// *************************************************************************** *
// *                                                                           *
// *                      Mentor Graphics Corporation                          *
// *                          All rights reserved                              *
// *                                                                           *
// *************************************************************************** *
// *                                                                           *
// * Description:         CANDB File                                           *
// * Generated at:        2022-07-01 13:40                                     *
// * System:              ZSDB122200                                           *
// * Variant:             DC1E_EU                                              *
// * Network:             BodyExposedCAN                                       *
// *                                                                           *
// *************************************************************************** *
// *                                                                           *
// *             THIS CONFIGURATION MIGHT CONTAIN SOME ERRORS                  *
// *              IF THE INPUT MODEL WAS NOT PROPERLY FORMED!                  *
// *                    Do Not Use this File directly!                         *
// *                                                                           *
// *************************************************************************** *
VERSION "BodyExposedCAN"

NS_ :

BS_ :

BU_ :  CEM ETC HCML HCMR RCML RCMM RCMR

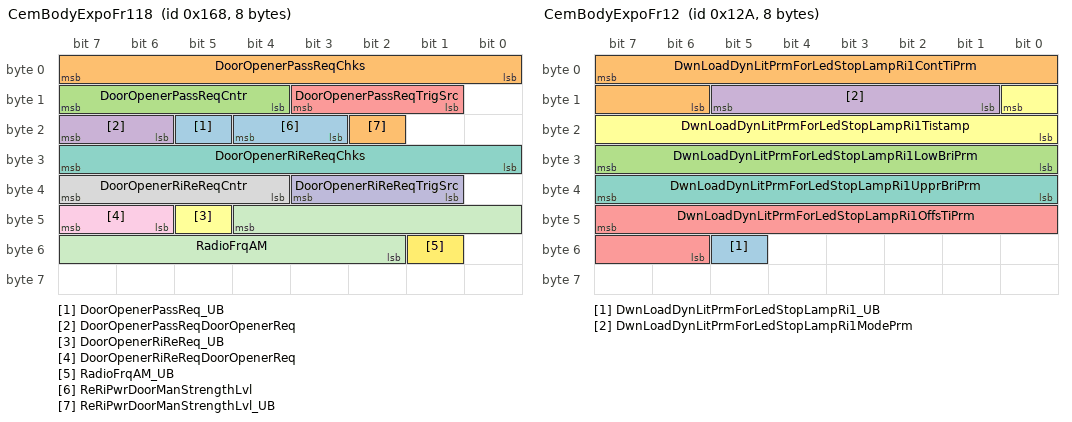
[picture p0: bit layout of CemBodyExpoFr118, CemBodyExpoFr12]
BO_ 360 CemBodyExpoFr118 : 8 CEM
 SG_ DoorOpenerPassReq_UB : 21|1@0+ (1,0) [0|1] "" Vector_XXX
 SG_ DoorOpenerPassReqChks : 7|8@0+ (1.0,0.0) [0.0|255.0] "Unitless" Vector_XXX
 SG_ DoorOpenerPassReqCntr : 15|4@0+ (1.0,0.0) [0.0|15.0] "Unitless" Vector_XXX
 SG_ DoorOpenerPassReqDoorOpenerReq : 23|2@0+ (1,0) [0|3] "" Vector_XXX
 SG_ DoorOpenerPassReqTrigSrc : 11|3@0+ (1,0) [0|7] "" Vector_XXX
 SG_ DoorOpenerRiReReq_UB : 45|1@0+ (1,0) [0|1] "" Vector_XXX
 SG_ DoorOpenerRiReReqChks : 31|8@0+ (1.0,0.0) [0.0|255.0] "Unitless" Vector_XXX
 SG_ DoorOpenerRiReReqCntr : 39|4@0+ (1.0,0.0) [0.0|15.0] "Unitless" Vector_XXX
 SG_ DoorOpenerRiReReqDoorOpenerReq : 47|2@0+ (1,0) [0|3] "" Vector_XXX
 SG_ DoorOpenerRiReReqTrigSrc : 35|3@0+ (1,0) [0|7] "" Vector_XXX
 SG_ RadioFrqAM : 44|11@0+ (1.0,522.0) [522.0|1710.0] "Unitless" Vector_XXX
 SG_ RadioFrqAM_UB : 49|1@0+ (1,0) [0|1] "" Vector_XXX
 SG_ ReRiPwrDoorManStrengthLvl : 20|2@0+ (1,0) [0|3] "" Vector_XXX
 SG_ ReRiPwrDoorManStrengthLvl_UB : 18|1@0+ (1,0) [0|1] "" Vector_XXX

BO_ 86 CemBodyExpoFr119 : 8 CEM
 SG_ DHUcontrolleftcorneringlamp : 7|2@0+ (1,0) [0|3] "" HCML
 SG_ DHUcontrolleftcorneringlamp_UB : 31|1@0+ (1,0) [0|1] "" HCML
 SG_ DHUcontrolleftdaytimerunninglamp : 5|2@0+ (1,0) [0|3] "" HCML
 SG_ DHUcontrolleftdaytimerunninglamp_UB : 30|1@0+ (1,0) [0|1] "" HCML
 SG_ DHUcontrolleftfroglight : 3|2@0+ (1,0) [0|3] "" HCML
 SG_ DHUcontrolleftfroglight_UB : 29|1@0+ (1,0) [0|1] "" HCML
 SG_ DHUcontrollefthighbeamlamp : 1|2@0+ (1,0) [0|3] "" HCML
 SG_ DHUcontrollefthighbeamlamp_UB : 28|1@0+ (1,0) [0|1] "" HCML
 SG_ DHUcontrolleftlowbeamlamp : 15|2@0+ (1,0) [0|3] "" HCML
 SG_ DHUcontrolleftlowbeamlamp_UB : 27|1@0+ (1,0) [0|1] "" HCML
 SG_ DHUcontrolleftpositionlamp : 13|2@0+ (1,0) [0|3] "" HCML
 SG_ DHUcontrolleftpositionlamp_UB : 26|1@0+ (1,0) [0|1] "" HCML
 SG_ DHUcontrolrightcorneringlamp : 11|2@0+ (1,0) [0|3] "" HCMR
 SG_ DHUcontrolrightcorneringlamp_UB : 25|1@0+ (1,0) [0|1] "" HCMR
 SG_ DHUcontrolrightdaytimerunninglamp : 9|2@0+ (1,0) [0|3] "" HCMR
 SG_ DHUcontrolrightdaytimerunninglamp_UB : 24|1@0+ (1,0) [0|1] "" HCMR
 SG_ DHUcontrolrightfroglight : 23|2@0+ (1,0) [0|3] "" HCMR
 SG_ DHUcontrolrightfroglight_UB : 39|1@0+ (1,0) [0|1] "" HCMR
 SG_ DHUcontrolrighthighbeamlamp : 21|2@0+ (1,0) [0|3] "" HCMR
 SG_ DHUcontrolrighthighbeamlamp_UB : 38|1@0+ (1,0) [0|1] "" HCMR
 SG_ DHUcontrolrightlowbeamlamp : 19|2@0+ (1,0) [0|3] "" HCMR
 SG_ DHUcontrolrightlowbeamlamp_UB : 37|1@0+ (1,0) [0|1] "" HCMR
 SG_ DHUcontrolrightpositionLamp : 17|2@0+ (1,0) [0|3] "" HCMR
 SG_ DHUcontrolrightpositionLamp_UB : 36|1@0+ (1,0) [0|1] "" HCMR

BO_ 298 CemBodyExpoFr12 : 8 CEM
 SG_ DwnLoadDynLitPrmForLedStopLampRi1_UB : 53|1@0+ (1,0) [0|1] "" RCMR
 SG_ DwnLoadDynLitPrmForLedStopLampRi1ContTiPrm : 7|10@0+ (1.0,0.0) [0.0|1000.0] "Milliseconds" RCMR
 SG_ DwnLoadDynLitPrmForLedStopLampRi1LowBriPrm : 31|8@0+ (1.0,0.0) [0.0|100.0] "%" RCMR
 SG_ DwnLoadDynLitPrmForLedStopLampRi1ModePrm : 13|5@0+ (1,0) [0|31] "" RCMR
 SG_ DwnLoadDynLitPrmForLedStopLampRi1OffsTiPrm : 47|10@0+ (1.0,0.0) [0.0|1000.0] "Milliseconds" RCMR
 SG_ DwnLoadDynLitPrmForLedStopLampRi1Tistamp : 8|9@0+ (1.0,0.0) [0.0|511.0] "Unitless" RCMR
 SG_ DwnLoadDynLitPrmForLedStopLampRi1UpprBriPrm : 39|8@0+ (1.0,0.0) [0.0|100.0] "%" RCMR

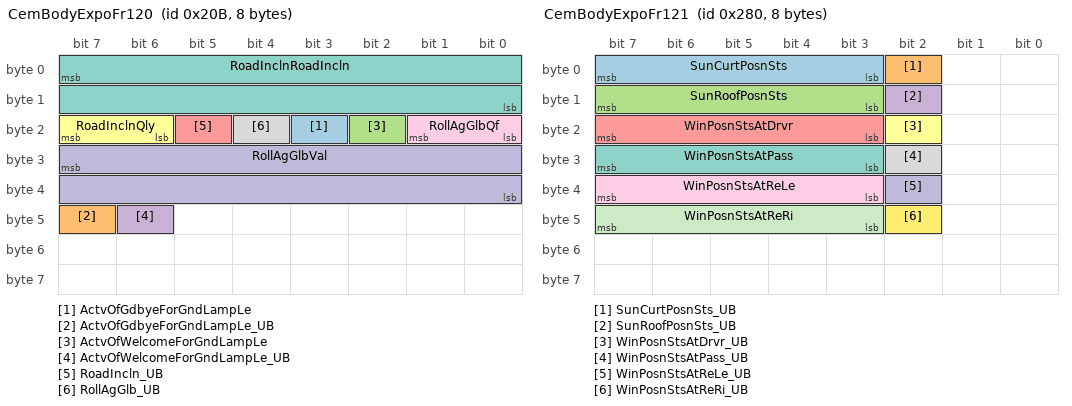
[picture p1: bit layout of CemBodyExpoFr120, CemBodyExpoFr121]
BO_ 523 CemBodyExpoFr120 : 8 CEM
 SG_ ActvOfGdbyeForGndLampLe : 19|1@0+ (1,0) [0|1] "" Vector_XXX
 SG_ ActvOfGdbyeForGndLampLe_UB : 47|1@0+ (1,0) [0|1] "" Vector_XXX
 SG_ ActvOfWelcomeForGndLampLe : 18|1@0+ (1,0) [0|1] "" Vector_XXX
 SG_ ActvOfWelcomeForGndLampLe_UB : 46|1@0+ (1,0) [0|1] "" Vector_XXX
 SG_ RoadIncln_UB : 21|1@0+ (1,0) [0|1] "" Vector_XXX
 SG_ RoadInclnQly : 23|2@0+ (1,0) [0|3] "" Vector_XXX
 SG_ RoadInclnRoadIncln : 7|16@0- (0.000030518,0.0) [-0.9999833060000001|0.9999833060000001] "rad" Vector_XXX
 SG_ RollAgGlb_UB : 20|1@0+ (1,0) [0|1] "" Vector_XXX
 SG_ RollAgGlbQf : 17|2@0+ (1,0) [0|3] "" Vector_XXX
 SG_ RollAgGlbVal : 31|16@0- (0.000030518,0.0) [-0.9999833060000001|0.9999833060000001] "rad" Vector_XXX

BO_ 640 CemBodyExpoFr121 : 8 CEM
 SG_ SunCurtPosnSts : 7|5@0+ (1,0) [0|31] "" Vector_XXX
 SG_ SunCurtPosnSts_UB : 2|1@0+ (1,0) [0|1] "" Vector_XXX
 SG_ SunRoofPosnSts : 15|5@0+ (1,0) [0|31] "" Vector_XXX
 SG_ SunRoofPosnSts_UB : 10|1@0+ (1,0) [0|1] "" Vector_XXX
 SG_ WinPosnStsAtDrvr : 23|5@0+ (1,0) [0|31] "" Vector_XXX
 SG_ WinPosnStsAtDrvr_UB : 18|1@0+ (1,0) [0|1] "" Vector_XXX
 SG_ WinPosnStsAtPass : 31|5@0+ (1,0) [0|31] "" Vector_XXX
 SG_ WinPosnStsAtPass_UB : 26|1@0+ (1,0) [0|1] "" Vector_XXX
 SG_ WinPosnStsAtReLe : 39|5@0+ (1,0) [0|31] "" Vector_XXX
 SG_ WinPosnStsAtReLe_UB : 34|1@0+ (1,0) [0|1] "" Vector_XXX
 SG_ WinPosnStsAtReRi : 47|5@0+ (1,0) [0|31] "" Vector_XXX
 SG_ WinPosnStsAtReRi_UB : 42|1@0+ (1,0) [0|1] "" Vector_XXX

BO_ 1110 CemBodyExpoFr122 : 8 CEM
 SG_ VFCInfoEna : 7|1@0+ (1,0) [0|1] "" Vector_XXX
 SG_ VFCInfoEna_UB : 6|1@0+ (1,0) [0|1] "" Vector_XXX

BO_ 359 CemBodyExpoFr123 : 8 CEM
 SG_ CarpetLiSet_UB : 19|1@0+ (1,0) [0|1] "" Vector_XXX
 SG_ CarpetLiSetCarpetLiSet : 15|2@0+ (1,0) [0|3] "" Vector_XXX
 SG_ CarpetLiSetPerc12 : 7|8@0+ (1.0,0.0) [0.0|255.0] "%" Vector_XXX
 SG_ CarpetLiTrialSet_UB : 18|1@0+ (1,0) [0|1] "" Vector_XXX
 SG_ CarpetLiTrialSetPerc12 : 13|8@0+ (1.0,0.0) [0.0|255.0] "%" Vector_XXX
 SG_ CarpetLiTrialSetTrialSet : 21|2@0+ (1,0) [0|3] "" Vector_XXX

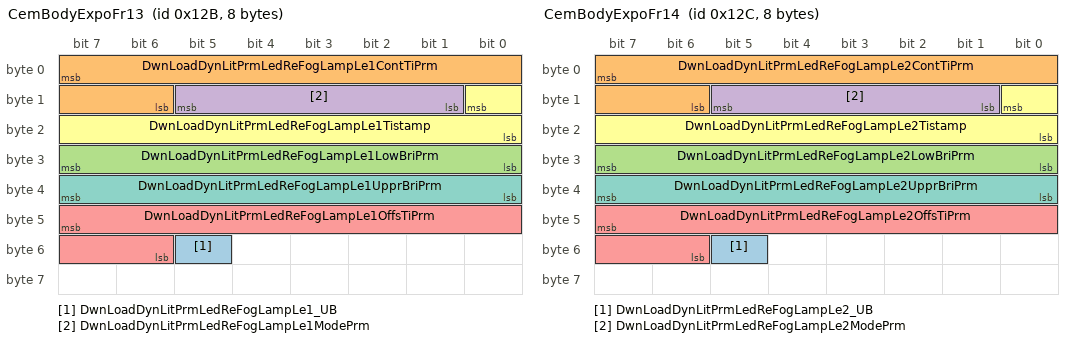
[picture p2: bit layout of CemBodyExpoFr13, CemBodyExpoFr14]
BO_ 299 CemBodyExpoFr13 : 8 CEM
 SG_ DwnLoadDynLitPrmLedReFogLampLe1_UB : 53|1@0+ (1,0) [0|1] "" RCML
 SG_ DwnLoadDynLitPrmLedReFogLampLe1ContTiPrm : 7|10@0+ (1.0,0.0) [0.0|1000.0] "Milliseconds" RCML
 SG_ DwnLoadDynLitPrmLedReFogLampLe1LowBriPrm : 31|8@0+ (1.0,0.0) [0.0|100.0] "%" RCML
 SG_ DwnLoadDynLitPrmLedReFogLampLe1ModePrm : 13|5@0+ (1,0) [0|31] "" RCML
 SG_ DwnLoadDynLitPrmLedReFogLampLe1OffsTiPrm : 47|10@0+ (1.0,0.0) [0.0|1000.0] "Milliseconds" RCML
 SG_ DwnLoadDynLitPrmLedReFogLampLe1Tistamp : 8|9@0+ (1.0,0.0) [0.0|511.0] "Unitless" RCML
 SG_ DwnLoadDynLitPrmLedReFogLampLe1UpprBriPrm : 39|8@0+ (1.0,0.0) [0.0|100.0] "%" RCML

BO_ 300 CemBodyExpoFr14 : 8 CEM
 SG_ DwnLoadDynLitPrmLedReFogLampLe2_UB : 53|1@0+ (1,0) [0|1] "" RCML,RCMM
 SG_ DwnLoadDynLitPrmLedReFogLampLe2ContTiPrm : 7|10@0+ (1.0,0.0) [0.0|1000.0] "Milliseconds" RCML,RCMM
 SG_ DwnLoadDynLitPrmLedReFogLampLe2LowBriPrm : 31|8@0+ (1.0,0.0) [0.0|100.0] "%" RCML,RCMM
 SG_ DwnLoadDynLitPrmLedReFogLampLe2ModePrm : 13|5@0+ (1,0) [0|31] "" RCML,RCMM
 SG_ DwnLoadDynLitPrmLedReFogLampLe2OffsTiPrm : 47|10@0+ (1.0,0.0) [0.0|1000.0] "Milliseconds" RCML,RCMM
 SG_ DwnLoadDynLitPrmLedReFogLampLe2Tistamp : 8|9@0+ (1.0,0.0) [0.0|511.0] "Unitless" RCML,RCMM
 SG_ DwnLoadDynLitPrmLedReFogLampLe2UpprBriPrm : 39|8@0+ (1.0,0.0) [0.0|100.0] "%" RCML,RCMM

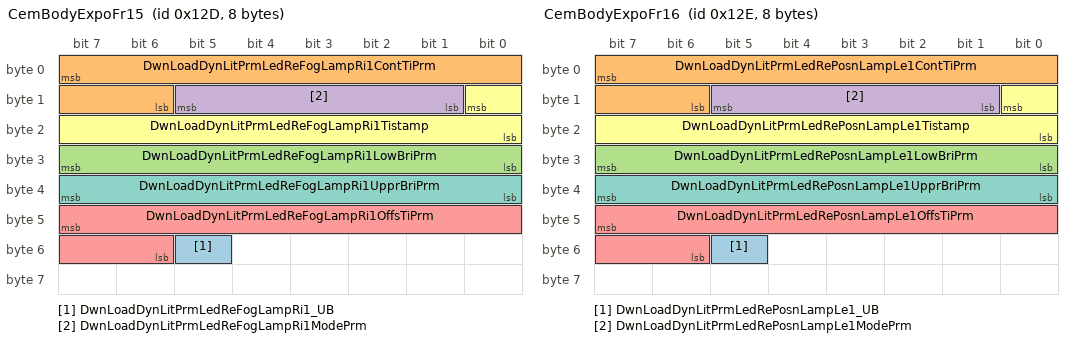
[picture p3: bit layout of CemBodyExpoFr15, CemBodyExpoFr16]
BO_ 301 CemBodyExpoFr15 : 8 CEM
 SG_ DwnLoadDynLitPrmLedReFogLampRi1_UB : 53|1@0+ (1,0) [0|1] "" RCMR
 SG_ DwnLoadDynLitPrmLedReFogLampRi1ContTiPrm : 7|10@0+ (1.0,0.0) [0.0|1000.0] "Milliseconds" RCMR
 SG_ DwnLoadDynLitPrmLedReFogLampRi1LowBriPrm : 31|8@0+ (1.0,0.0) [0.0|100.0] "%" RCMR
 SG_ DwnLoadDynLitPrmLedReFogLampRi1ModePrm : 13|5@0+ (1,0) [0|31] "" RCMR
 SG_ DwnLoadDynLitPrmLedReFogLampRi1OffsTiPrm : 47|10@0+ (1.0,0.0) [0.0|1000.0] "Milliseconds" RCMR
 SG_ DwnLoadDynLitPrmLedReFogLampRi1Tistamp : 8|9@0+ (1.0,0.0) [0.0|511.0] "Unitless" RCMR
 SG_ DwnLoadDynLitPrmLedReFogLampRi1UpprBriPrm : 39|8@0+ (1.0,0.0) [0.0|100.0] "%" RCMR

BO_ 302 CemBodyExpoFr16 : 8 CEM
 SG_ DwnLoadDynLitPrmLedRePosnLampLe1_UB : 53|1@0+ (1,0) [0|1] "" RCML
 SG_ DwnLoadDynLitPrmLedRePosnLampLe1ContTiPrm : 7|10@0+ (1.0,0.0) [0.0|1000.0] "Milliseconds" RCML
 SG_ DwnLoadDynLitPrmLedRePosnLampLe1LowBriPrm : 31|8@0+ (1.0,0.0) [0.0|100.0] "%" RCML
 SG_ DwnLoadDynLitPrmLedRePosnLampLe1ModePrm : 13|5@0+ (1,0) [0|31] "" RCML
 SG_ DwnLoadDynLitPrmLedRePosnLampLe1OffsTiPrm : 47|10@0+ (1.0,0.0) [0.0|1000.0] "Milliseconds" RCML
 SG_ DwnLoadDynLitPrmLedRePosnLampLe1Tistamp : 8|9@0+ (1.0,0.0) [0.0|511.0] "Unitless" RCML
 SG_ DwnLoadDynLitPrmLedRePosnLampLe1UpprBriPrm : 39|8@0+ (1.0,0.0) [0.0|100.0] "%" RCML

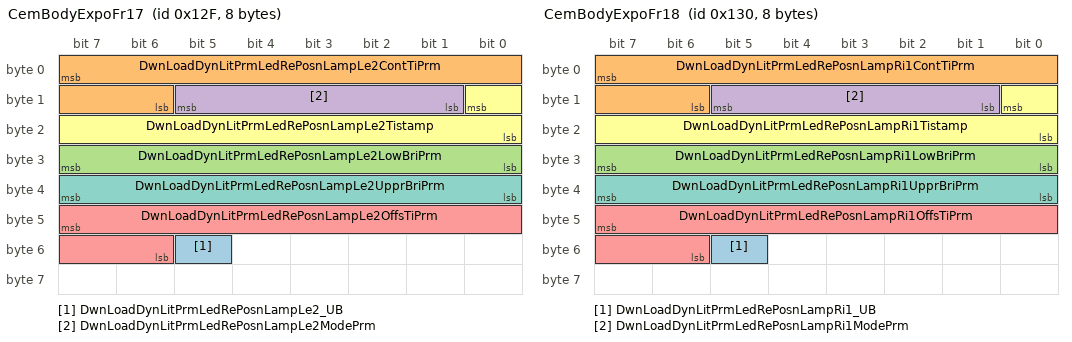
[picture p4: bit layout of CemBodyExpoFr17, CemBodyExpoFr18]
BO_ 303 CemBodyExpoFr17 : 8 CEM
 SG_ DwnLoadDynLitPrmLedRePosnLampLe2_UB : 53|1@0+ (1,0) [0|1] "" RCML,RCMM
 SG_ DwnLoadDynLitPrmLedRePosnLampLe2ContTiPrm : 7|10@0+ (1.0,0.0) [0.0|1000.0] "Milliseconds" RCML,RCMM
 SG_ DwnLoadDynLitPrmLedRePosnLampLe2LowBriPrm : 31|8@0+ (1.0,0.0) [0.0|100.0] "%" RCML,RCMM
 SG_ DwnLoadDynLitPrmLedRePosnLampLe2ModePrm : 13|5@0+ (1,0) [0|31] "" RCML,RCMM
 SG_ DwnLoadDynLitPrmLedRePosnLampLe2OffsTiPrm : 47|10@0+ (1.0,0.0) [0.0|1000.0] "Milliseconds" RCML,RCMM
 SG_ DwnLoadDynLitPrmLedRePosnLampLe2Tistamp : 8|9@0+ (1.0,0.0) [0.0|511.0] "Unitless" RCML,RCMM
 SG_ DwnLoadDynLitPrmLedRePosnLampLe2UpprBriPrm : 39|8@0+ (1.0,0.0) [0.0|100.0] "%" RCML,RCMM

BO_ 304 CemBodyExpoFr18 : 8 CEM
 SG_ DwnLoadDynLitPrmLedRePosnLampRi1_UB : 53|1@0+ (1,0) [0|1] "" RCMR
 SG_ DwnLoadDynLitPrmLedRePosnLampRi1ContTiPrm : 7|10@0+ (1.0,0.0) [0.0|1000.0] "Milliseconds" RCMR
 SG_ DwnLoadDynLitPrmLedRePosnLampRi1LowBriPrm : 31|8@0+ (1.0,0.0) [0.0|100.0] "%" RCMR
 SG_ DwnLoadDynLitPrmLedRePosnLampRi1ModePrm : 13|5@0+ (1,0) [0|31] "" RCMR
 SG_ DwnLoadDynLitPrmLedRePosnLampRi1OffsTiPrm : 47|10@0+ (1.0,0.0) [0.0|1000.0] "Milliseconds" RCMR
 SG_ DwnLoadDynLitPrmLedRePosnLampRi1Tistamp : 8|9@0+ (1.0,0.0) [0.0|511.0] "Unitless" RCMR
 SG_ DwnLoadDynLitPrmLedRePosnLampRi1UpprBriPrm : 39|8@0+ (1.0,0.0) [0.0|100.0] "%" RCMR

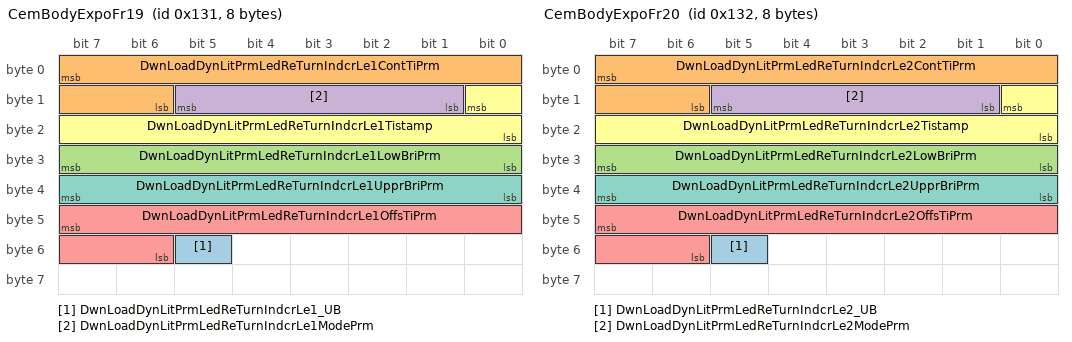
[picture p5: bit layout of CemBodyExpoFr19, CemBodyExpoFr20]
BO_ 305 CemBodyExpoFr19 : 8 CEM
 SG_ DwnLoadDynLitPrmLedReTurnIndcrLe1_UB : 53|1@0+ (1,0) [0|1] "" RCML
 SG_ DwnLoadDynLitPrmLedReTurnIndcrLe1ContTiPrm : 7|10@0+ (1.0,0.0) [0.0|1000.0] "Milliseconds" RCML
 SG_ DwnLoadDynLitPrmLedReTurnIndcrLe1LowBriPrm : 31|8@0+ (1.0,0.0) [0.0|100.0] "%" RCML
 SG_ DwnLoadDynLitPrmLedReTurnIndcrLe1ModePrm : 13|5@0+ (1,0) [0|31] "" RCML
 SG_ DwnLoadDynLitPrmLedReTurnIndcrLe1OffsTiPrm : 47|10@0+ (1.0,0.0) [0.0|1000.0] "Milliseconds" RCML
 SG_ DwnLoadDynLitPrmLedReTurnIndcrLe1Tistamp : 8|9@0+ (1.0,0.0) [0.0|511.0] "Unitless" RCML
 SG_ DwnLoadDynLitPrmLedReTurnIndcrLe1UpprBriPrm : 39|8@0+ (1.0,0.0) [0.0|100.0] "%" RCML

BO_ 306 CemBodyExpoFr20 : 8 CEM
 SG_ DwnLoadDynLitPrmLedReTurnIndcrLe2_UB : 53|1@0+ (1,0) [0|1] "" RCML,RCMM
 SG_ DwnLoadDynLitPrmLedReTurnIndcrLe2ContTiPrm : 7|10@0+ (1.0,0.0) [0.0|1000.0] "Milliseconds" RCML,RCMM
 SG_ DwnLoadDynLitPrmLedReTurnIndcrLe2LowBriPrm : 31|8@0+ (1.0,0.0) [0.0|100.0] "%" RCML,RCMM
 SG_ DwnLoadDynLitPrmLedReTurnIndcrLe2ModePrm : 13|5@0+ (1,0) [0|31] "" RCML,RCMM
 SG_ DwnLoadDynLitPrmLedReTurnIndcrLe2OffsTiPrm : 47|10@0+ (1.0,0.0) [0.0|1000.0] "Milliseconds" RCML,RCMM
 SG_ DwnLoadDynLitPrmLedReTurnIndcrLe2Tistamp : 8|9@0+ (1.0,0.0) [0.0|511.0] "Unitless" RCML,RCMM
 SG_ DwnLoadDynLitPrmLedReTurnIndcrLe2UpprBriPrm : 39|8@0+ (1.0,0.0) [0.0|100.0] "%" RCML,RCMM

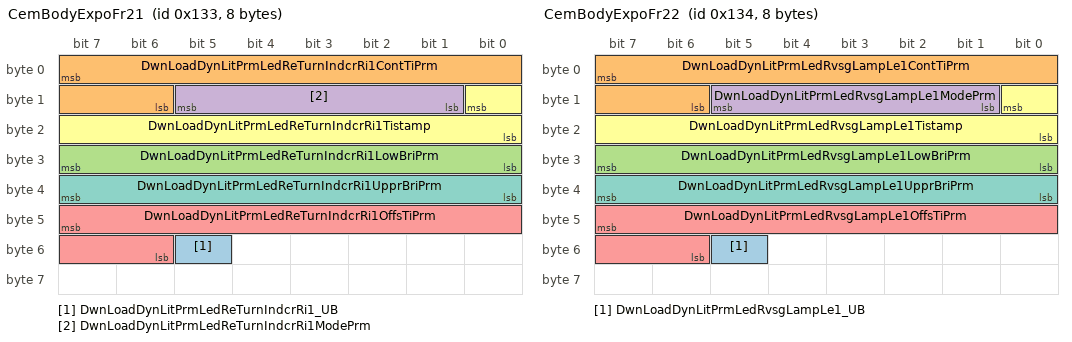
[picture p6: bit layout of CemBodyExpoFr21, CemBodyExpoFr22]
BO_ 307 CemBodyExpoFr21 : 8 CEM
 SG_ DwnLoadDynLitPrmLedReTurnIndcrRi1_UB : 53|1@0+ (1,0) [0|1] "" RCMR
 SG_ DwnLoadDynLitPrmLedReTurnIndcrRi1ContTiPrm : 7|10@0+ (1.0,0.0) [0.0|1000.0] "Milliseconds" RCMR
 SG_ DwnLoadDynLitPrmLedReTurnIndcrRi1LowBriPrm : 31|8@0+ (1.0,0.0) [0.0|100.0] "%" RCMR
 SG_ DwnLoadDynLitPrmLedReTurnIndcrRi1ModePrm : 13|5@0+ (1,0) [0|31] "" RCMR
 SG_ DwnLoadDynLitPrmLedReTurnIndcrRi1OffsTiPrm : 47|10@0+ (1.0,0.0) [0.0|1000.0] "Milliseconds" RCMR
 SG_ DwnLoadDynLitPrmLedReTurnIndcrRi1Tistamp : 8|9@0+ (1.0,0.0) [0.0|511.0] "Unitless" RCMR
 SG_ DwnLoadDynLitPrmLedReTurnIndcrRi1UpprBriPrm : 39|8@0+ (1.0,0.0) [0.0|100.0] "%" RCMR

BO_ 308 CemBodyExpoFr22 : 8 CEM
 SG_ DwnLoadDynLitPrmLedRvsgLampLe1_UB : 53|1@0+ (1,0) [0|1] "" RCML
 SG_ DwnLoadDynLitPrmLedRvsgLampLe1ContTiPrm : 7|10@0+ (1.0,0.0) [0.0|1000.0] "Milliseconds" RCML
 SG_ DwnLoadDynLitPrmLedRvsgLampLe1LowBriPrm : 31|8@0+ (1.0,0.0) [0.0|100.0] "%" RCML
 SG_ DwnLoadDynLitPrmLedRvsgLampLe1ModePrm : 13|5@0+ (1,0) [0|31] "" RCML
 SG_ DwnLoadDynLitPrmLedRvsgLampLe1OffsTiPrm : 47|10@0+ (1.0,0.0) [0.0|1000.0] "Milliseconds" RCML
 SG_ DwnLoadDynLitPrmLedRvsgLampLe1Tistamp : 8|9@0+ (1.0,0.0) [0.0|511.0] "Unitless" RCML
 SG_ DwnLoadDynLitPrmLedRvsgLampLe1UpprBriPrm : 39|8@0+ (1.0,0.0) [0.0|100.0] "%" RCML

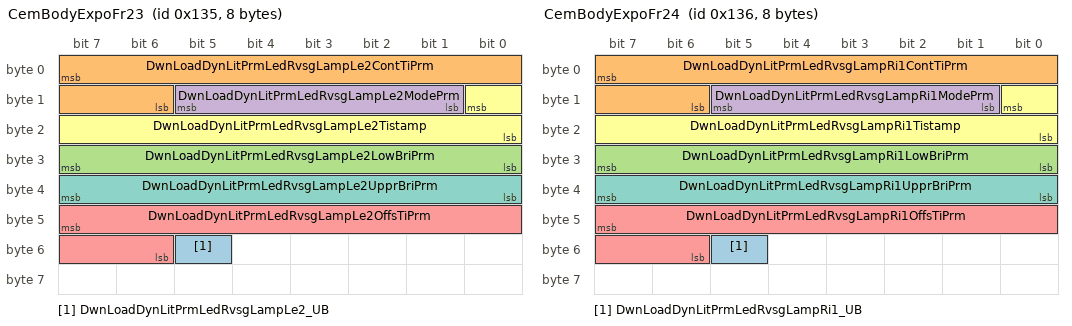
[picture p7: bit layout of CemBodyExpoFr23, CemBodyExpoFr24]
BO_ 309 CemBodyExpoFr23 : 8 CEM
 SG_ DwnLoadDynLitPrmLedRvsgLampLe2_UB : 53|1@0+ (1,0) [0|1] "" RCML,RCMM
 SG_ DwnLoadDynLitPrmLedRvsgLampLe2ContTiPrm : 7|10@0+ (1.0,0.0) [0.0|1000.0] "Milliseconds" RCML,RCMM
 SG_ DwnLoadDynLitPrmLedRvsgLampLe2LowBriPrm : 31|8@0+ (1.0,0.0) [0.0|100.0] "%" RCML,RCMM
 SG_ DwnLoadDynLitPrmLedRvsgLampLe2ModePrm : 13|5@0+ (1,0) [0|31] "" RCML,RCMM
 SG_ DwnLoadDynLitPrmLedRvsgLampLe2OffsTiPrm : 47|10@0+ (1.0,0.0) [0.0|1000.0] "Milliseconds" RCML,RCMM
 SG_ DwnLoadDynLitPrmLedRvsgLampLe2Tistamp : 8|9@0+ (1.0,0.0) [0.0|511.0] "Unitless" RCML,RCMM
 SG_ DwnLoadDynLitPrmLedRvsgLampLe2UpprBriPrm : 39|8@0+ (1.0,0.0) [0.0|100.0] "%" RCML,RCMM

BO_ 310 CemBodyExpoFr24 : 8 CEM
 SG_ DwnLoadDynLitPrmLedRvsgLampRi1_UB : 53|1@0+ (1,0) [0|1] "" RCMR
 SG_ DwnLoadDynLitPrmLedRvsgLampRi1ContTiPrm : 7|10@0+ (1.0,0.0) [0.0|1000.0] "Milliseconds" RCMR
 SG_ DwnLoadDynLitPrmLedRvsgLampRi1LowBriPrm : 31|8@0+ (1.0,0.0) [0.0|100.0] "%" RCMR
 SG_ DwnLoadDynLitPrmLedRvsgLampRi1ModePrm : 13|5@0+ (1,0) [0|31] "" RCMR
 SG_ DwnLoadDynLitPrmLedRvsgLampRi1OffsTiPrm : 47|10@0+ (1.0,0.0) [0.0|1000.0] "Milliseconds" RCMR
 SG_ DwnLoadDynLitPrmLedRvsgLampRi1Tistamp : 8|9@0+ (1.0,0.0) [0.0|511.0] "Unitless" RCMR
 SG_ DwnLoadDynLitPrmLedRvsgLampRi1UpprBriPrm : 39|8@0+ (1.0,0.0) [0.0|100.0] "%" RCMR

BO_ 120 CemBodyExpoFr25 : 8 CEM
 SG_ CarpetLiModReq : 6|4@0+ (1,0) [0|15] "" Vector_XXX
 SG_ CarpetLiModReq_UB : 2|1@0+ (1,0) [0|1] "" Vector_XXX
 SG_ CarpetLiSwtReq : 1|1@0+ (1,0) [0|1] "" Vector_XXX
 SG_ CarpetLiSwtReq_UB : 0|1@0+ (1,0) [0|1] "" Vector_XXX
 SG_ CarpetLiTiReq : 15|4@0+ (1,0) [0|15] "" Vector_XXX
 SG_ CarpetLiTiReq_UB : 11|1@0+ (1,0) [0|1] "" Vector_XXX
 SG_ DoorLeRePercSetFromHmi : 31|7@0+ (1.0,0.0) [0.0|101.0] "%" Vector_XXX
 SG_ DoorLeRePercSetFromHmi_UB : 24|1@0+ (1,0) [0|1] "" Vector_XXX
 SG_ DrvrPwrDoorManStrengthLvl : 10|2@0+ (1,0) [0|3] "" Vector_XXX
 SG_ DrvrPwrDoorManStrengthLvl_UB : 8|1@0+ (1,0) [0|1] "" Vector_XXX
 SG_ HvacRecircAct : 23|7@0+ (1.0,0.0) [0.0|100.0] "%" Vector_XXX
 SG_ HvacRecircAct_UB : 16|1@0+ (1,0) [0|1] "" Vector_XXX
 SG_ LvlgSwtSetReq_UB : 55|1@0+ (1,0) [0|1] "" HCML,HCMR
 SG_ LvlgSwtSetReqADModCtrlInhbn : 54|3@0+ (1,0) [0|7] "" HCML,HCMR
 SG_ LvlgSwtSetReqChks : 63|8@0+ (1.0,0.0) [0.0|255.0] "Unitless" HCML,HCMR
 SG_ LvlgSwtSetReqCntr : 51|4@0+ (1.0,0.0) [0.0|15.0] "Unitless" HCML,HCMR
 SG_ OutdBri_UB : 38|1@0+ (1,0) [0|1] "" HCML,HCMR
 SG_ OutdBriChks : 47|8@0+ (1.0,0.0) [0.0|255.0] "Unitless" HCML,HCMR
 SG_ OutdBriCntr : 35|4@0+ (1.0,0.0) [0.0|15.0] "Unitless" HCML,HCMR
 SG_ OutdBriSts : 37|2@0+ (1,0) [0|3] "" HCML,HCMR

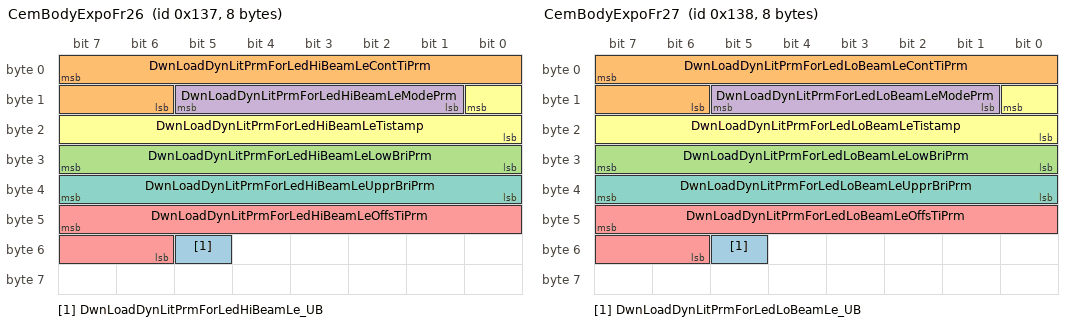
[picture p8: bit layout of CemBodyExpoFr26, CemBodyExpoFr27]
BO_ 311 CemBodyExpoFr26 : 8 CEM
 SG_ DwnLoadDynLitPrmForLedHiBeamLe_UB : 53|1@0+ (1,0) [0|1] "" HCML
 SG_ DwnLoadDynLitPrmForLedHiBeamLeContTiPrm : 7|10@0+ (1.0,0.0) [0.0|1000.0] "Milliseconds" HCML
 SG_ DwnLoadDynLitPrmForLedHiBeamLeLowBriPrm : 31|8@0+ (1.0,0.0) [0.0|100.0] "%" HCML
 SG_ DwnLoadDynLitPrmForLedHiBeamLeModePrm : 13|5@0+ (1,0) [0|31] "" HCML
 SG_ DwnLoadDynLitPrmForLedHiBeamLeOffsTiPrm : 47|10@0+ (1.0,0.0) [0.0|1000.0] "Milliseconds" HCML
 SG_ DwnLoadDynLitPrmForLedHiBeamLeTistamp : 8|9@0+ (1.0,0.0) [0.0|511.0] "Unitless" HCML
 SG_ DwnLoadDynLitPrmForLedHiBeamLeUpprBriPrm : 39|8@0+ (1.0,0.0) [0.0|100.0] "%" HCML

BO_ 312 CemBodyExpoFr27 : 8 CEM
 SG_ DwnLoadDynLitPrmForLedLoBeamLe_UB : 53|1@0+ (1,0) [0|1] "" HCML
 SG_ DwnLoadDynLitPrmForLedLoBeamLeContTiPrm : 7|10@0+ (1.0,0.0) [0.0|1000.0] "Milliseconds" HCML
 SG_ DwnLoadDynLitPrmForLedLoBeamLeLowBriPrm : 31|8@0+ (1.0,0.0) [0.0|100.0] "%" HCML
 SG_ DwnLoadDynLitPrmForLedLoBeamLeModePrm : 13|5@0+ (1,0) [0|31] "" HCML
 SG_ DwnLoadDynLitPrmForLedLoBeamLeOffsTiPrm : 47|10@0+ (1.0,0.0) [0.0|1000.0] "Milliseconds" HCML
 SG_ DwnLoadDynLitPrmForLedLoBeamLeTistamp : 8|9@0+ (1.0,0.0) [0.0|511.0] "Unitless" HCML
 SG_ DwnLoadDynLitPrmForLedLoBeamLeUpprBriPrm : 39|8@0+ (1.0,0.0) [0.0|100.0] "%" HCML

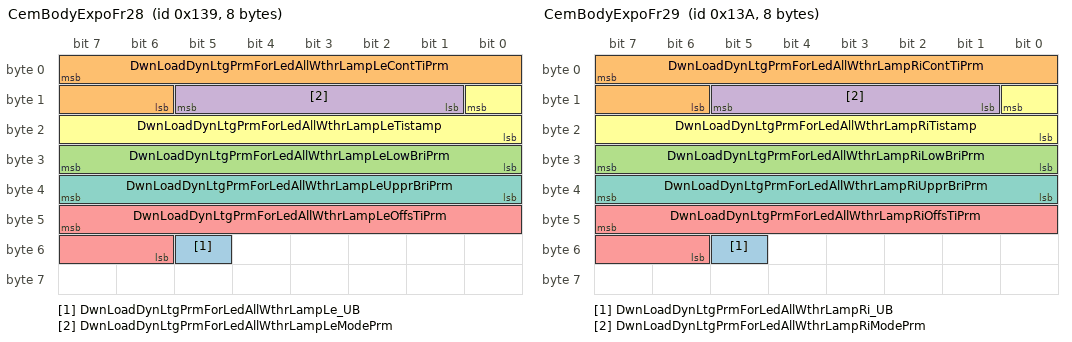
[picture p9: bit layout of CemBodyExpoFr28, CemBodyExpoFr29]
BO_ 313 CemBodyExpoFr28 : 8 CEM
 SG_ DwnLoadDynLtgPrmForLedAllWthrLampLe_UB : 53|1@0+ (1,0) [0|1] "" HCML
 SG_ DwnLoadDynLtgPrmForLedAllWthrLampLeContTiPrm : 7|10@0+ (1.0,0.0) [0.0|1000.0] "Milliseconds" HCML
 SG_ DwnLoadDynLtgPrmForLedAllWthrLampLeLowBriPrm : 31|8@0+ (1.0,0.0) [0.0|100.0] "%" HCML
 SG_ DwnLoadDynLtgPrmForLedAllWthrLampLeModePrm : 13|5@0+ (1,0) [0|31] "" HCML
 SG_ DwnLoadDynLtgPrmForLedAllWthrLampLeOffsTiPrm : 47|10@0+ (1.0,0.0) [0.0|1000.0] "Milliseconds" HCML
 SG_ DwnLoadDynLtgPrmForLedAllWthrLampLeTistamp : 8|9@0+ (1.0,0.0) [0.0|511.0] "Unitless" HCML
 SG_ DwnLoadDynLtgPrmForLedAllWthrLampLeUpprBriPrm : 39|8@0+ (1.0,0.0) [0.0|100.0] "%" HCML

BO_ 314 CemBodyExpoFr29 : 8 CEM
 SG_ DwnLoadDynLtgPrmForLedAllWthrLampRi_UB : 53|1@0+ (1,0) [0|1] "" HCMR
 SG_ DwnLoadDynLtgPrmForLedAllWthrLampRiContTiPrm : 7|10@0+ (1.0,0.0) [0.0|1000.0] "Milliseconds" HCMR
 SG_ DwnLoadDynLtgPrmForLedAllWthrLampRiLowBriPrm : 31|8@0+ (1.0,0.0) [0.0|100.0] "%" HCMR
 SG_ DwnLoadDynLtgPrmForLedAllWthrLampRiModePrm : 13|5@0+ (1,0) [0|31] "" HCMR
 SG_ DwnLoadDynLtgPrmForLedAllWthrLampRiOffsTiPrm : 47|10@0+ (1.0,0.0) [0.0|1000.0] "Milliseconds" HCMR
 SG_ DwnLoadDynLtgPrmForLedAllWthrLampRiTistamp : 8|9@0+ (1.0,0.0) [0.0|511.0] "Unitless" HCMR
 SG_ DwnLoadDynLtgPrmForLedAllWthrLampRiUpprBriPrm : 39|8@0+ (1.0,0.0) [0.0|100.0] "%" HCMR

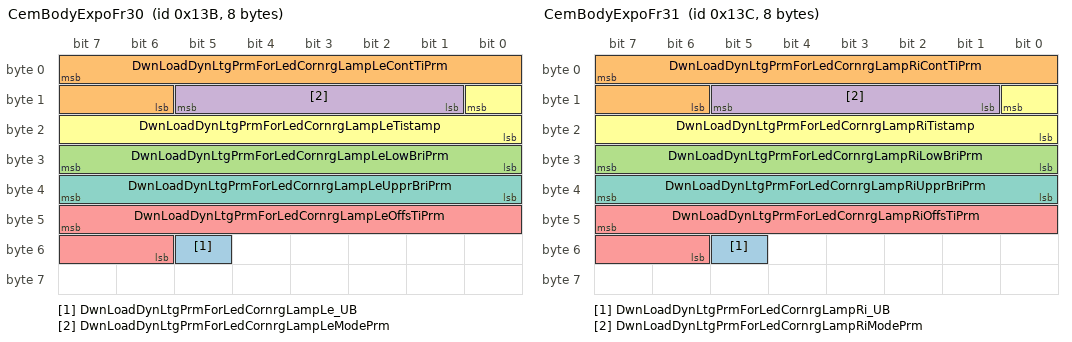
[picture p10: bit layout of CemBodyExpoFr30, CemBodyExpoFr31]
BO_ 315 CemBodyExpoFr30 : 8 CEM
 SG_ DwnLoadDynLtgPrmForLedCornrgLampLe_UB : 53|1@0+ (1,0) [0|1] "" HCML
 SG_ DwnLoadDynLtgPrmForLedCornrgLampLeContTiPrm : 7|10@0+ (1.0,0.0) [0.0|1000.0] "Milliseconds" HCML
 SG_ DwnLoadDynLtgPrmForLedCornrgLampLeLowBriPrm : 31|8@0+ (1.0,0.0) [0.0|100.0] "%" HCML
 SG_ DwnLoadDynLtgPrmForLedCornrgLampLeModePrm : 13|5@0+ (1,0) [0|31] "" HCML
 SG_ DwnLoadDynLtgPrmForLedCornrgLampLeOffsTiPrm : 47|10@0+ (1.0,0.0) [0.0|1000.0] "Milliseconds" HCML
 SG_ DwnLoadDynLtgPrmForLedCornrgLampLeTistamp : 8|9@0+ (1.0,0.0) [0.0|511.0] "Unitless" HCML
 SG_ DwnLoadDynLtgPrmForLedCornrgLampLeUpprBriPrm : 39|8@0+ (1.0,0.0) [0.0|100.0] "%" HCML

BO_ 316 CemBodyExpoFr31 : 8 CEM
 SG_ DwnLoadDynLtgPrmForLedCornrgLampRi_UB : 53|1@0+ (1,0) [0|1] "" HCMR
 SG_ DwnLoadDynLtgPrmForLedCornrgLampRiContTiPrm : 7|10@0+ (1.0,0.0) [0.0|1000.0] "Milliseconds" HCMR
 SG_ DwnLoadDynLtgPrmForLedCornrgLampRiLowBriPrm : 31|8@0+ (1.0,0.0) [0.0|100.0] "%" HCMR
 SG_ DwnLoadDynLtgPrmForLedCornrgLampRiModePrm : 13|5@0+ (1,0) [0|31] "" HCMR
 SG_ DwnLoadDynLtgPrmForLedCornrgLampRiOffsTiPrm : 47|10@0+ (1.0,0.0) [0.0|1000.0] "Milliseconds" HCMR
 SG_ DwnLoadDynLtgPrmForLedCornrgLampRiTistamp : 8|9@0+ (1.0,0.0) [0.0|511.0] "Unitless" HCMR
 SG_ DwnLoadDynLtgPrmForLedCornrgLampRiUpprBriPrm : 39|8@0+ (1.0,0.0) [0.0|100.0] "%" HCMR

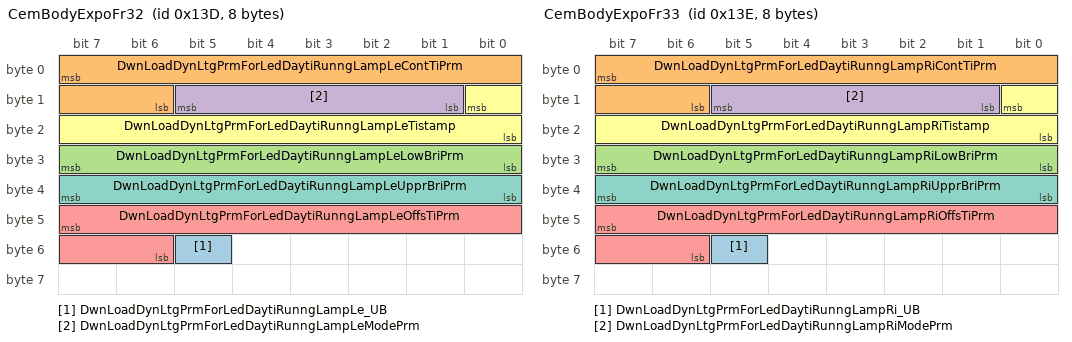
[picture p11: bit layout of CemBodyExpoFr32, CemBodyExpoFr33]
BO_ 317 CemBodyExpoFr32 : 8 CEM
 SG_ DwnLoadDynLtgPrmForLedDaytiRunngLampLe_UB : 53|1@0+ (1,0) [0|1] "" HCML
 SG_ DwnLoadDynLtgPrmForLedDaytiRunngLampLeContTiPrm : 7|10@0+ (1.0,0.0) [0.0|1000.0] "Milliseconds" HCML
 SG_ DwnLoadDynLtgPrmForLedDaytiRunngLampLeLowBriPrm : 31|8@0+ (1.0,0.0) [0.0|100.0] "%" HCML
 SG_ DwnLoadDynLtgPrmForLedDaytiRunngLampLeModePrm : 13|5@0+ (1,0) [0|31] "" HCML
 SG_ DwnLoadDynLtgPrmForLedDaytiRunngLampLeOffsTiPrm : 47|10@0+ (1.0,0.0) [0.0|1000.0] "Milliseconds" HCML
 SG_ DwnLoadDynLtgPrmForLedDaytiRunngLampLeTistamp : 8|9@0+ (1.0,0.0) [0.0|511.0] "Unitless" HCML
 SG_ DwnLoadDynLtgPrmForLedDaytiRunngLampLeUpprBriPrm : 39|8@0+ (1.0,0.0) [0.0|100.0] "%" HCML

BO_ 318 CemBodyExpoFr33 : 8 CEM
 SG_ DwnLoadDynLtgPrmForLedDaytiRunngLampRi_UB : 53|1@0+ (1,0) [0|1] "" HCMR
 SG_ DwnLoadDynLtgPrmForLedDaytiRunngLampRiContTiPrm : 7|10@0+ (1.0,0.0) [0.0|1000.0] "Milliseconds" HCMR
 SG_ DwnLoadDynLtgPrmForLedDaytiRunngLampRiLowBriPrm : 31|8@0+ (1.0,0.0) [0.0|100.0] "%" HCMR
 SG_ DwnLoadDynLtgPrmForLedDaytiRunngLampRiModePrm : 13|5@0+ (1,0) [0|31] "" HCMR
 SG_ DwnLoadDynLtgPrmForLedDaytiRunngLampRiOffsTiPrm : 47|10@0+ (1.0,0.0) [0.0|1000.0] "Milliseconds" HCMR
 SG_ DwnLoadDynLtgPrmForLedDaytiRunngLampRiTistamp : 8|9@0+ (1.0,0.0) [0.0|511.0] "Unitless" HCMR
 SG_ DwnLoadDynLtgPrmForLedDaytiRunngLampRiUpprBriPrm : 39|8@0+ (1.0,0.0) [0.0|100.0] "%" HCMR

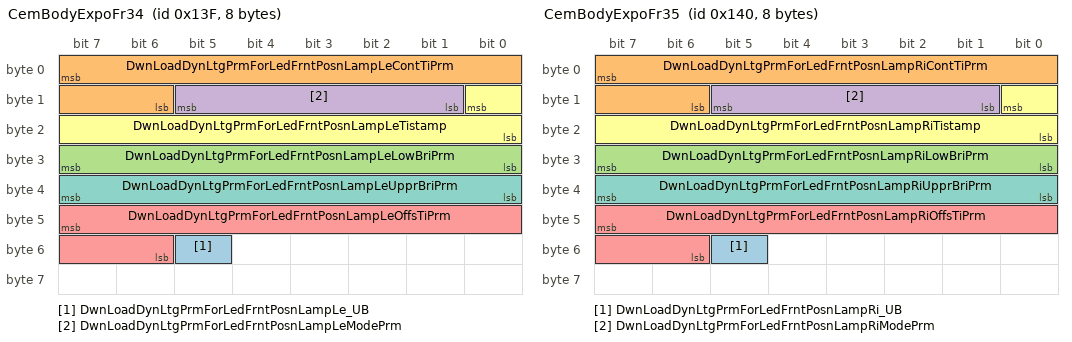
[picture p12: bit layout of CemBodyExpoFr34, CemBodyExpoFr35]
BO_ 319 CemBodyExpoFr34 : 8 CEM
 SG_ DwnLoadDynLtgPrmForLedFrntPosnLampLe_UB : 53|1@0+ (1,0) [0|1] "" HCML
 SG_ DwnLoadDynLtgPrmForLedFrntPosnLampLeContTiPrm : 7|10@0+ (1.0,0.0) [0.0|1000.0] "Milliseconds" HCML
 SG_ DwnLoadDynLtgPrmForLedFrntPosnLampLeLowBriPrm : 31|8@0+ (1.0,0.0) [0.0|100.0] "%" HCML
 SG_ DwnLoadDynLtgPrmForLedFrntPosnLampLeModePrm : 13|5@0+ (1,0) [0|31] "" HCML
 SG_ DwnLoadDynLtgPrmForLedFrntPosnLampLeOffsTiPrm : 47|10@0+ (1.0,0.0) [0.0|1000.0] "Milliseconds" HCML
 SG_ DwnLoadDynLtgPrmForLedFrntPosnLampLeTistamp : 8|9@0+ (1.0,0.0) [0.0|511.0] "Unitless" HCML
 SG_ DwnLoadDynLtgPrmForLedFrntPosnLampLeUpprBriPrm : 39|8@0+ (1.0,0.0) [0.0|100.0] "%" HCML

BO_ 320 CemBodyExpoFr35 : 8 CEM
 SG_ DwnLoadDynLtgPrmForLedFrntPosnLampRi_UB : 53|1@0+ (1,0) [0|1] "" HCMR
 SG_ DwnLoadDynLtgPrmForLedFrntPosnLampRiContTiPrm : 7|10@0+ (1.0,0.0) [0.0|1000.0] "Milliseconds" HCMR
 SG_ DwnLoadDynLtgPrmForLedFrntPosnLampRiLowBriPrm : 31|8@0+ (1.0,0.0) [0.0|100.0] "%" HCMR
 SG_ DwnLoadDynLtgPrmForLedFrntPosnLampRiModePrm : 13|5@0+ (1,0) [0|31] "" HCMR
 SG_ DwnLoadDynLtgPrmForLedFrntPosnLampRiOffsTiPrm : 47|10@0+ (1.0,0.0) [0.0|1000.0] "Milliseconds" HCMR
 SG_ DwnLoadDynLtgPrmForLedFrntPosnLampRiTistamp : 8|9@0+ (1.0,0.0) [0.0|511.0] "Unitless" HCMR
 SG_ DwnLoadDynLtgPrmForLedFrntPosnLampRiUpprBriPrm : 39|8@0+ (1.0,0.0) [0.0|100.0] "%" HCMR

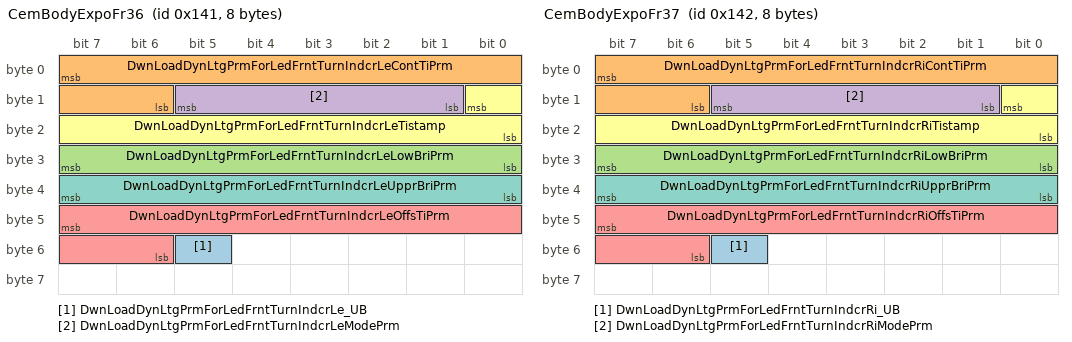
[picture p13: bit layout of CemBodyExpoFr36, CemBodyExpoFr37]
BO_ 321 CemBodyExpoFr36 : 8 CEM
 SG_ DwnLoadDynLtgPrmForLedFrntTurnIndcrLe_UB : 53|1@0+ (1,0) [0|1] "" HCML
 SG_ DwnLoadDynLtgPrmForLedFrntTurnIndcrLeContTiPrm : 7|10@0+ (1.0,0.0) [0.0|1000.0] "Milliseconds" HCML
 SG_ DwnLoadDynLtgPrmForLedFrntTurnIndcrLeLowBriPrm : 31|8@0+ (1.0,0.0) [0.0|100.0] "%" HCML
 SG_ DwnLoadDynLtgPrmForLedFrntTurnIndcrLeModePrm : 13|5@0+ (1,0) [0|31] "" HCML
 SG_ DwnLoadDynLtgPrmForLedFrntTurnIndcrLeOffsTiPrm : 47|10@0+ (1.0,0.0) [0.0|1000.0] "Milliseconds" HCML
 SG_ DwnLoadDynLtgPrmForLedFrntTurnIndcrLeTistamp : 8|9@0+ (1.0,0.0) [0.0|511.0] "Unitless" HCML
 SG_ DwnLoadDynLtgPrmForLedFrntTurnIndcrLeUpprBriPrm : 39|8@0+ (1.0,0.0) [0.0|100.0] "%" HCML

BO_ 322 CemBodyExpoFr37 : 8 CEM
 SG_ DwnLoadDynLtgPrmForLedFrntTurnIndcrRi_UB : 53|1@0+ (1,0) [0|1] "" HCMR
 SG_ DwnLoadDynLtgPrmForLedFrntTurnIndcrRiContTiPrm : 7|10@0+ (1.0,0.0) [0.0|1000.0] "Milliseconds" HCMR
 SG_ DwnLoadDynLtgPrmForLedFrntTurnIndcrRiLowBriPrm : 31|8@0+ (1.0,0.0) [0.0|100.0] "%" HCMR
 SG_ DwnLoadDynLtgPrmForLedFrntTurnIndcrRiModePrm : 13|5@0+ (1,0) [0|31] "" HCMR
 SG_ DwnLoadDynLtgPrmForLedFrntTurnIndcrRiOffsTiPrm : 47|10@0+ (1.0,0.0) [0.0|1000.0] "Milliseconds" HCMR
 SG_ DwnLoadDynLtgPrmForLedFrntTurnIndcrRiTistamp : 8|9@0+ (1.0,0.0) [0.0|511.0] "Unitless" HCMR
 SG_ DwnLoadDynLtgPrmForLedFrntTurnIndcrRiUpprBriPrm : 39|8@0+ (1.0,0.0) [0.0|100.0] "%" HCMR

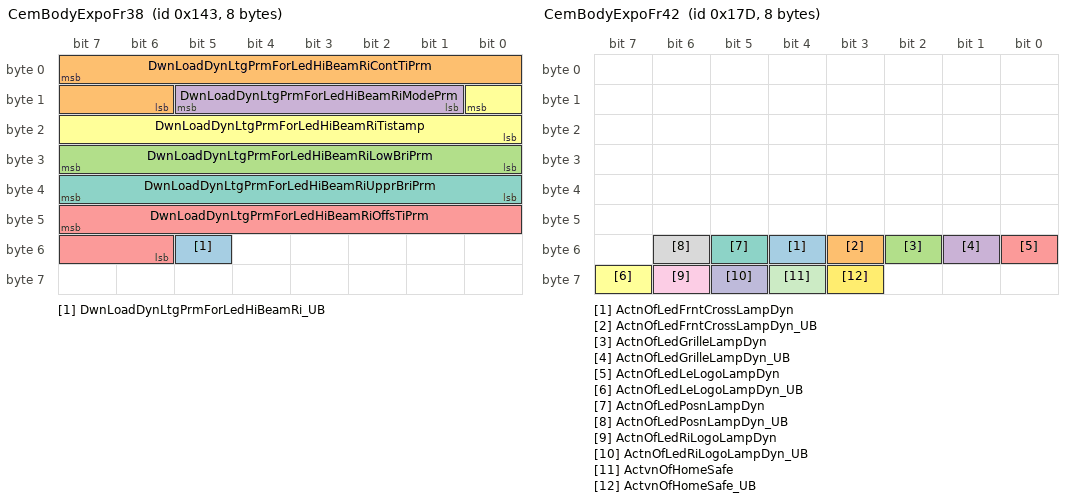
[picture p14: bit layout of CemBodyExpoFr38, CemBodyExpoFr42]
BO_ 323 CemBodyExpoFr38 : 8 CEM
 SG_ DwnLoadDynLtgPrmForLedHiBeamRi_UB : 53|1@0+ (1,0) [0|1] "" HCMR
 SG_ DwnLoadDynLtgPrmForLedHiBeamRiContTiPrm : 7|10@0+ (1.0,0.0) [0.0|1000.0] "Milliseconds" HCMR
 SG_ DwnLoadDynLtgPrmForLedHiBeamRiLowBriPrm : 31|8@0+ (1.0,0.0) [0.0|100.0] "%" HCMR
 SG_ DwnLoadDynLtgPrmForLedHiBeamRiModePrm : 13|5@0+ (1,0) [0|31] "" HCMR
 SG_ DwnLoadDynLtgPrmForLedHiBeamRiOffsTiPrm : 47|10@0+ (1.0,0.0) [0.0|1000.0] "Milliseconds" HCMR
 SG_ DwnLoadDynLtgPrmForLedHiBeamRiTistamp : 8|9@0+ (1.0,0.0) [0.0|511.0] "Unitless" HCMR
 SG_ DwnLoadDynLtgPrmForLedHiBeamRiUpprBriPrm : 39|8@0+ (1.0,0.0) [0.0|100.0] "%" HCMR

BO_ 381 CemBodyExpoFr42 : 8 CEM
 SG_ ActnOfLedFrntCrossLampDyn : 52|1@0+ (1,0) [0|1] "" HCML,HCMR
 SG_ ActnOfLedFrntCrossLampDyn_UB : 51|1@0+ (1,0) [0|1] "" HCML,HCMR
 SG_ ActnOfLedGrilleLampDyn : 50|1@0+ (1,0) [0|1] "" HCML,HCMR
 SG_ ActnOfLedGrilleLampDyn_UB : 49|1@0+ (1,0) [0|1] "" HCML,HCMR
 SG_ ActnOfLedLeLogoLampDyn : 48|1@0+ (1,0) [0|1] "" HCML
 SG_ ActnOfLedLeLogoLampDyn_UB : 63|1@0+ (1,0) [0|1] "" HCML
 SG_ ActnOfLedPosnLampDyn : 53|1@0+ (1,0) [0|1] "" HCML,HCMR,RCML,RCMM,RCMR
 SG_ ActnOfLedPosnLampDyn_UB : 54|1@0+ (1,0) [0|1] "" HCML,HCMR,RCML,RCMM,RCMR
 SG_ ActnOfLedRiLogoLampDyn : 62|1@0+ (1,0) [0|1] "" HCMR
 SG_ ActnOfLedRiLogoLampDyn_UB : 61|1@0+ (1,0) [0|1] "" HCMR
 SG_ ActvnOfHomeSafe : 60|1@0+ (1,0) [0|1] "" HCML,HCMR,RCML,RCMM,RCMR
 SG_ ActvnOfHomeSafe_UB : 59|1@0+ (1,0) [0|1] "" HCML,HCMR,RCML,RCMM,RCMR

BO_ 612 CemBodyExpoFr45 : 8 CEM
 SG_ ActvnOfApproach : 39|1@0+ (1,0) [0|1] "" HCML,HCMR,RCML,RCMM,RCMR
 SG_ ActvnOfApproach_UB : 35|1@0+ (1,0) [0|1] "" HCML,HCMR,RCML,RCMM,RCMR
 SG_ ActvnOfCarLoctr : 38|1@0+ (1,0) [0|1] "" HCML,HCMR
 SG_ ActvnOfCarLoctr_UB : 34|1@0+ (1,0) [0|1] "" HCML,HCMR
 SG_ ActvnOfReLogoLamp : 3|1@0+ (1,0) [0|1] "" RCMM
 SG_ ActvnOfReLogoLamp_UB : 2|1@0+ (1,0) [0|1] "" RCMM
 SG_ ActvnOfSayHi : 37|1@0+ (1,0) [0|1] "" Vector_XXX
 SG_ ActvnOfSayHi_UB : 33|1@0+ (1,0) [0|1] "" Vector_XXX
 SG_ ActvnOfWaitMode : 36|1@0+ (1,0) [0|1] "" HCML,HCMR,RCML,RCMM,RCMR
 SG_ ActvnOfWaitMode_UB : 32|1@0+ (1,0) [0|1] "" HCML,HCMR,RCML,RCMM,RCMR
 SG_ BrkPedlVal_UB : 42|1@0+ (1,0) [0|1] "" HCML,HCMR
 SG_ BrkPedlValBrkPedlVal : 54|15@0+ (0.00390625,0.0) [0.0|100.0] "%" HCML,HCMR
 SG_ BrkPedlValQf : 41|2@0+ (1,0) [0|3] "" HCML,HCMR
 SG_ CinhDrvrSts : 17|1@0+ (1,0) [0|1] "" Vector_XXX
 SG_ CinhDrvrSts_UB : 16|1@0+ (1,0) [0|1] "" Vector_XXX
 SG_ CinhDrvrSwt : 19|1@0+ (1,0) [0|1] "" Vector_XXX
 SG_ CinhDrvrSwt_UB : 18|1@0+ (1,0) [0|1] "" Vector_XXX
 SG_ CinhLeReSts : 21|1@0+ (1,0) [0|1] "" Vector_XXX
 SG_ CinhLeReSts_UB : 20|1@0+ (1,0) [0|1] "" Vector_XXX
 SG_ CinhLeReSwt : 23|1@0+ (1,0) [0|1] "" Vector_XXX
 SG_ CinhLeReSwt_UB : 22|1@0+ (1,0) [0|1] "" Vector_XXX
 SG_ CinhPassSts : 9|1@0+ (1,0) [0|1] "" Vector_XXX
 SG_ CinhPassSts_UB : 8|1@0+ (1,0) [0|1] "" Vector_XXX
 SG_ CinhPassSwt : 12|1@0+ (1,0) [0|1] "" Vector_XXX
 SG_ CinhPassSwt_UB : 11|1@0+ (1,0) [0|1] "" Vector_XXX
 SG_ CinhRiReSts : 14|1@0+ (1,0) [0|1] "" Vector_XXX
 SG_ CinhRiReSts_UB : 13|1@0+ (1,0) [0|1] "" Vector_XXX
 SG_ CinhRiReSwt : 31|1@0+ (1,0) [0|1] "" Vector_XXX
 SG_ CinhRiReSwt_UB : 15|1@0+ (1,0) [0|1] "" Vector_XXX
 SG_ HmiHvacFanLvlFrnt : 7|4@0+ (1,0) [0|15] "" Vector_XXX
 SG_ HmiHvacFanLvlFrnt_UB : 45|1@0+ (1,0) [0|1] "" Vector_XXX
 SG_ IndcrNoSeq : 47|1@0+ (1,0) [0|1] "" HCML,HCMR,RCML,RCMM,RCMR
 SG_ IndcrNoSeq_UB : 46|1@0+ (1,0) [0|1] "" HCML,HCMR,RCML,RCMM,RCMR
 SG_ LitArea : 10|1@0+ (1,0) [0|1] "" HCML,HCMR
 SG_ LitArea_UB : 30|1@0+ (1,0) [0|1] "" HCML,HCMR
 SG_ ReLePwrDoorManStrengthLvl : 1|2@0+ (1,0) [0|3] "" Vector_XXX
 SG_ ReLePwrDoorManStrengthLvl_UB : 44|1@0+ (1,0) [0|1] "" Vector_XXX
 SG_ WipgInfo_UB : 29|1@0+ (1,0) [0|1] "" HCML,HCMR
 SG_ WipgInfoWipgSpdInfo : 26|3@0+ (1,0) [0|7] "" HCML,HCMR
 SG_ WipgInfoWiprActv : 27|1@0+ (1,0) [0|1] "" HCML,HCMR
 SG_ WipgInfoWiprInWipgAr : 28|1@0+ (1,0) [0|1] "" HCML,HCMR

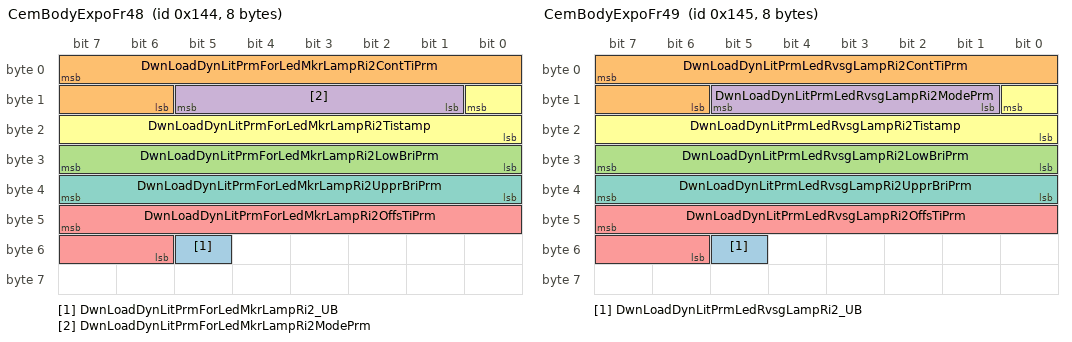
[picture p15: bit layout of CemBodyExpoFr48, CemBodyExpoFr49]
BO_ 324 CemBodyExpoFr48 : 8 CEM
 SG_ DwnLoadDynLitPrmForLedMkrLampRi2_UB : 53|1@0+ (1,0) [0|1] "" RCMM,RCMR
 SG_ DwnLoadDynLitPrmForLedMkrLampRi2ContTiPrm : 7|10@0+ (1.0,0.0) [0.0|1000.0] "Milliseconds" RCMM,RCMR
 SG_ DwnLoadDynLitPrmForLedMkrLampRi2LowBriPrm : 31|8@0+ (1.0,0.0) [0.0|100.0] "%" RCMM,RCMR
 SG_ DwnLoadDynLitPrmForLedMkrLampRi2ModePrm : 13|5@0+ (1,0) [0|31] "" RCMM,RCMR
 SG_ DwnLoadDynLitPrmForLedMkrLampRi2OffsTiPrm : 47|10@0+ (1.0,0.0) [0.0|1000.0] "Milliseconds" RCMM,RCMR
 SG_ DwnLoadDynLitPrmForLedMkrLampRi2Tistamp : 8|9@0+ (1.0,0.0) [0.0|511.0] "Unitless" RCMM,RCMR
 SG_ DwnLoadDynLitPrmForLedMkrLampRi2UpprBriPrm : 39|8@0+ (1.0,0.0) [0.0|100.0] "%" RCMM,RCMR

BO_ 325 CemBodyExpoFr49 : 8 CEM
 SG_ DwnLoadDynLitPrmLedRvsgLampRi2_UB : 53|1@0+ (1,0) [0|1] "" RCMM,RCMR
 SG_ DwnLoadDynLitPrmLedRvsgLampRi2ContTiPrm : 7|10@0+ (1.0,0.0) [0.0|1000.0] "Milliseconds" RCMM,RCMR
 SG_ DwnLoadDynLitPrmLedRvsgLampRi2LowBriPrm : 31|8@0+ (1.0,0.0) [0.0|100.0] "%" RCMM,RCMR
 SG_ DwnLoadDynLitPrmLedRvsgLampRi2ModePrm : 13|5@0+ (1,0) [0|31] "" RCMM,RCMR
 SG_ DwnLoadDynLitPrmLedRvsgLampRi2OffsTiPrm : 47|10@0+ (1.0,0.0) [0.0|1000.0] "Milliseconds" RCMM,RCMR
 SG_ DwnLoadDynLitPrmLedRvsgLampRi2Tistamp : 8|9@0+ (1.0,0.0) [0.0|511.0] "Unitless" RCMM,RCMR
 SG_ DwnLoadDynLitPrmLedRvsgLampRi2UpprBriPrm : 39|8@0+ (1.0,0.0) [0.0|100.0] "%" RCMM,RCMR

BO_ 522 CemBodyExpoFr50 : 8 CEM
 SG_ ActnOfLedCornrgLampLe : 6|1@0+ (1,0) [0|1] "" HCML
 SG_ ActnOfLedCornrgLampLe_UB : 7|1@0+ (1,0) [0|1] "" HCML
 SG_ ActnOfLedCornrgLampRi : 22|1@0+ (1,0) [0|1] "" HCMR
 SG_ ActnOfLedCornrgLampRi_UB : 23|1@0+ (1,0) [0|1] "" HCMR
 SG_ ActnOfLedDaytiRunngLamp : 32|1@0+ (1,0) [0|1] "" HCML,HCMR
 SG_ ActnOfLedDaytiRunngLamp_UB : 33|1@0+ (1,0) [0|1] "" HCML,HCMR
 SG_ ActnOfLedFrntFogLamp : 34|1@0+ (1,0) [0|1] "" HCML,HCMR
 SG_ ActnOfLedFrntFogLamp_UB : 35|1@0+ (1,0) [0|1] "" HCML,HCMR
 SG_ ActnOfLedHiBeam : 36|1@0+ (1,0) [0|1] "" HCML,HCMR
 SG_ ActnOfLedHiBeam_UB : 37|1@0+ (1,0) [0|1] "" HCML,HCMR
 SG_ ActnOfLedLoBeam_UB : 5|1@0+ (1,0) [0|1] "" HCML,HCMR
 SG_ ActnOfLedLoBeamActnOfLedLoBeam : 4|1@0+ (1,0) [0|1] "" HCML,HCMR
 SG_ ActnOfLedLoBeamChks : 15|8@0+ (1.0,0.0) [0.0|255.0] "Unitless" HCML,HCMR
 SG_ ActnOfLedLoBeamCntr : 3|4@0+ (1.0,0.0) [0.0|15.0] "Unitless" HCML,HCMR
 SG_ ActnOfLedPosnLamp : 38|1@0+ (1,0) [0|1] "" HCML,HCMR
 SG_ ActnOfLedPosnLamp_UB : 39|1@0+ (1,0) [0|1] "" HCML,HCMR
 SG_ ActnOfLedReFogLamp : 40|1@0+ (1,0) [0|1] "" RCML,RCMM,RCMR
 SG_ ActnOfLedReFogLamp_UB : 41|1@0+ (1,0) [0|1] "" RCML,RCMM,RCMR
 SG_ ActnOfLedRePosnLamp : 60|1@0+ (1,0) [0|1] "" RCML,RCMM,RCMR
 SG_ ActnOfLedRePosnLamp_UB : 61|1@0+ (1,0) [0|1] "" RCML,RCMM,RCMR
 SG_ ActnOfLedRvsgLamp : 42|1@0+ (1,0) [0|1] "" RCML,RCMM,RCMR
 SG_ ActnOfLedRvsgLamp_UB : 43|1@0+ (1,0) [0|1] "" RCML,RCMM,RCMR
 SG_ ActnOfLedStopLamp_UB : 21|1@0+ (1,0) [0|1] "" RCML,RCMM,RCMR
 SG_ ActnOfLedStopLampActnOfLedStopLamp : 20|1@0+ (1,0) [0|1] "" RCML,RCMM,RCMR
 SG_ ActnOfLedStopLampChks : 31|8@0+ (1.0,0.0) [0.0|255.0] "Unitless" RCML,RCMM,RCMR
 SG_ ActnOfLedStopLampCntr : 19|4@0+ (1.0,0.0) [0.0|15.0] "Unitless" RCML,RCMM,RCMR
 SG_ ActvnOfAfs : 44|1@0+ (1,0) [0|1] "" HCML,HCMR
 SG_ ActvnOfAfs_UB : 45|1@0+ (1,0) [0|1] "" HCML,HCMR
 SG_ ActvnOfAhbc : 46|1@0+ (1,0) [0|1] "" HCML,HCMR
 SG_ ActvnOfAhbc_UB : 47|1@0+ (1,0) [0|1] "" HCML,HCMR
 SG_ ActvnOfAhl : 48|1@0+ (1,0) [0|1] "" HCML,HCMR
 SG_ ActvnOfAhl_UB : 49|1@0+ (1,0) [0|1] "" HCML,HCMR
 SG_ ActvnOfBrkLi : 50|1@0+ (1,0) [0|1] "" RCML,RCMR
 SG_ ActvnOfBrkLi_UB : 51|1@0+ (1,0) [0|1] "" RCML,RCMR
 SG_ ActvnOfDbl : 52|1@0+ (1,0) [0|1] "" HCML,HCMR
 SG_ ActvnOfDbl_UB : 53|1@0+ (1,0) [0|1] "" HCML,HCMR
 SG_ ActvnOfGoodByeLi : 54|1@0+ (1,0) [0|1] "" HCML,HCMR,RCML,RCMM,RCMR
 SG_ ActvnOfGoodByeLi_UB : 55|1@0+ (1,0) [0|1] "" HCML,HCMR,RCML,RCMM,RCMR
 SG_ ActvnOfTouristMod : 56|1@0+ (1,0) [0|1] "" HCML,HCMR
 SG_ ActvnOfTouristMod_UB : 57|1@0+ (1,0) [0|1] "" HCML,HCMR
 SG_ ActvnOfWelcomeLi : 58|1@0+ (1,0) [0|1] "" HCML,HCMR,RCML,RCMM,RCMR
 SG_ ActvnOfWelcomeLi_UB : 59|1@0+ (1,0) [0|1] "" HCML,HCMR,RCML,RCMM,RCMR

BO_ 538 CemBodyExpoFr51 : 8 CEM
 SG_ ActvnOfIndcr_UB : 38|1@0+ (1,0) [0|1] "" HCML,HCMR,RCML,RCMM,RCMR
 SG_ ActvnOfIndcrIndcrOut : 37|2@0+ (1,0) [0|3] "" HCML,HCMR,RCML,RCMM,RCMR
 SG_ ActvnOfIndcrIndcrOutChks : 47|8@0+ (1.0,0.0) [0.0|255.0] "Unitless" HCML,HCMR,RCML,RCMM,RCMR
 SG_ ActvnOfIndcrIndcrOutCntr : 35|4@0+ (1.0,0.0) [0.0|15.0] "Unitless" HCML,HCMR,RCML,RCMM,RCMR
 SG_ DoorLeReAutoManReq : 55|2@0+ (1,0) [0|3] "" Vector_XXX
 SG_ DoorLeReAutoManReq_UB : 56|1@0+ (1,0) [0|1] "" Vector_XXX
 SG_ DoorPassAutoManReq : 58|2@0+ (1,0) [0|3] "" Vector_XXX
 SG_ DoorPassAutoManReq_UB : 59|1@0+ (1,0) [0|1] "" Vector_XXX
 SG_ DoorRiReAutoManReq : 61|2@0+ (1,0) [0|3] "" Vector_XXX
 SG_ DoorRiReAutoManReq_UB : 62|1@0+ (1,0) [0|1] "" Vector_XXX
 SG_ EmgyBrkLiIndcrTurn : 49|2@0+ (1,0) [0|3] "" RCML,RCMM,RCMR
 SG_ EmgyBrkLiIndcrTurn_UB : 50|1@0+ (1,0) [0|1] "" RCML,RCMM,RCMR
 SG_ IndcrPat_UB : 39|1@0+ (1,0) [0|1] "" HCML,HCMR,RCML,RCMM,RCMR
 SG_ IndcrPatCmd1WdTiOff : 7|16@0+ (0.001,0.0) [0.0|65.535] "s" HCML,HCMR,RCML,RCMM,RCMR
 SG_ IndcrPatCmd1WdTiOn : 23|16@0+ (0.001,0.0) [0.0|65.535] "s" HCML,HCMR,RCML,RCMM,RCMR
 SG_ IndcrSts : 52|2@0+ (1,0) [0|3] "" HCML,HCMR,RCML,RCMM,RCMR
 SG_ IndcrSts_UB : 53|1@0+ (1,0) [0|1] "" HCML,HCMR,RCML,RCMM,RCMR

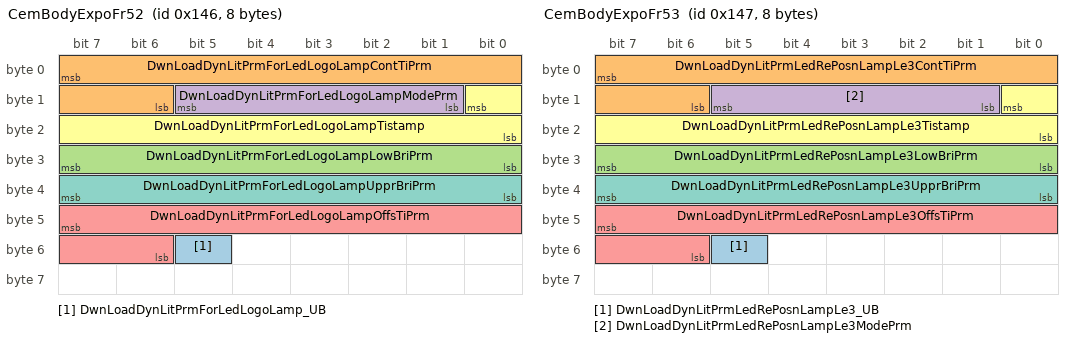
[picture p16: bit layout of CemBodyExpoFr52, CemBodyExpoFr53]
BO_ 326 CemBodyExpoFr52 : 8 CEM
 SG_ DwnLoadDynLitPrmForLedLogoLamp_UB : 53|1@0+ (1,0) [0|1] "" RCMM
 SG_ DwnLoadDynLitPrmForLedLogoLampContTiPrm : 7|10@0+ (1.0,0.0) [0.0|1000.0] "Milliseconds" RCMM
 SG_ DwnLoadDynLitPrmForLedLogoLampLowBriPrm : 31|8@0+ (1.0,0.0) [0.0|100.0] "%" RCMM
 SG_ DwnLoadDynLitPrmForLedLogoLampModePrm : 13|5@0+ (1,0) [0|31] "" RCMM
 SG_ DwnLoadDynLitPrmForLedLogoLampOffsTiPrm : 47|10@0+ (1.0,0.0) [0.0|1000.0] "Milliseconds" RCMM
 SG_ DwnLoadDynLitPrmForLedLogoLampTistamp : 8|9@0+ (1.0,0.0) [0.0|511.0] "Unitless" RCMM
 SG_ DwnLoadDynLitPrmForLedLogoLampUpprBriPrm : 39|8@0+ (1.0,0.0) [0.0|100.0] "%" RCMM

BO_ 327 CemBodyExpoFr53 : 8 CEM
 SG_ DwnLoadDynLitPrmLedRePosnLampLe3_UB : 53|1@0+ (1,0) [0|1] "" RCML
 SG_ DwnLoadDynLitPrmLedRePosnLampLe3ContTiPrm : 7|10@0+ (1.0,0.0) [0.0|1000.0] "Milliseconds" RCML
 SG_ DwnLoadDynLitPrmLedRePosnLampLe3LowBriPrm : 31|8@0+ (1.0,0.0) [0.0|100.0] "%" RCML
 SG_ DwnLoadDynLitPrmLedRePosnLampLe3ModePrm : 13|5@0+ (1,0) [0|31] "" RCML
 SG_ DwnLoadDynLitPrmLedRePosnLampLe3OffsTiPrm : 47|10@0+ (1.0,0.0) [0.0|1000.0] "Milliseconds" RCML
 SG_ DwnLoadDynLitPrmLedRePosnLampLe3Tistamp : 8|9@0+ (1.0,0.0) [0.0|511.0] "Unitless" RCML
 SG_ DwnLoadDynLitPrmLedRePosnLampLe3UpprBriPrm : 39|8@0+ (1.0,0.0) [0.0|100.0] "%" RCML

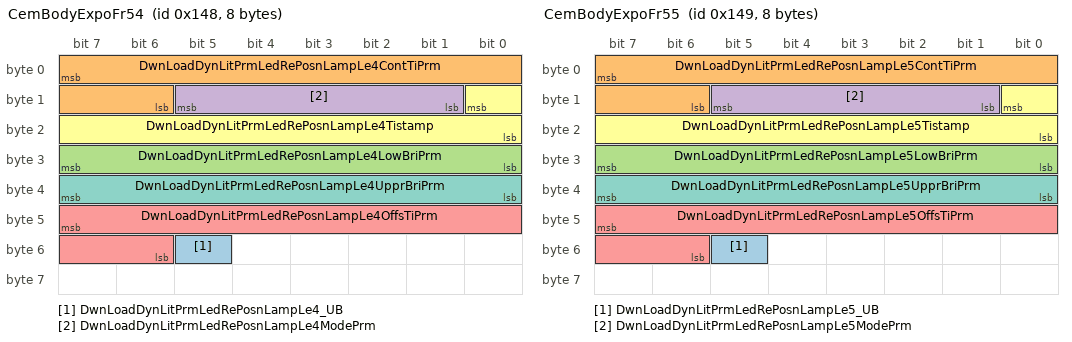
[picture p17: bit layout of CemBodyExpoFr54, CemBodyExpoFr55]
BO_ 328 CemBodyExpoFr54 : 8 CEM
 SG_ DwnLoadDynLitPrmLedRePosnLampLe4_UB : 53|1@0+ (1,0) [0|1] "" RCML
 SG_ DwnLoadDynLitPrmLedRePosnLampLe4ContTiPrm : 7|10@0+ (1.0,0.0) [0.0|1000.0] "Milliseconds" RCML
 SG_ DwnLoadDynLitPrmLedRePosnLampLe4LowBriPrm : 31|8@0+ (1.0,0.0) [0.0|100.0] "%" RCML
 SG_ DwnLoadDynLitPrmLedRePosnLampLe4ModePrm : 13|5@0+ (1,0) [0|31] "" RCML
 SG_ DwnLoadDynLitPrmLedRePosnLampLe4OffsTiPrm : 47|10@0+ (1.0,0.0) [0.0|1000.0] "Milliseconds" RCML
 SG_ DwnLoadDynLitPrmLedRePosnLampLe4Tistamp : 8|9@0+ (1.0,0.0) [0.0|511.0] "Unitless" RCML
 SG_ DwnLoadDynLitPrmLedRePosnLampLe4UpprBriPrm : 39|8@0+ (1.0,0.0) [0.0|100.0] "%" RCML

BO_ 329 CemBodyExpoFr55 : 8 CEM
 SG_ DwnLoadDynLitPrmLedRePosnLampLe5_UB : 53|1@0+ (1,0) [0|1] "" RCML,RCMM
 SG_ DwnLoadDynLitPrmLedRePosnLampLe5ContTiPrm : 7|10@0+ (1.0,0.0) [0.0|1000.0] "Milliseconds" RCML,RCMM
 SG_ DwnLoadDynLitPrmLedRePosnLampLe5LowBriPrm : 31|8@0+ (1.0,0.0) [0.0|100.0] "%" RCML,RCMM
 SG_ DwnLoadDynLitPrmLedRePosnLampLe5ModePrm : 13|5@0+ (1,0) [0|31] "" RCML,RCMM
 SG_ DwnLoadDynLitPrmLedRePosnLampLe5OffsTiPrm : 47|10@0+ (1.0,0.0) [0.0|1000.0] "Milliseconds" RCML,RCMM
 SG_ DwnLoadDynLitPrmLedRePosnLampLe5Tistamp : 8|9@0+ (1.0,0.0) [0.0|511.0] "Unitless" RCML,RCMM
 SG_ DwnLoadDynLitPrmLedRePosnLampLe5UpprBriPrm : 39|8@0+ (1.0,0.0) [0.0|100.0] "%" RCML,RCMM

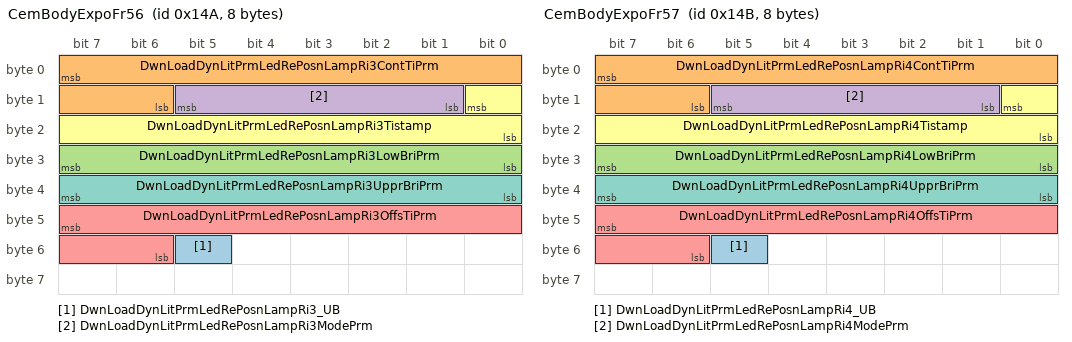
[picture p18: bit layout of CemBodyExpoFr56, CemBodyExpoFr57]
BO_ 330 CemBodyExpoFr56 : 8 CEM
 SG_ DwnLoadDynLitPrmLedRePosnLampRi3_UB : 53|1@0+ (1,0) [0|1] "" RCMR
 SG_ DwnLoadDynLitPrmLedRePosnLampRi3ContTiPrm : 7|10@0+ (1.0,0.0) [0.0|1000.0] "Milliseconds" RCMR
 SG_ DwnLoadDynLitPrmLedRePosnLampRi3LowBriPrm : 31|8@0+ (1.0,0.0) [0.0|100.0] "%" RCMR
 SG_ DwnLoadDynLitPrmLedRePosnLampRi3ModePrm : 13|5@0+ (1,0) [0|31] "" RCMR
 SG_ DwnLoadDynLitPrmLedRePosnLampRi3OffsTiPrm : 47|10@0+ (1.0,0.0) [0.0|1000.0] "Milliseconds" RCMR
 SG_ DwnLoadDynLitPrmLedRePosnLampRi3Tistamp : 8|9@0+ (1.0,0.0) [0.0|511.0] "Unitless" RCMR
 SG_ DwnLoadDynLitPrmLedRePosnLampRi3UpprBriPrm : 39|8@0+ (1.0,0.0) [0.0|100.0] "%" RCMR

BO_ 331 CemBodyExpoFr57 : 8 CEM
 SG_ DwnLoadDynLitPrmLedRePosnLampRi4_UB : 53|1@0+ (1,0) [0|1] "" RCMR
 SG_ DwnLoadDynLitPrmLedRePosnLampRi4ContTiPrm : 7|10@0+ (1.0,0.0) [0.0|1000.0] "Milliseconds" RCMR
 SG_ DwnLoadDynLitPrmLedRePosnLampRi4LowBriPrm : 31|8@0+ (1.0,0.0) [0.0|100.0] "%" RCMR
 SG_ DwnLoadDynLitPrmLedRePosnLampRi4ModePrm : 13|5@0+ (1,0) [0|31] "" RCMR
 SG_ DwnLoadDynLitPrmLedRePosnLampRi4OffsTiPrm : 47|10@0+ (1.0,0.0) [0.0|1000.0] "Milliseconds" RCMR
 SG_ DwnLoadDynLitPrmLedRePosnLampRi4Tistamp : 8|9@0+ (1.0,0.0) [0.0|511.0] "Unitless" RCMR
 SG_ DwnLoadDynLitPrmLedRePosnLampRi4UpprBriPrm : 39|8@0+ (1.0,0.0) [0.0|100.0] "%" RCMR

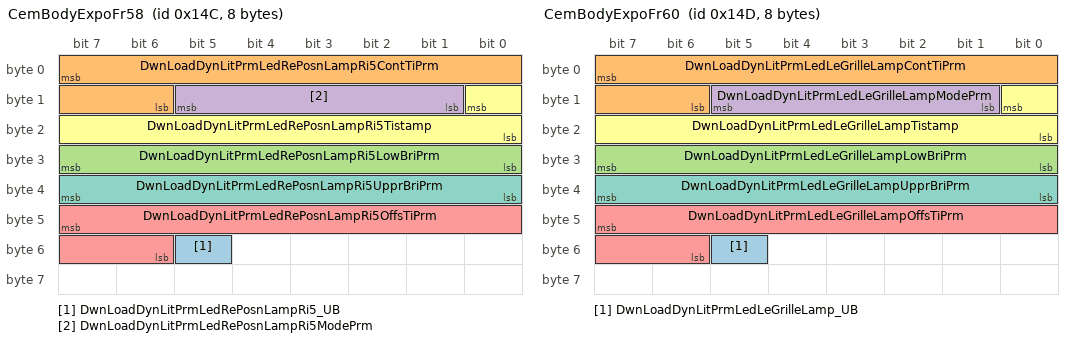
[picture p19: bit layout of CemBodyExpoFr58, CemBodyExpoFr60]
BO_ 332 CemBodyExpoFr58 : 8 CEM
 SG_ DwnLoadDynLitPrmLedRePosnLampRi5_UB : 53|1@0+ (1,0) [0|1] "" RCMM,RCMR
 SG_ DwnLoadDynLitPrmLedRePosnLampRi5ContTiPrm : 7|10@0+ (1.0,0.0) [0.0|1000.0] "Milliseconds" RCMM,RCMR
 SG_ DwnLoadDynLitPrmLedRePosnLampRi5LowBriPrm : 31|8@0+ (1.0,0.0) [0.0|100.0] "%" RCMM,RCMR
 SG_ DwnLoadDynLitPrmLedRePosnLampRi5ModePrm : 13|5@0+ (1,0) [0|31] "" RCMM,RCMR
 SG_ DwnLoadDynLitPrmLedRePosnLampRi5OffsTiPrm : 47|10@0+ (1.0,0.0) [0.0|1000.0] "Milliseconds" RCMM,RCMR
 SG_ DwnLoadDynLitPrmLedRePosnLampRi5Tistamp : 8|9@0+ (1.0,0.0) [0.0|511.0] "Unitless" RCMM,RCMR
 SG_ DwnLoadDynLitPrmLedRePosnLampRi5UpprBriPrm : 39|8@0+ (1.0,0.0) [0.0|100.0] "%" RCMM,RCMR

BO_ 24 CemBodyExpoFr59 : 8 CEM
 SG_ DoorDrvrPercSetFromHmi : 31|7@0+ (1.0,0.0) [0.0|101.0] "%" Vector_XXX
 SG_ DoorDrvrPercSetFromHmi_UB : 24|1@0+ (1,0) [0|1] "" Vector_XXX
 SG_ DoorDrvrSts : 39|2@0+ (1,0) [0|3] "" Vector_XXX
 SG_ DoorDrvrSts_UB : 37|1@0+ (1,0) [0|1] "" Vector_XXX
 SG_ DoorLeReSts : 36|2@0+ (1,0) [0|3] "" Vector_XXX
 SG_ DoorLeReSts_UB : 34|1@0+ (1,0) [0|1] "" Vector_XXX
 SG_ DoorOpenwarnLeIndcn : 14|2@0+ (1,0) [0|3] "" Vector_XXX
 SG_ DoorOpenwarnLeIndcn_UB : 12|1@0+ (1,0) [0|1] "" Vector_XXX
 SG_ DoorOpenwarnOn1 : 47|2@0+ (1,0) [0|3] "" Vector_XXX
 SG_ DoorOpenwarnOn1_UB : 44|1@0+ (1,0) [0|1] "" Vector_XXX
 SG_ DoorOpenwarnRiIndcn : 33|2@0+ (1,0) [0|3] "" Vector_XXX
 SG_ DoorOpenwarnRiIndcn_UB : 45|1@0+ (1,0) [0|1] "" Vector_XXX
 SG_ DoorPassPercSetFromHmi : 55|7@0+ (1.0,0.0) [0.0|101.0] "%" Vector_XXX
 SG_ DoorPassPercSetFromHmi_UB : 48|1@0+ (1,0) [0|1] "" Vector_XXX
 SG_ DoorRiRePercSetFromHmi : 63|7@0+ (1.0,0.0) [0.0|101.0] "%" Vector_XXX
 SG_ DoorRiRePercSetFromHmi_UB : 56|1@0+ (1,0) [0|1] "" Vector_XXX
 SG_ GrilleLampColorSelnReq : 2|3@0+ (1,0) [0|7] "" Vector_XXX
 SG_ GrilleLampColorSelnReq_UB : 15|1@0+ (1,0) [0|1] "" Vector_XXX
 SG_ HvBattSoc : 10|11@0+ (0.05,0.0) [0.0|100.0] "%" RCMM
 SG_ HvBattSoc_UB : 11|1@0+ (1,0) [0|1] "" RCMM
 SG_ PassPwrDoorManStrengthLvl : 43|2@0+ (1,0) [0|3] "" Vector_XXX
 SG_ PassPwrDoorManStrengthLvl_UB : 41|1@0+ (1,0) [0|1] "" Vector_XXX
 SG_ WelcomeGoodbyeModeReq : 7|4@0+ (1,0) [0|15] "" HCML,HCMR,RCML,RCMR
 SG_ WelcomeGoodbyeModeReq_UB : 3|1@0+ (1,0) [0|1] "" HCML,HCMR,RCML,RCMR

BO_ 333 CemBodyExpoFr60 : 8 CEM
 SG_ DwnLoadDynLitPrmLedLeGrilleLamp_UB : 53|1@0+ (1,0) [0|1] "" HCML
 SG_ DwnLoadDynLitPrmLedLeGrilleLampContTiPrm : 7|10@0+ (1.0,0.0) [0.0|1000.0] "Milliseconds" HCML
 SG_ DwnLoadDynLitPrmLedLeGrilleLampLowBriPrm : 31|8@0+ (1.0,0.0) [0.0|100.0] "%" HCML
 SG_ DwnLoadDynLitPrmLedLeGrilleLampModePrm : 13|5@0+ (1,0) [0|31] "" HCML
 SG_ DwnLoadDynLitPrmLedLeGrilleLampOffsTiPrm : 47|10@0+ (1.0,0.0) [0.0|1000.0] "Milliseconds" HCML
 SG_ DwnLoadDynLitPrmLedLeGrilleLampTistamp : 8|9@0+ (1.0,0.0) [0.0|511.0] "Unitless" HCML
 SG_ DwnLoadDynLitPrmLedLeGrilleLampUpprBriPrm : 39|8@0+ (1.0,0.0) [0.0|100.0] "%" HCML

BO_ 334 CemBodyExpoFr61 : 8 CEM
 SG_ DwnLoadDynLitPrmLedRiGrilleLamp_UB : 53|1@0+ (1,0) [0|1] "" HCMR
 SG_ DwnLoadDynLitPrmLedRiGrilleLampContTiPrm : 7|10@0+ (1.0,0.0) [0.0|1000.0] "Milliseconds" HCMR
 SG_ DwnLoadDynLitPrmLedRiGrilleLampLowBriPrm : 31|8@0+ (1.0,0.0) [0.0|100.0] "%" HCMR
 SG_ DwnLoadDynLitPrmLedRiGrilleLampModePrm : 13|5@0+ (1,0) [0|31] "" HCMR
 SG_ DwnLoadDynLitPrmLedRiGrilleLampOffsTiPrm : 47|10@0+ (1.0,0.0) [0.0|1000.0] "Milliseconds" HCMR
 SG_ DwnLoadDynLitPrmLedRiGrilleLampTistamp : 8|9@0+ (1.0,0.0) [0.0|511.0] "Unitless" HCMR
 SG_ DwnLoadDynLitPrmLedRiGrilleLampUpprBriPrm : 39|8@0+ (1.0,0.0) [0.0|100.0] "%" HCMR

BO_ 788 CemBodyExpoFr62 : 8 CEM
 SG_ DHUcontrolLedMkrLampLe1 : 7|2@0+ (1,0) [0|3] "" RCML
 SG_ DHUcontrolLedMkrLampLe1_UB : 63|1@0+ (1,0) [0|1] "" RCML
 SG_ DHUcontrolLedMkrLampLe2 : 5|2@0+ (1,0) [0|3] "" RCMM
 SG_ DHUcontrolLedMkrLampLe2_UB : 62|1@0+ (1,0) [0|1] "" RCMM
 SG_ DHUcontrolLedMkrLampRi1 : 3|2@0+ (1,0) [0|3] "" RCMR
 SG_ DHUcontrolLedMkrLampRi1_UB : 61|1@0+ (1,0) [0|1] "" RCMR
 SG_ DHUcontrolLedMkrLampRi2 : 1|2@0+ (1,0) [0|3] "" RCMM
 SG_ DHUcontrolLedMkrLampRi2_UB : 60|1@0+ (1,0) [0|1] "" RCMM
 SG_ DHUcontrolLedStopLampLe1 : 15|2@0+ (1,0) [0|3] "" RCML
 SG_ DHUcontrolLedStopLampLe1_UB : 59|1@0+ (1,0) [0|1] "" RCML
 SG_ DHUcontrolLedStopLampLe2 : 13|2@0+ (1,0) [0|3] "" RCMM
 SG_ DHUcontrolLedStopLampLe2_UB : 58|1@0+ (1,0) [0|1] "" RCMM
 SG_ DHUcontrolLedStopLampRi1 : 11|2@0+ (1,0) [0|3] "" RCMR
 SG_ DHUcontrolLedStopLampRi1_UB : 57|1@0+ (1,0) [0|1] "" RCMR
 SG_ DHUcontrolLedStopLampRi2 : 9|2@0+ (1,0) [0|3] "" RCMM
 SG_ DHUcontrolLedStopLampRi2_UB : 56|1@0+ (1,0) [0|1] "" RCMM
 SG_ DHUcontrolmiddlebrakelight : 23|2@0+ (1,0) [0|3] "" RCMM
 SG_ DHUcontrolmiddlebrakelight_UB : 48|1@0+ (1,0) [0|1] "" RCMM
 SG_ DHUcontrolmiddlecorneringlamp : 21|2@0+ (1,0) [0|3] "" RCMM
 SG_ DHUcontrolmiddlecorneringlamp_UB : 49|1@0+ (1,0) [0|1] "" RCMM
 SG_ DHUcontrolmiddlepositionlight : 19|2@0+ (1,0) [0|3] "" RCMM
 SG_ DHUcontrolmiddlepositionlight_UB : 50|1@0+ (1,0) [0|1] "" RCMM

CM_ SG_ 360 DoorOpenerPassReqChks "Checksum for E2E";
CM_ SG_ 360 DoorOpenerPassReqCntr "Counter for E2E";
CM_ SG_ 360 DoorOpenerPassReqDoorOpenerReq "DoorOpenerReq
DoorOpenerIdle - No request
DoorOpenerOpen - Request to Open
DoorOpenerCls - Request to Close
DoorOpenerStop - Request to stop any ongoing power side door movement";
CM_ SG_ 360 DoorOpenerPassReqTrigSrc "TrigSrc
NoTrigSrc - No trig source
KeyRem - Remote Key
HMI - Center stack display
Telm - Telematics
OutdSwt - Outer door switch
InsdSwt - Inside door switch";
CM_ SG_ 360 DoorOpenerRiReReqChks "Checksum for E2E";
CM_ SG_ 360 DoorOpenerRiReReqCntr "Counter for E2E";
CM_ SG_ 360 DoorOpenerRiReReqDoorOpenerReq "DoorOpenerReq
DoorOpenerIdle - No request
DoorOpenerOpen - Request to Open
DoorOpenerCls - Request to Close
DoorOpenerStop - Request to stop any ongoing power side door movement";
CM_ SG_ 360 DoorOpenerRiReReqTrigSrc "TrigSrc
NoTrigSrc - No trig source
KeyRem - Remote Key
HMI - Center stack display
Telm - Telematics
OutdSwt - Outer door switch
InsdSwt - Inside door switch";
CM_ SG_ 360 RadioFrqAM "radio frequency analog";
CM_ SG_ 360 ReRiPwrDoorManStrengthLvl "The level of Force Assist (manual strength) to close or open the rear row right side power door.
option:low/normal/high.";
CM_ SG_ 86 DHUcontrolleftcorneringlamp "DHU control left cornering lamp request 
0 = OnOffNoReqNoReq
1 = OnOffNoReqOn
2 = OnOffNoReqOff

 ";
CM_ SG_ 86 DHUcontrolleftdaytimerunninglamp "DHU control left day time running lamp requrest
0 = OnOffNoReqNoReq
1 = OnOffNoReqOn
2 = OnOffNoReqOff";
CM_ SG_ 86 DHUcontrolleftfroglight "DHU control left frog light";
CM_ SG_ 86 DHUcontrollefthighbeamlamp "DHU control left high beam lamp
0 = OnOffNoReqNoReq;1 = OnOffNoReqOn;2 = OnOffNoReqOff
";
CM_ SG_ 86 DHUcontrolleftlowbeamlamp "DHU control left lowbeam lamp:
0 = OnOffNoReqNoReq;1 = OnOffNoReqOn;2 = OnOffNoReqOff";
CM_ SG_ 86 DHUcontrolleftpositionlamp "DHU control left position lamp
0 = OnOffNoReqNoReq
1 = OnOffNoReqOn
2 = OnOffNoReqOff
";
CM_ SG_ 86 DHUcontrolrightcorneringlamp "DHU control right cornering lamp
0 = OnOffNoReqNoReq
1 = OnOffNoReqOn
2 = OnOffNoReqOff";
CM_ SG_ 86 DHUcontrolrightdaytimerunninglamp "DHU control right daytime running lamp request
0 = OnOffNoReqNoReq
1 = OnOffNoReqOn
2 = OnOffNoReqOff";
CM_ SG_ 86 DHUcontrolrightfroglight "DHU control right frog light request
0 = OnOffNoReqNoReq
1 = OnOffNoReqOn
2 = OnOffNoReqOff

";
CM_ SG_ 86 DHUcontrolrighthighbeamlamp "DHU control requiment right high beam lamp
0 = OnOffNoReqNoReq;1 = OnOffNoReqOn;2 = OnOffNoReqOff";
CM_ SG_ 86 DHUcontrolrightlowbeamlamp "DHU control right low beam
0 = OnOffNoReqNoReq;1 = OnOffNoReqOn;2 =OnOffNoReqOff ";
CM_ SG_ 86 DHUcontrolrightpositionLamp "DHU control left brake light Lamp
0 = OnOffNoReqNoReq
1 = OnOffNoReqOn
2 = OnOffNoReqOff";
CM_ SG_ 298 DwnLoadDynLitPrmForLedStopLampRi1ContTiPrm "Light Show Continue Time Parameter 1";
CM_ SG_ 298 DwnLoadDynLitPrmForLedStopLampRi1LowBriPrm "Light Show Lower Brightness Parameter 1";
CM_ SG_ 298 DwnLoadDynLitPrmForLedStopLampRi1ModePrm "Light Show Mode Parameter 1";
CM_ SG_ 298 DwnLoadDynLitPrmForLedStopLampRi1OffsTiPrm "Light Show Offset Time Parameter 1";
CM_ SG_ 298 DwnLoadDynLitPrmForLedStopLampRi1Tistamp "Light Show time stamp";
CM_ SG_ 298 DwnLoadDynLitPrmForLedStopLampRi1UpprBriPrm "Light Show Upper Brightness Parameter 1";
CM_ SG_ 523 ActvOfGdbyeForGndLampLe "active of goodbye for ground lamp left single";
CM_ SG_ 523 ActvOfWelcomeForGndLampLe "active of welcome for ground lamp left 
off-off
on-on";
CM_ SG_ 523 RoadInclnQly "Road inclination information. The road inclination is negative when the vehicle is facing uphill and positive when the vehicle is facing downhill. Quality information for road inclination";
CM_ SG_ 523 RoadInclnRoadIncln "Road inclination information. The road inclination is negative when the vehicle is facing uphill and positive when the vehicle is facing downhill.";
CM_ SG_ 523 RollAgGlbQf "Lateral inclination of vehicle against horizon Qualifier flag";
CM_ SG_ 523 RollAgGlbVal "Lateral inclination of vehicle against horizon Roll angle in radians";
CM_ SG_ 640 SunCurtPosnSts "Interface Reporting Sun Curtain Position Status.";
CM_ SG_ 640 SunRoofPosnSts "Sun roof position status";
CM_ SG_ 640 WinPosnStsAtDrvr "Signal sent to inform the rest of the car of the window position status for the front driver side door. The value of the signal is either an approximated percentage of openness, of the window is moving or if the position is unkown.
";
CM_ SG_ 640 WinPosnStsAtPass "Signal sent to inform the rest of the car of the window position status for the front passenger side door. The value of the signal is either an approximated percentage of openness, of the window is moving or if the position is unkown.
";
CM_ SG_ 640 WinPosnStsAtReLe "Signal sent to inform the rest of the car of the window position status for the rear driver side door. The value of the signal is either an approximated percentage of openness, of the window is moving or if the position is unkown.

";
CM_ SG_ 640 WinPosnStsAtReRi "Signal sent to inform the rest of the car of the window position status for the rear passenger side door. The value of the signal is either an approximated percentage of openness, of the window is moving or if the position is unkown.
";
CM_ SG_ 1110 VFCInfoEna "VFCVectorFrame enable and disable setting";
CM_ SG_ 359 CarpetLiSetCarpetLiSet "Carpet lamp theme setting";
CM_ SG_ 359 CarpetLiSetPerc12 "Carpet lamp theme setting";
CM_ SG_ 359 CarpetLiTrialSetPerc12 "Carpet lamp trial theme setting";
CM_ SG_ 359 CarpetLiTrialSetTrialSet "Carpet lamp trial theme setting";
CM_ SG_ 299 DwnLoadDynLitPrmLedReFogLampLe1ContTiPrm "Light Show Continue Time Parameter 1";
CM_ SG_ 299 DwnLoadDynLitPrmLedReFogLampLe1LowBriPrm "Light Show Lower Brightness Parameter 1";
CM_ SG_ 299 DwnLoadDynLitPrmLedReFogLampLe1ModePrm "Light Show Mode Parameter 1";
CM_ SG_ 299 DwnLoadDynLitPrmLedReFogLampLe1OffsTiPrm "Light Show Offset Time Parameter 1";
CM_ SG_ 299 DwnLoadDynLitPrmLedReFogLampLe1Tistamp "Light Show time stamp";
CM_ SG_ 299 DwnLoadDynLitPrmLedReFogLampLe1UpprBriPrm "Light Show Upper Brightness Parameter 1";
CM_ SG_ 300 DwnLoadDynLitPrmLedReFogLampLe2ContTiPrm "Light Show Continue Time Parameter 1";
CM_ SG_ 300 DwnLoadDynLitPrmLedReFogLampLe2LowBriPrm "Light Show Lower Brightness Parameter 1";
CM_ SG_ 300 DwnLoadDynLitPrmLedReFogLampLe2ModePrm "Light Show Mode Parameter 1";
CM_ SG_ 300 DwnLoadDynLitPrmLedReFogLampLe2OffsTiPrm "Light Show Offset Time Parameter 1";
CM_ SG_ 300 DwnLoadDynLitPrmLedReFogLampLe2Tistamp "Light Show time stamp";
CM_ SG_ 300 DwnLoadDynLitPrmLedReFogLampLe2UpprBriPrm "Light Show Upper Brightness Parameter 1";
CM_ SG_ 301 DwnLoadDynLitPrmLedReFogLampRi1ContTiPrm "Light Show Continue Time Parameter 1";
CM_ SG_ 301 DwnLoadDynLitPrmLedReFogLampRi1LowBriPrm "Light Show Lower Brightness Parameter 1";
CM_ SG_ 301 DwnLoadDynLitPrmLedReFogLampRi1ModePrm "Light Show Mode Parameter 1";
CM_ SG_ 301 DwnLoadDynLitPrmLedReFogLampRi1OffsTiPrm "Light Show Offset Time Parameter 1";
CM_ SG_ 301 DwnLoadDynLitPrmLedReFogLampRi1Tistamp "Light Show time stamp";
CM_ SG_ 301 DwnLoadDynLitPrmLedReFogLampRi1UpprBriPrm "Light Show Upper Brightness Parameter 1";
CM_ SG_ 302 DwnLoadDynLitPrmLedRePosnLampLe1ContTiPrm "Light Show Continue Time Parameter 1";
CM_ SG_ 302 DwnLoadDynLitPrmLedRePosnLampLe1LowBriPrm "Light Show Lower Brightness Parameter 1";
CM_ SG_ 302 DwnLoadDynLitPrmLedRePosnLampLe1ModePrm "Light Show Mode Parameter 1";
CM_ SG_ 302 DwnLoadDynLitPrmLedRePosnLampLe1OffsTiPrm "Light Show Offset Time Parameter 1";
CM_ SG_ 302 DwnLoadDynLitPrmLedRePosnLampLe1Tistamp "Light Show time stamp";
CM_ SG_ 302 DwnLoadDynLitPrmLedRePosnLampLe1UpprBriPrm "Light Show Upper Brightness Parameter 1";
CM_ SG_ 303 DwnLoadDynLitPrmLedRePosnLampLe2ContTiPrm "Light Show Continue Time Parameter 1";
CM_ SG_ 303 DwnLoadDynLitPrmLedRePosnLampLe2LowBriPrm "Light Show Lower Brightness Parameter 1";
CM_ SG_ 303 DwnLoadDynLitPrmLedRePosnLampLe2ModePrm "Light Show Mode Parameter 1";
CM_ SG_ 303 DwnLoadDynLitPrmLedRePosnLampLe2OffsTiPrm "Light Show Offset Time Parameter 1";
CM_ SG_ 303 DwnLoadDynLitPrmLedRePosnLampLe2Tistamp "Light Show time stamp";
CM_ SG_ 303 DwnLoadDynLitPrmLedRePosnLampLe2UpprBriPrm "Light Show Upper Brightness Parameter 1";
CM_ SG_ 304 DwnLoadDynLitPrmLedRePosnLampRi1ContTiPrm "Light Show Continue Time Parameter 1";
CM_ SG_ 304 DwnLoadDynLitPrmLedRePosnLampRi1LowBriPrm "Light Show Lower Brightness Parameter 1";
CM_ SG_ 304 DwnLoadDynLitPrmLedRePosnLampRi1ModePrm "Light Show Mode Parameter 1";
CM_ SG_ 304 DwnLoadDynLitPrmLedRePosnLampRi1OffsTiPrm "Light Show Offset Time Parameter 1";
CM_ SG_ 304 DwnLoadDynLitPrmLedRePosnLampRi1Tistamp "Light Show time stamp";
CM_ SG_ 304 DwnLoadDynLitPrmLedRePosnLampRi1UpprBriPrm "Light Show Upper Brightness Parameter 1";
CM_ SG_ 305 DwnLoadDynLitPrmLedReTurnIndcrLe1ContTiPrm "Light Show Continue Time Parameter 1";
CM_ SG_ 305 DwnLoadDynLitPrmLedReTurnIndcrLe1LowBriPrm "Light Show Lower Brightness Parameter 1";
CM_ SG_ 305 DwnLoadDynLitPrmLedReTurnIndcrLe1ModePrm "Light Show Mode Parameter 1";
CM_ SG_ 305 DwnLoadDynLitPrmLedReTurnIndcrLe1OffsTiPrm "Light Show Offset Time Parameter 1";
CM_ SG_ 305 DwnLoadDynLitPrmLedReTurnIndcrLe1Tistamp "Light Show time stamp";
CM_ SG_ 305 DwnLoadDynLitPrmLedReTurnIndcrLe1UpprBriPrm "Light Show Upper Brightness Parameter 1";
CM_ SG_ 306 DwnLoadDynLitPrmLedReTurnIndcrLe2ContTiPrm "Light Show Continue Time Parameter 1";
CM_ SG_ 306 DwnLoadDynLitPrmLedReTurnIndcrLe2LowBriPrm "Light Show Lower Brightness Parameter 1";
CM_ SG_ 306 DwnLoadDynLitPrmLedReTurnIndcrLe2ModePrm "Light Show Mode Parameter 1";
CM_ SG_ 306 DwnLoadDynLitPrmLedReTurnIndcrLe2OffsTiPrm "Light Show Offset Time Parameter 1";
CM_ SG_ 306 DwnLoadDynLitPrmLedReTurnIndcrLe2Tistamp "Light Show time stamp";
CM_ SG_ 306 DwnLoadDynLitPrmLedReTurnIndcrLe2UpprBriPrm "Light Show Upper Brightness Parameter 1";
CM_ SG_ 307 DwnLoadDynLitPrmLedReTurnIndcrRi1ContTiPrm "Light Show Continue Time Parameter 1";
CM_ SG_ 307 DwnLoadDynLitPrmLedReTurnIndcrRi1LowBriPrm "Light Show Lower Brightness Parameter 1";
CM_ SG_ 307 DwnLoadDynLitPrmLedReTurnIndcrRi1ModePrm "Light Show Mode Parameter 1";
CM_ SG_ 307 DwnLoadDynLitPrmLedReTurnIndcrRi1OffsTiPrm "Light Show Offset Time Parameter 1";
CM_ SG_ 307 DwnLoadDynLitPrmLedReTurnIndcrRi1Tistamp "Light Show time stamp";
CM_ SG_ 307 DwnLoadDynLitPrmLedReTurnIndcrRi1UpprBriPrm "Light Show Upper Brightness Parameter 1";
CM_ SG_ 308 DwnLoadDynLitPrmLedRvsgLampLe1ContTiPrm "Light Show Continue Time Parameter 1";
CM_ SG_ 308 DwnLoadDynLitPrmLedRvsgLampLe1LowBriPrm "Light Show Lower Brightness Parameter 1";
CM_ SG_ 308 DwnLoadDynLitPrmLedRvsgLampLe1ModePrm "Light Show Mode Parameter 1";
CM_ SG_ 308 DwnLoadDynLitPrmLedRvsgLampLe1OffsTiPrm "Light Show Offset Time Parameter 1";
CM_ SG_ 308 DwnLoadDynLitPrmLedRvsgLampLe1Tistamp "Light Show time stamp";
CM_ SG_ 308 DwnLoadDynLitPrmLedRvsgLampLe1UpprBriPrm "Light Show Upper Brightness Parameter 1";
CM_ SG_ 309 DwnLoadDynLitPrmLedRvsgLampLe2ContTiPrm "Light Show Continue Time Parameter 1";
CM_ SG_ 309 DwnLoadDynLitPrmLedRvsgLampLe2LowBriPrm "Light Show Lower Brightness Parameter 1";
CM_ SG_ 309 DwnLoadDynLitPrmLedRvsgLampLe2ModePrm "Light Show Mode Parameter 1";
CM_ SG_ 309 DwnLoadDynLitPrmLedRvsgLampLe2OffsTiPrm "Light Show Offset Time Parameter 1";
CM_ SG_ 309 DwnLoadDynLitPrmLedRvsgLampLe2Tistamp "Light Show time stamp";
CM_ SG_ 309 DwnLoadDynLitPrmLedRvsgLampLe2UpprBriPrm "Light Show Upper Brightness Parameter 1";
CM_ SG_ 310 DwnLoadDynLitPrmLedRvsgLampRi1ContTiPrm "Light Show Continue Time Parameter 1";
CM_ SG_ 310 DwnLoadDynLitPrmLedRvsgLampRi1LowBriPrm "Light Show Lower Brightness Parameter 1";
CM_ SG_ 310 DwnLoadDynLitPrmLedRvsgLampRi1ModePrm "Light Show Mode Parameter 1";
CM_ SG_ 310 DwnLoadDynLitPrmLedRvsgLampRi1OffsTiPrm "Light Show Offset Time Parameter 1";
CM_ SG_ 310 DwnLoadDynLitPrmLedRvsgLampRi1Tistamp "Light Show time stamp";
CM_ SG_ 310 DwnLoadDynLitPrmLedRvsgLampRi1UpprBriPrm "Light Show Upper Brightness Parameter 1";
CM_ SG_ 120 CarpetLiModReq "this port is used to inform the exterior light subsystem the user choose which one mode of carpet light.";
CM_ SG_ 120 CarpetLiSwtReq "this port is used to inform exterior light subsystem whether driver want to active carpet light.";
CM_ SG_ 120 CarpetLiTiReq "this port is used to inform the exterior light subsystem the user choose how long of lighting carpet light.";
CM_ SG_ 120 DoorLeRePercSetFromHmi "This signal is used to set  percent of left rear side power door";
CM_ SG_ 120 DrvrPwrDoorManStrengthLvl "The level of Force Assist (manual strength) to close or open the driver side power door.
option:low/normal/high.";
CM_ SG_ 120 HvacRecircAct "Amount of recirculated air in front HVAC. ";
CM_ SG_ 120 LvlgSwtSetReqADModCtrlInhbn "0.LvlgSwtSetReq.Level0
1.LvlgSwtSetReq.Level1
2.LvlgSwtSetReq.Level2
3.LvlgSwtSetReq.Level3
4.LvlgSwtSetReq.Level4
5.LvlgSwtSetReq.Level5";
CM_ SG_ 120 LvlgSwtSetReqChks "checksum";
CM_ SG_ 120 LvlgSwtSetReqCntr "counter";
CM_ SG_ 120 OutdBriChks "Input for controlling lights on and off automatically. Checksum";
CM_ SG_ 120 OutdBriCntr "Input for controlling lights on and off automatically. Counter";
CM_ SG_ 120 OutdBriSts "Input for controlling lights on and off automatically. Status information.";
CM_ SG_ 311 DwnLoadDynLitPrmForLedHiBeamLeContTiPrm "Light Show Continue Time Parameter 1";
CM_ SG_ 311 DwnLoadDynLitPrmForLedHiBeamLeLowBriPrm "Light Show Lower Brightness Parameter 1";
CM_ SG_ 311 DwnLoadDynLitPrmForLedHiBeamLeModePrm "Light Show Mode Parameter 1";
CM_ SG_ 311 DwnLoadDynLitPrmForLedHiBeamLeOffsTiPrm "Light Show Offset time Parameter 1";
CM_ SG_ 311 DwnLoadDynLitPrmForLedHiBeamLeTistamp "Light Show time stamp";
CM_ SG_ 311 DwnLoadDynLitPrmForLedHiBeamLeUpprBriPrm "Light Show Upper Brightness Parameter 1";
CM_ SG_ 312 DwnLoadDynLitPrmForLedLoBeamLeContTiPrm "Light Show Continue Time Parameter 1";
CM_ SG_ 312 DwnLoadDynLitPrmForLedLoBeamLeLowBriPrm "Light Show Lower Brightness Parameter 1";
CM_ SG_ 312 DwnLoadDynLitPrmForLedLoBeamLeModePrm "Light Show Mode Parameter 1";
CM_ SG_ 312 DwnLoadDynLitPrmForLedLoBeamLeOffsTiPrm "Light Show Offset Time Parameter 1";
CM_ SG_ 312 DwnLoadDynLitPrmForLedLoBeamLeTistamp "Light Show time stamp";
CM_ SG_ 312 DwnLoadDynLitPrmForLedLoBeamLeUpprBriPrm "Light Show Upper Brightness Parameter 1";
CM_ SG_ 313 DwnLoadDynLtgPrmForLedAllWthrLampLeContTiPrm "Light Show Continue Time Parameter 1";
CM_ SG_ 313 DwnLoadDynLtgPrmForLedAllWthrLampLeLowBriPrm "Light Show Lower Brightness Parameter 1";
CM_ SG_ 313 DwnLoadDynLtgPrmForLedAllWthrLampLeModePrm "Light Show Mode Parameter 1";
CM_ SG_ 313 DwnLoadDynLtgPrmForLedAllWthrLampLeOffsTiPrm "Light Show Offset Time Parameter 1";
CM_ SG_ 313 DwnLoadDynLtgPrmForLedAllWthrLampLeTistamp "Light Show time stamp";
CM_ SG_ 313 DwnLoadDynLtgPrmForLedAllWthrLampLeUpprBriPrm "Light Show Upper Brightness Parameter 1";
CM_ SG_ 314 DwnLoadDynLtgPrmForLedAllWthrLampRiContTiPrm "Light Show Continue Time Parameter 1";
CM_ SG_ 314 DwnLoadDynLtgPrmForLedAllWthrLampRiLowBriPrm "Light Show Lower Brightness Parameter 1";
CM_ SG_ 314 DwnLoadDynLtgPrmForLedAllWthrLampRiModePrm "Light Show Mode Parameter 1";
CM_ SG_ 314 DwnLoadDynLtgPrmForLedAllWthrLampRiOffsTiPrm "Light Show Offset Time Parameter 1";
CM_ SG_ 314 DwnLoadDynLtgPrmForLedAllWthrLampRiTistamp "Light Show time stamp";
CM_ SG_ 314 DwnLoadDynLtgPrmForLedAllWthrLampRiUpprBriPrm "Light Show Upper Brightness Parameter 1";
CM_ SG_ 315 DwnLoadDynLtgPrmForLedCornrgLampLeContTiPrm "Light Show Continue Time Parameter 1";
CM_ SG_ 315 DwnLoadDynLtgPrmForLedCornrgLampLeLowBriPrm "Light Show Lower Brightness Parameter 1";
CM_ SG_ 315 DwnLoadDynLtgPrmForLedCornrgLampLeModePrm "Light Show Mode Parameter 1";
CM_ SG_ 315 DwnLoadDynLtgPrmForLedCornrgLampLeOffsTiPrm "Light Show Offset Time Parameter 1";
CM_ SG_ 315 DwnLoadDynLtgPrmForLedCornrgLampLeTistamp "Light Show time stamp";
CM_ SG_ 315 DwnLoadDynLtgPrmForLedCornrgLampLeUpprBriPrm "Light Show Upper Brightness Parameter 1";
CM_ SG_ 316 DwnLoadDynLtgPrmForLedCornrgLampRiContTiPrm "Light Show Continue Time Parameter 1";
CM_ SG_ 316 DwnLoadDynLtgPrmForLedCornrgLampRiLowBriPrm "Light Show Lower Brightness Parameter 1";
CM_ SG_ 316 DwnLoadDynLtgPrmForLedCornrgLampRiModePrm "Light Show Mode Parameter 1";
CM_ SG_ 316 DwnLoadDynLtgPrmForLedCornrgLampRiOffsTiPrm "Light Show Offset Time Parameter 1";
CM_ SG_ 316 DwnLoadDynLtgPrmForLedCornrgLampRiTistamp "Light Show time stamp";
CM_ SG_ 316 DwnLoadDynLtgPrmForLedCornrgLampRiUpprBriPrm "Light Show Upper Brightness Parameter 1";
CM_ SG_ 317 DwnLoadDynLtgPrmForLedDaytiRunngLampLeContTiPrm "Light Show Continue Time Parameter 1";
CM_ SG_ 317 DwnLoadDynLtgPrmForLedDaytiRunngLampLeLowBriPrm "Light Show Lower Brightness Parameter 1";
CM_ SG_ 317 DwnLoadDynLtgPrmForLedDaytiRunngLampLeModePrm "Light Show Mode Parameter 1";
CM_ SG_ 317 DwnLoadDynLtgPrmForLedDaytiRunngLampLeOffsTiPrm "Light Show Offset Time Parameter 1";
CM_ SG_ 317 DwnLoadDynLtgPrmForLedDaytiRunngLampLeTistamp "Light Show time stamp";
CM_ SG_ 317 DwnLoadDynLtgPrmForLedDaytiRunngLampLeUpprBriPrm "Light Show Upper Brightness Parameter 1";
CM_ SG_ 318 DwnLoadDynLtgPrmForLedDaytiRunngLampRiContTiPrm "Light Show Continue Time Parameter 1";
CM_ SG_ 318 DwnLoadDynLtgPrmForLedDaytiRunngLampRiLowBriPrm "Light Show Lower Brightness Parameter 1";
CM_ SG_ 318 DwnLoadDynLtgPrmForLedDaytiRunngLampRiModePrm "Light Show Mode Parameter 1";
CM_ SG_ 318 DwnLoadDynLtgPrmForLedDaytiRunngLampRiOffsTiPrm "Light Show Offset Time Parameter 1";
CM_ SG_ 318 DwnLoadDynLtgPrmForLedDaytiRunngLampRiTistamp "Light Show time stamp";
CM_ SG_ 318 DwnLoadDynLtgPrmForLedDaytiRunngLampRiUpprBriPrm "Light Show Upper Brightness Parameter 1";
CM_ SG_ 319 DwnLoadDynLtgPrmForLedFrntPosnLampLeContTiPrm "Light Show Continue Time Parameter 1";
CM_ SG_ 319 DwnLoadDynLtgPrmForLedFrntPosnLampLeLowBriPrm "Light Show Lower Brightness Parameter 1";
CM_ SG_ 319 DwnLoadDynLtgPrmForLedFrntPosnLampLeModePrm "Light Show Mode Parameter 1";
CM_ SG_ 319 DwnLoadDynLtgPrmForLedFrntPosnLampLeOffsTiPrm "Light Show Offset Time Parameter 1";
CM_ SG_ 319 DwnLoadDynLtgPrmForLedFrntPosnLampLeTistamp "Light Show time stamp";
CM_ SG_ 319 DwnLoadDynLtgPrmForLedFrntPosnLampLeUpprBriPrm "Light Show Upper Brightness Parameter 1";
CM_ SG_ 320 DwnLoadDynLtgPrmForLedFrntPosnLampRiContTiPrm "Light Show Continue Time Parameter 1";
CM_ SG_ 320 DwnLoadDynLtgPrmForLedFrntPosnLampRiLowBriPrm "Light Show Lower Brightness Parameter 1";
CM_ SG_ 320 DwnLoadDynLtgPrmForLedFrntPosnLampRiModePrm "Light Show Mode Parameter 1";
CM_ SG_ 320 DwnLoadDynLtgPrmForLedFrntPosnLampRiOffsTiPrm "Light Show Offset Time Parameter 1";
CM_ SG_ 320 DwnLoadDynLtgPrmForLedFrntPosnLampRiTistamp "Light Show time stamp";
CM_ SG_ 320 DwnLoadDynLtgPrmForLedFrntPosnLampRiUpprBriPrm "Light Show Upper Brightness Parameter 1";
CM_ SG_ 321 DwnLoadDynLtgPrmForLedFrntTurnIndcrLeContTiPrm "Light Show Continue Time Parameter 1";
CM_ SG_ 321 DwnLoadDynLtgPrmForLedFrntTurnIndcrLeLowBriPrm "Light Show Lower Brightness Parameter 1";
CM_ SG_ 321 DwnLoadDynLtgPrmForLedFrntTurnIndcrLeModePrm "Light Show Mode Parameter 1";
CM_ SG_ 321 DwnLoadDynLtgPrmForLedFrntTurnIndcrLeOffsTiPrm "Light Show Offset Time Parameter 1";
CM_ SG_ 321 DwnLoadDynLtgPrmForLedFrntTurnIndcrLeTistamp "Light Show time stamp";
CM_ SG_ 321 DwnLoadDynLtgPrmForLedFrntTurnIndcrLeUpprBriPrm "Light Show Upper Brightness Parameter 1";
CM_ SG_ 322 DwnLoadDynLtgPrmForLedFrntTurnIndcrRiContTiPrm "Light Show Continue Time Parameter 1";
CM_ SG_ 322 DwnLoadDynLtgPrmForLedFrntTurnIndcrRiLowBriPrm "Light Show Lower Brightness Parameter 1";
CM_ SG_ 322 DwnLoadDynLtgPrmForLedFrntTurnIndcrRiModePrm "Light Show Mode Parameter 1";
CM_ SG_ 322 DwnLoadDynLtgPrmForLedFrntTurnIndcrRiOffsTiPrm "Light Show Offset Time Parameter 1";
CM_ SG_ 322 DwnLoadDynLtgPrmForLedFrntTurnIndcrRiTistamp "Light Show time stamp";
CM_ SG_ 322 DwnLoadDynLtgPrmForLedFrntTurnIndcrRiUpprBriPrm "Light Show Upper Brightness Parameter 1";
CM_ SG_ 323 DwnLoadDynLtgPrmForLedHiBeamRiContTiPrm "Light Show Continue Time Parameter 1";
CM_ SG_ 323 DwnLoadDynLtgPrmForLedHiBeamRiLowBriPrm "Light Show Lower Brightness Parameter 1";
CM_ SG_ 323 DwnLoadDynLtgPrmForLedHiBeamRiModePrm "Light Show Mode Parameter 1";
CM_ SG_ 323 DwnLoadDynLtgPrmForLedHiBeamRiOffsTiPrm "Light Show Offset Time Parameter 1";
CM_ SG_ 323 DwnLoadDynLtgPrmForLedHiBeamRiTistamp "Light Show time stamp";
CM_ SG_ 323 DwnLoadDynLtgPrmForLedHiBeamRiUpprBriPrm "Light Show Upper Brightness Parameter 1";
CM_ SG_ 381 ActnOfLedFrntCrossLampDyn "Activation of Front Middle Cross Lamp as part of Position Lights with dynamic pattern";
CM_ SG_ 381 ActnOfLedGrilleLampDyn "Activation of Grille Lamp as part of Position Lights with dynamic pattern";
CM_ SG_ 381 ActnOfLedLeLogoLampDyn "Activation of Left Logo Lamp as part of Position Lights with dynamic pattern";
CM_ SG_ 381 ActnOfLedPosnLampDyn "Activation of Led Position Lamp Dynamic mode";
CM_ SG_ 381 ActnOfLedRiLogoLampDyn "Activation of Right Logo Lamp as part of Charging Lights with dynamic pattern";
CM_ SG_ 381 ActvnOfHomeSafe "Activate home safe light function";
CM_ SG_ 612 ActvnOfApproach "to indicate approach light function for dynmaic animation";
CM_ SG_ 612 ActvnOfCarLoctr "to indicate car locate function for dynmaic animation";
CM_ SG_ 612 ActvnOfReLogoLamp "The signal indicates the Rear Logo Lamp's activate/deactivate request from Other subsystem to Exterior Light subsystem. 1= Activate, 0 = Deactivate.";
CM_ SG_ 612 ActvnOfSayHi "to indicate Say Hi function for dynmaic animation";
CM_ SG_ 612 ActvnOfWaitMode "Activate signal to actuator to implement wait mode animation";
CM_ SG_ 612 BrkPedlValBrkPedlVal "Position of the brake pedal. Physical lower limit: no pedal activation. Physical upper limit: full pedal stroke Brake pedal position";
CM_ SG_ 612 BrkPedlValQf "Position of the brake pedal. Physical lower limit: no pedal activation. Physical upper limit: full pedal stroke Brake pedal sensor quality factor";
CM_ SG_ 612 CinhDrvrSts "CinhDrvrSts - Driver Door cinch Status";
CM_ SG_ 612 CinhDrvrSwt "driver door Cinch switch status";
CM_ SG_ 612 CinhLeReSts "CinhLeReSts -  Left rear Door cinch Status";
CM_ SG_ 612 CinhLeReSwt " Left rear door Cinch switch status";
CM_ SG_ 612 CinhPassSts "passenger door Cinch switch status";
CM_ SG_ 612 CinhPassSwt "passenger door Cinch switch status";
CM_ SG_ 612 CinhRiReSts "CinhRiReSts -  Rigth rear Door cinch Status";
CM_ SG_ 612 CinhRiReSwt " Rigth rear door Cinch switch status";
CM_ SG_ 612 HmiHvacFanLvlFrnt "Hmi Hvac Fan Level Front";
CM_ SG_ 612 IndcrNoSeq "to indicate if HWL or DI with sequence";
CM_ SG_ 612 LitArea "Whether the host vehicle is in a lit area";
CM_ SG_ 612 ReLePwrDoorManStrengthLvl "The level of Force Assist (manual strength) to close or open the rear row left side power door.
option:low/normal/high.";
CM_ SG_ 612 WipgInfoWipgSpdInfo "Information regarding how the wipers are run";
CM_ SG_ 612 WipgInfoWiprActv " 0 No wiping, 1 Wiping";
CM_ SG_ 612 WipgInfoWiprInWipgAr " 0 Wiper in lower reversing area or parked, 1 Wiper in wiping area";
CM_ SG_ 324 DwnLoadDynLitPrmForLedMkrLampRi2ContTiPrm "Light Show Continue Time Parameter 1";
CM_ SG_ 324 DwnLoadDynLitPrmForLedMkrLampRi2LowBriPrm "Light Show Lower Brightness Parameter 1";
CM_ SG_ 324 DwnLoadDynLitPrmForLedMkrLampRi2ModePrm "Light Show Mode Parameter 1";
CM_ SG_ 324 DwnLoadDynLitPrmForLedMkrLampRi2OffsTiPrm "Light Show Offset Time Parameter 1";
CM_ SG_ 324 DwnLoadDynLitPrmForLedMkrLampRi2Tistamp "Light Show time stamp";
CM_ SG_ 324 DwnLoadDynLitPrmForLedMkrLampRi2UpprBriPrm "Light Show Upper Brightness Parameter 1";
CM_ SG_ 325 DwnLoadDynLitPrmLedRvsgLampRi2ContTiPrm "Light Show Continue Time Parameter 1";
CM_ SG_ 325 DwnLoadDynLitPrmLedRvsgLampRi2LowBriPrm "Light Show Lower Brightness Parameter 1";
CM_ SG_ 325 DwnLoadDynLitPrmLedRvsgLampRi2ModePrm "Light Show Mode Parameter 1";
CM_ SG_ 325 DwnLoadDynLitPrmLedRvsgLampRi2OffsTiPrm "Light Show Offset Time Parameter 1";
CM_ SG_ 325 DwnLoadDynLitPrmLedRvsgLampRi2Tistamp "Light Show time stamp";
CM_ SG_ 325 DwnLoadDynLitPrmLedRvsgLampRi2UpprBriPrm "Light Show Upper Brightness Parameter 1";
CM_ SG_ 522 ActnOfLedCornrgLampLe "Acitvation of Led Cornering Lamp Left";
CM_ SG_ 522 ActnOfLedCornrgLampRi "Activate LED Cornering Lamp Right.";
CM_ SG_ 522 ActnOfLedDaytiRunngLamp "Activate LED Daytime Running Lamp.";
CM_ SG_ 522 ActnOfLedFrntFogLamp "Activate LED Front Fog Lamp.";
CM_ SG_ 522 ActnOfLedHiBeam "Activate LED High Beam.";
CM_ SG_ 522 ActnOfLedLoBeamActnOfLedLoBeam "Activation of Low Beam function to HCM";
CM_ SG_ 522 ActnOfLedLoBeamChks "Low Beam Check Sum ASIL B";
CM_ SG_ 522 ActnOfLedLoBeamCntr "Low Beam Counter ASIL B";
CM_ SG_ 522 ActnOfLedPosnLamp "Activate LED Position Lamp.";
CM_ SG_ 522 ActnOfLedReFogLamp "Activate LED Rear Fog Lamp.";
CM_ SG_ 522 ActnOfLedRePosnLamp "Activate LED Position Lamp.";
CM_ SG_ 522 ActnOfLedRvsgLamp "Activate LED Revering Lamp.";
CM_ SG_ 522 ActnOfLedStopLampActnOfLedStopLamp "Activation of Stop Lamps by HCM";
CM_ SG_ 522 ActnOfLedStopLampChks "Stop Lamps Check Sum ASIL B";
CM_ SG_ 522 ActnOfLedStopLampCntr "Stop Lamps Counter ASIL B";
CM_ SG_ 522 ActvnOfAfs "Activation of Aaptive Frontlight System ";
CM_ SG_ 522 ActvnOfAhbc "Activate Auto High Beam Control.";
CM_ SG_ 522 ActvnOfAhl "Activate Auto Headlamp Leveling";
CM_ SG_ 522 ActvnOfBrkLi "Activation of Break Light";
CM_ SG_ 522 ActvnOfDbl "Activate Bending Light.";
CM_ SG_ 522 ActvnOfGoodByeLi "Activation Request for Goodbye Light";
CM_ SG_ 522 ActvnOfTouristMod "Activate Tourist Mode.";
CM_ SG_ 522 ActvnOfWelcomeLi "Activation Request for Welcome Light";
CM_ SG_ 538 ActvnOfIndcrIndcrOut "Direction indicator command";
CM_ SG_ 538 ActvnOfIndcrIndcrOutChks "CheckSum";
CM_ SG_ 538 ActvnOfIndcrIndcrOutCntr "Coounter";
CM_ SG_ 538 DoorLeReAutoManReq "Left rear side door auto or manul selection";
CM_ SG_ 538 DoorPassAutoManReq "Pass side door auto or manul selection";
CM_ SG_ 538 DoorRiReAutoManReq "Right rear side door auto or manul selection";
CM_ SG_ 538 EmgyBrkLiIndcrTurn "Activation of both rear direction indicators for EBL.";
CM_ SG_ 538 IndcrPatCmd1WdTiOff "Used for Hazard Sleep (subfunction to Hazard Warning Light).

This signal holds the pattern of the flashing to use when buses are asleep and TRM/DCUs shall flash synchronized by themselves.

Holds both on and off timing in two separate record items. HWL Off time";
CM_ SG_ 538 IndcrPatCmd1WdTiOn "Used for Hazard Sleep (subfunction to Hazard Warning Light).

This signal holds the pattern of the flashing to use when buses are asleep and TRM/DCUs shall flash synchronized by themselves.

Holds both on and off timing in two separate record items. HWL On time";
CM_ SG_ 538 IndcrSts "Provides the state and not the event of HWL/Direction Indicator.";
CM_ SG_ 326 DwnLoadDynLitPrmForLedLogoLampContTiPrm "Light Show Continue Time Parameter 1";
CM_ SG_ 326 DwnLoadDynLitPrmForLedLogoLampLowBriPrm "Light Show Lower Brightness Parameter 1";
CM_ SG_ 326 DwnLoadDynLitPrmForLedLogoLampModePrm "Light Show Mode Parameter 1";
CM_ SG_ 326 DwnLoadDynLitPrmForLedLogoLampOffsTiPrm "Light Show Offset Time Parameter 1";
CM_ SG_ 326 DwnLoadDynLitPrmForLedLogoLampTistamp "Light Show time stamp";
CM_ SG_ 326 DwnLoadDynLitPrmForLedLogoLampUpprBriPrm "Light Show Upper Brightness Parameter 1";
CM_ SG_ 327 DwnLoadDynLitPrmLedRePosnLampLe3ContTiPrm "Light Show Offset Time Parameter 1";
CM_ SG_ 327 DwnLoadDynLitPrmLedRePosnLampLe3LowBriPrm "Light Show Lower Brightness Parameter 1";
CM_ SG_ 327 DwnLoadDynLitPrmLedRePosnLampLe3ModePrm "Light Show Mode Parameter 1";
CM_ SG_ 327 DwnLoadDynLitPrmLedRePosnLampLe3OffsTiPrm "Light Show Offset Time Parameter 1";
CM_ SG_ 327 DwnLoadDynLitPrmLedRePosnLampLe3Tistamp "Light Show time stamp";
CM_ SG_ 327 DwnLoadDynLitPrmLedRePosnLampLe3UpprBriPrm "Light Show Upper Brightness Parameter 1";
CM_ SG_ 328 DwnLoadDynLitPrmLedRePosnLampLe4ContTiPrm "Light Show Continue Time Parameter 1";
CM_ SG_ 328 DwnLoadDynLitPrmLedRePosnLampLe4LowBriPrm "Light Show Lower Brightness Parameter 1";
CM_ SG_ 328 DwnLoadDynLitPrmLedRePosnLampLe4ModePrm "Light Show Mode Parameter 1";
CM_ SG_ 328 DwnLoadDynLitPrmLedRePosnLampLe4OffsTiPrm "Light Show Offset Time Parameter 1";
CM_ SG_ 328 DwnLoadDynLitPrmLedRePosnLampLe4Tistamp "Light Show time stamp";
CM_ SG_ 328 DwnLoadDynLitPrmLedRePosnLampLe4UpprBriPrm "Light Show Upper Brightness Parameter 1";
CM_ SG_ 329 DwnLoadDynLitPrmLedRePosnLampLe5ContTiPrm "Light Show Continue Time Parameter 1";
CM_ SG_ 329 DwnLoadDynLitPrmLedRePosnLampLe5LowBriPrm "Light Show Lower Brightness Parameter 1";
CM_ SG_ 329 DwnLoadDynLitPrmLedRePosnLampLe5ModePrm "Light Show Mode Parameter 1";
CM_ SG_ 329 DwnLoadDynLitPrmLedRePosnLampLe5OffsTiPrm "Light Show Offset Time Parameter 1";
CM_ SG_ 329 DwnLoadDynLitPrmLedRePosnLampLe5Tistamp "Light Show time stamp";
CM_ SG_ 329 DwnLoadDynLitPrmLedRePosnLampLe5UpprBriPrm "Light Show Upper Brightness Parameter 1";
CM_ SG_ 330 DwnLoadDynLitPrmLedRePosnLampRi3ContTiPrm "Light Show Continue Time Parameter 1";
CM_ SG_ 330 DwnLoadDynLitPrmLedRePosnLampRi3LowBriPrm "Light Show Lower Brightness Parameter 1";
CM_ SG_ 330 DwnLoadDynLitPrmLedRePosnLampRi3ModePrm "Light Show Mode Parameter 1";
CM_ SG_ 330 DwnLoadDynLitPrmLedRePosnLampRi3OffsTiPrm "Light Show Offset Time Parameter 1";
CM_ SG_ 330 DwnLoadDynLitPrmLedRePosnLampRi3Tistamp "Light Show time stamp";
CM_ SG_ 330 DwnLoadDynLitPrmLedRePosnLampRi3UpprBriPrm "Light Show Upper Brightness Parameter 1";
CM_ SG_ 331 DwnLoadDynLitPrmLedRePosnLampRi4ContTiPrm "Light Show Continue Time Parameter 1";
CM_ SG_ 331 DwnLoadDynLitPrmLedRePosnLampRi4LowBriPrm "Light Show Lower Brightness Parameter 1";
CM_ SG_ 331 DwnLoadDynLitPrmLedRePosnLampRi4ModePrm "Light Show Mode Parameter 1";
CM_ SG_ 331 DwnLoadDynLitPrmLedRePosnLampRi4OffsTiPrm "Light Show Offset Time Parameter 1";
CM_ SG_ 331 DwnLoadDynLitPrmLedRePosnLampRi4Tistamp "Light Show time stamp";
CM_ SG_ 331 DwnLoadDynLitPrmLedRePosnLampRi4UpprBriPrm "Light Show Upper Brightness Parameter 1";
CM_ SG_ 332 DwnLoadDynLitPrmLedRePosnLampRi5ContTiPrm "Light Show Continue Time Parameter 1";
CM_ SG_ 332 DwnLoadDynLitPrmLedRePosnLampRi5LowBriPrm "Light Show Lower Brightness Parameter 1";
CM_ SG_ 332 DwnLoadDynLitPrmLedRePosnLampRi5ModePrm "Light Show Mode Parameter 1";
CM_ SG_ 332 DwnLoadDynLitPrmLedRePosnLampRi5OffsTiPrm "Light Show Offset Time Parameter 1";
CM_ SG_ 332 DwnLoadDynLitPrmLedRePosnLampRi5Tistamp "Light Show time stamp";
CM_ SG_ 332 DwnLoadDynLitPrmLedRePosnLampRi5UpprBriPrm "Light Show Upper Brightness Parameter 1";
CM_ SG_ 24 DoorDrvrPercSetFromHmi "This signal is used to set  percent of drive side power door";
CM_ SG_ 24 DoorDrvrSts "DoorDrvrSts - Driver Door Status
Ukwn - Unknown status
Opend - Opened
Clsd - Closed";
CM_ SG_ 24 DoorLeReSts "DoorLeReSts - Left Rear Side Door Status.
Ukwn - Unknown status
Opend - Opened
Clsd - Closed";
CM_ SG_ 24 DoorOpenwarnLeIndcn "Indicates if a left door open,warning shall be shown to the driver or not.
If the left door open (FL door open or  RL door open or FL and RL both open), the warning signal will send out.";
CM_ SG_ 24 DoorOpenwarnOn1 "Shows the DOW function status. ";
CM_ SG_ 24 DoorOpenwarnRiIndcn "Indicates if a right door open, warning shall be shown to the driver or not.
If the right door open( FR door open or  RR door open or FR and RR both open), the warning signal will send out.";
CM_ SG_ 24 DoorPassPercSetFromHmi "This signal is used to set  percent of passenger side  power door";
CM_ SG_ 24 DoorRiRePercSetFromHmi "This signal is used to set  percent of right rear side power door";
CM_ SG_ 24 GrilleLampColorSelnReq "This signal is used to select color for Grille Lamp.";
CM_ SG_ 24 HvBattSoc "Actual state of charge of the Hv Battery.";
CM_ SG_ 24 PassPwrDoorManStrengthLvl "The level of Force Assist (manual strength) to close or open the passenger side power door.
option:low/normal/high.";
CM_ SG_ 24 WelcomeGoodbyeModeReq "this port is used to inform the CEM the user choose which one mode of  welcome goodbye  founction.";
CM_ SG_ 333 DwnLoadDynLitPrmLedLeGrilleLampContTiPrm "Light Show Continue Time Parameter 1";
CM_ SG_ 333 DwnLoadDynLitPrmLedLeGrilleLampLowBriPrm "Light Show Lower Brightness Parameter 1";
CM_ SG_ 333 DwnLoadDynLitPrmLedLeGrilleLampModePrm "Light Show Mode Parameter 1";
CM_ SG_ 333 DwnLoadDynLitPrmLedLeGrilleLampOffsTiPrm "Light Show Offset Time Parameter 1";
CM_ SG_ 333 DwnLoadDynLitPrmLedLeGrilleLampTistamp "Light Show time stamp";
CM_ SG_ 333 DwnLoadDynLitPrmLedLeGrilleLampUpprBriPrm "Light Show Upper Brightness Parameter 1";
CM_ SG_ 334 DwnLoadDynLitPrmLedRiGrilleLampContTiPrm "Light Show Continue Time Parameter 1";
CM_ SG_ 334 DwnLoadDynLitPrmLedRiGrilleLampLowBriPrm "Light Show Lower Brightness Parameter 1";
CM_ SG_ 334 DwnLoadDynLitPrmLedRiGrilleLampModePrm "Light Show Mode Parameter 1";
CM_ SG_ 334 DwnLoadDynLitPrmLedRiGrilleLampOffsTiPrm "Light Show Offset Time Parameter 1";
CM_ SG_ 334 DwnLoadDynLitPrmLedRiGrilleLampTistamp "Light Show time stamp";
CM_ SG_ 334 DwnLoadDynLitPrmLedRiGrilleLampUpprBriPrm "Light Show Upper Brightness Parameter 1";
CM_ SG_ 788 DHUcontrolLedMkrLampLe1 "DHU control LedMkrLampLe1
0 = OnOffNoReqNoReq
1 = OnOffNoReqOn
2 = OnOffNoReqOff";
CM_ SG_ 788 DHUcontrolLedMkrLampLe2 "DHU control LedMkrLampLe2
0 = OnOffNoReqNoReq
1 = OnOffNoReqOn
2 = OnOffNoReqOff";
CM_ SG_ 788 DHUcontrolLedMkrLampRi1 "DHU control LedMkrLampRi1
0 = OnOffNoReqNoReq
1 = OnOffNoReqOn
2 = OnOffNoReqOff
";
CM_ SG_ 788 DHUcontrolLedMkrLampRi2 "DHU control LedMkrLampRi2
0 = OnOffNoReqNoReq
1 = OnOffNoReqOn
2 = OnOffNoReqOff





";
CM_ SG_ 788 DHUcontrolLedStopLampLe1 "DHU control LedStopLampLe1
0 = OnOffNoReqNoReq
1 = OnOffNoReqOn
2 = OnOffNoReqOff";
CM_ SG_ 788 DHUcontrolLedStopLampLe2 "DHU control LedStopLampLe2
0 = OnOffNoReqNoReq
1 = OnOffNoReqOn
2 = OnOffNoReqOff


";
CM_ SG_ 788 DHUcontrolLedStopLampRi1 "DHU control LedStopLampRi1
0 = OnOffNoReqNoReq
1 = OnOffNoReqOn
2 = OnOffNoReqOff
";
CM_ SG_ 788 DHUcontrolLedStopLampRi2 "DHU control stop lamp RI2";
CM_ SG_ 788 DHUcontrolmiddlebrakelight "DHU control middle brake light
0 = OnOffNoReqNoReq
1 = OnOffNoReqOn
2 = OnOffNoReqOff
";
CM_ SG_ 788 DHUcontrolmiddlecorneringlamp "DHU control middle cornering lamp
0 = OnOffNoReqNoReq
1 = OnOffNoReqOn
2 = OnOffNoReqOff";
CM_ SG_ 788 DHUcontrolmiddlepositionlight "DHU control middle position light
0 = OnOffNoReqNoReq
1 = OnOffNoReqOn
2 = OnOffNoReqOff";
BA_DEF_ BO_ "GenMsgSendType" ENUM "cyclic", "spontaneous", "not-used", "not-used", "not-used", "cyclicAndSpontaneous", "not-used", "cyclicIfActive", "NoMsgSendType"; // [us]
BA_DEF_ BO_ "GenMsgCycleTime" INT 0 65536; // [ms]
BA_DEF_ BO_ "GenMsgStartDelayTime" INT 0 65536; // [ms]
BA_DEF_ BO_ "GenMsgDelayTime" INT 0 65536; // [ms]
BA_DEF_ SG_ "GenSigSendType" ENUM "Cyclic","OnWrite","OnWriteWithRepetition","OnChange","OnChangeWithRepetition","IfActive","IfActiveWithRepetition","NoSigSendType";
BA_DEF_ SG_ "GenSigStartValue" HEX 0 80000000;
BA_DEF_ BO_ "GenMsgILSupport" ENUM "No","Yes";
BA_DEF_ BO_ "NmAsrMessage" ENUM "No","Yes";
BA_DEF_ SG_ "GenSigFuncType" ENUM "NoFunction","n/a","n/a","n/a","n/a","n/a","n/a","n/a","n/a","n/a","n/a","n/a","n/a","n/a","n/a","CHK","CNTR","n/a","n/a","n/a","CNTR_AR_01","CRC_AR_01_BOTH","CRC_AR_01_ALT","CRC_AR_01_LOW","CRC_AR_01_NIBBLE","CNTR_AR_04","CRC_AR_04A","CNTR_AR_05","CRC_AR_05";
BA_DEF_ SG_ "GenSigDataID" STRING;
BA_DEF_ SG_ "SigGroup" STRING;

BA_DEF_DEF_ "GenSigStartValue" 0;
BA_DEF_DEF_ "GenSigSendType" "NoSigSendType";
BA_DEF_DEF_ "GenMsgCycleTime" 0;
BA_DEF_DEF_ "GenMsgDelayTime" 0;
BA_DEF_DEF_ "GenMsgStartDelayTime" 0;
BA_DEF_DEF_ "GenMsgSendType" "NoMsgSendType";
BA_DEF_DEF_ "GenMsgILSupport" "Yes";
BA_DEF_DEF_ "NmAsrMessage" "No";
BA_DEF_DEF_ "GenSigFuncType" "NoFunction";
BA_DEF_DEF_ "GenSigDataID" "";
BA_DEF_DEF_ "SigGroup" "";
// Frame: CemBodyExpoFr118
BA_ "GenMsgSendType" BO_ 360 0;
BA_ "GenMsgCycleTime" BO_ 360 60.000;
BA_ "GenSigStartValue" SG_ 360 DoorOpenerPassReqChks 255;
BA_ "GenSigSendType" SG_ 360 DoorOpenerPassReqChks 0;
BA_ "GenSigFuncType" SG_ 360 DoorOpenerPassReqChks 15;
BA_ "GenSigDataID" SG_ 360 DoorOpenerPassReqChks "0x43D";
BA_ "GenSigSendType" SG_ 360 DoorOpenerPassReqCntr 0;
BA_ "GenSigFuncType" SG_ 360 DoorOpenerPassReqCntr 16;
BA_ "GenSigSendType" SG_ 360 DoorOpenerPassReqDoorOpenerReq 0;
BA_ "GenSigSendType" SG_ 360 DoorOpenerPassReqTrigSrc 0;
BA_ "GenSigStartValue" SG_ 360 DoorOpenerRiReReqChks 255;
BA_ "GenSigSendType" SG_ 360 DoorOpenerRiReReqChks 0;
BA_ "GenSigFuncType" SG_ 360 DoorOpenerRiReReqChks 15;
BA_ "GenSigDataID" SG_ 360 DoorOpenerRiReReqChks "0x43E";
BA_ "GenSigSendType" SG_ 360 DoorOpenerRiReReqCntr 0;
BA_ "GenSigFuncType" SG_ 360 DoorOpenerRiReReqCntr 16;
BA_ "GenSigSendType" SG_ 360 DoorOpenerRiReReqDoorOpenerReq 0;
BA_ "GenSigSendType" SG_ 360 DoorOpenerRiReReqTrigSrc 0;
BA_ "GenSigStartValue" SG_ 360 RadioFrqAM -522;
BA_ "GenSigSendType" SG_ 360 RadioFrqAM 0;
BA_ "GenSigStartValue" SG_ 360 ReRiPwrDoorManStrengthLvl 2;
BA_ "GenSigSendType" SG_ 360 ReRiPwrDoorManStrengthLvl 0;
// Frame: CemBodyExpoFr119
BA_ "GenMsgSendType" BO_ 86 1;
BA_ "GenMsgDelayTime" BO_ 86 20.000;
BA_ "GenSigSendType" SG_ 86 DHUcontrolleftcorneringlamp 1;
BA_ "GenSigSendType" SG_ 86 DHUcontrolleftdaytimerunninglamp 1;
BA_ "GenSigSendType" SG_ 86 DHUcontrolleftfroglight 1;
BA_ "GenSigSendType" SG_ 86 DHUcontrollefthighbeamlamp 1;
BA_ "GenSigSendType" SG_ 86 DHUcontrolleftlowbeamlamp 1;
BA_ "GenSigSendType" SG_ 86 DHUcontrolleftpositionlamp 1;
BA_ "GenSigSendType" SG_ 86 DHUcontrolrightcorneringlamp 1;
BA_ "GenSigSendType" SG_ 86 DHUcontrolrightdaytimerunninglamp 1;
BA_ "GenSigSendType" SG_ 86 DHUcontrolrightfroglight 1;
BA_ "GenSigSendType" SG_ 86 DHUcontrolrighthighbeamlamp 1;
BA_ "GenSigSendType" SG_ 86 DHUcontrolrightlowbeamlamp 1;
BA_ "GenSigSendType" SG_ 86 DHUcontrolrightpositionLamp 1;
// Frame: CemBodyExpoFr12
BA_ "GenMsgSendType" BO_ 298 1;
BA_ "GenMsgDelayTime" BO_ 298 30.000;
BA_ "GenSigSendType" SG_ 298 DwnLoadDynLitPrmForLedStopLampRi1ContTiPrm 1;
BA_ "SigGroup" SG_ 298 DwnLoadDynLitPrmForLedStopLampRi1ContTiPrm "DwnLoadDynLitPrmForLedStopLampRi1";
BA_ "GenSigSendType" SG_ 298 DwnLoadDynLitPrmForLedStopLampRi1LowBriPrm 1;
BA_ "SigGroup" SG_ 298 DwnLoadDynLitPrmForLedStopLampRi1LowBriPrm "DwnLoadDynLitPrmForLedStopLampRi1";
BA_ "GenSigSendType" SG_ 298 DwnLoadDynLitPrmForLedStopLampRi1ModePrm 1;
BA_ "SigGroup" SG_ 298 DwnLoadDynLitPrmForLedStopLampRi1ModePrm "DwnLoadDynLitPrmForLedStopLampRi1";
BA_ "GenSigSendType" SG_ 298 DwnLoadDynLitPrmForLedStopLampRi1OffsTiPrm 1;
BA_ "SigGroup" SG_ 298 DwnLoadDynLitPrmForLedStopLampRi1OffsTiPrm "DwnLoadDynLitPrmForLedStopLampRi1";
BA_ "GenSigSendType" SG_ 298 DwnLoadDynLitPrmForLedStopLampRi1Tistamp 1;
BA_ "SigGroup" SG_ 298 DwnLoadDynLitPrmForLedStopLampRi1Tistamp "DwnLoadDynLitPrmForLedStopLampRi1";
BA_ "GenSigSendType" SG_ 298 DwnLoadDynLitPrmForLedStopLampRi1UpprBriPrm 1;
BA_ "SigGroup" SG_ 298 DwnLoadDynLitPrmForLedStopLampRi1UpprBriPrm "DwnLoadDynLitPrmForLedStopLampRi1";
// Frame: CemBodyExpoFr120
BA_ "GenMsgSendType" BO_ 523 0;
BA_ "GenMsgCycleTime" BO_ 523 50.000;
BA_ "GenSigSendType" SG_ 523 ActvOfGdbyeForGndLampLe 0;
BA_ "GenSigSendType" SG_ 523 ActvOfWelcomeForGndLampLe 0;
BA_ "GenSigStartValue" SG_ 523 RoadInclnQly 1;
BA_ "GenSigSendType" SG_ 523 RoadInclnQly 0;
BA_ "GenSigSendType" SG_ 523 RoadInclnRoadIncln 0;
BA_ "GenSigStartValue" SG_ 523 RollAgGlbQf 1;
BA_ "GenSigSendType" SG_ 523 RollAgGlbQf 0;
BA_ "GenSigSendType" SG_ 523 RollAgGlbVal 0;
// Frame: CemBodyExpoFr121
BA_ "GenMsgSendType" BO_ 640 0;
BA_ "GenMsgCycleTime" BO_ 640 150.000;
BA_ "GenSigSendType" SG_ 640 WinPosnStsAtDrvr 0;
BA_ "GenSigSendType" SG_ 640 WinPosnStsAtPass 0;
BA_ "GenSigSendType" SG_ 640 WinPosnStsAtReLe 0;
BA_ "GenSigSendType" SG_ 640 WinPosnStsAtReRi 0;
// Frame: CemBodyExpoFr122
BA_ "GenMsgSendType" BO_ 1110 1;
BA_ "GenMsgDelayTime" BO_ 1110 1000.000;
BA_ "GenSigSendType" SG_ 1110 VFCInfoEna 1;
// Frame: CemBodyExpoFr123
BA_ "GenMsgSendType" BO_ 359 1;
BA_ "GenMsgDelayTime" BO_ 359 200.000;
BA_ "GenSigSendType" SG_ 359 CarpetLiSetCarpetLiSet 1;
BA_ "GenSigSendType" SG_ 359 CarpetLiSetPerc12 1;
BA_ "GenSigSendType" SG_ 359 CarpetLiTrialSetPerc12 1;
BA_ "GenSigSendType" SG_ 359 CarpetLiTrialSetTrialSet 1;
// Frame: CemBodyExpoFr13
BA_ "GenMsgSendType" BO_ 299 1;
BA_ "GenMsgDelayTime" BO_ 299 30.000;
BA_ "GenSigSendType" SG_ 299 DwnLoadDynLitPrmLedReFogLampLe1ContTiPrm 1;
BA_ "GenSigSendType" SG_ 299 DwnLoadDynLitPrmLedReFogLampLe1LowBriPrm 1;
BA_ "GenSigSendType" SG_ 299 DwnLoadDynLitPrmLedReFogLampLe1ModePrm 1;
BA_ "GenSigSendType" SG_ 299 DwnLoadDynLitPrmLedReFogLampLe1OffsTiPrm 1;
BA_ "GenSigSendType" SG_ 299 DwnLoadDynLitPrmLedReFogLampLe1Tistamp 1;
BA_ "GenSigSendType" SG_ 299 DwnLoadDynLitPrmLedReFogLampLe1UpprBriPrm 1;
// Frame: CemBodyExpoFr14
BA_ "GenMsgSendType" BO_ 300 1;
BA_ "GenMsgDelayTime" BO_ 300 30.000;
BA_ "GenSigSendType" SG_ 300 DwnLoadDynLitPrmLedReFogLampLe2ContTiPrm 1;
BA_ "GenSigSendType" SG_ 300 DwnLoadDynLitPrmLedReFogLampLe2LowBriPrm 1;
BA_ "GenSigSendType" SG_ 300 DwnLoadDynLitPrmLedReFogLampLe2ModePrm 1;
BA_ "GenSigSendType" SG_ 300 DwnLoadDynLitPrmLedReFogLampLe2OffsTiPrm 1;
BA_ "GenSigSendType" SG_ 300 DwnLoadDynLitPrmLedReFogLampLe2Tistamp 1;
BA_ "GenSigSendType" SG_ 300 DwnLoadDynLitPrmLedReFogLampLe2UpprBriPrm 1;
// Frame: CemBodyExpoFr15
BA_ "GenMsgSendType" BO_ 301 1;
BA_ "GenMsgDelayTime" BO_ 301 30.000;
BA_ "GenSigSendType" SG_ 301 DwnLoadDynLitPrmLedReFogLampRi1ContTiPrm 1;
BA_ "GenSigSendType" SG_ 301 DwnLoadDynLitPrmLedReFogLampRi1LowBriPrm 1;
BA_ "GenSigSendType" SG_ 301 DwnLoadDynLitPrmLedReFogLampRi1ModePrm 1;
BA_ "GenSigSendType" SG_ 301 DwnLoadDynLitPrmLedReFogLampRi1OffsTiPrm 1;
BA_ "GenSigSendType" SG_ 301 DwnLoadDynLitPrmLedReFogLampRi1Tistamp 1;
BA_ "GenSigSendType" SG_ 301 DwnLoadDynLitPrmLedReFogLampRi1UpprBriPrm 1;
// Frame: CemBodyExpoFr16
BA_ "GenMsgSendType" BO_ 302 1;
BA_ "GenMsgDelayTime" BO_ 302 30.000;
BA_ "GenSigSendType" SG_ 302 DwnLoadDynLitPrmLedRePosnLampLe1ContTiPrm 1;
BA_ "SigGroup" SG_ 302 DwnLoadDynLitPrmLedRePosnLampLe1ContTiPrm "DwnLoadDynLitPrmLedRePosnLampLe1";
BA_ "GenSigSendType" SG_ 302 DwnLoadDynLitPrmLedRePosnLampLe1LowBriPrm 1;
BA_ "SigGroup" SG_ 302 DwnLoadDynLitPrmLedRePosnLampLe1LowBriPrm "DwnLoadDynLitPrmLedRePosnLampLe1";
BA_ "GenSigSendType" SG_ 302 DwnLoadDynLitPrmLedRePosnLampLe1ModePrm 1;
BA_ "SigGroup" SG_ 302 DwnLoadDynLitPrmLedRePosnLampLe1ModePrm "DwnLoadDynLitPrmLedRePosnLampLe1";
BA_ "GenSigSendType" SG_ 302 DwnLoadDynLitPrmLedRePosnLampLe1OffsTiPrm 1;
BA_ "SigGroup" SG_ 302 DwnLoadDynLitPrmLedRePosnLampLe1OffsTiPrm "DwnLoadDynLitPrmLedRePosnLampLe1";
BA_ "GenSigSendType" SG_ 302 DwnLoadDynLitPrmLedRePosnLampLe1Tistamp 1;
BA_ "SigGroup" SG_ 302 DwnLoadDynLitPrmLedRePosnLampLe1Tistamp "DwnLoadDynLitPrmLedRePosnLampLe1";
BA_ "GenSigSendType" SG_ 302 DwnLoadDynLitPrmLedRePosnLampLe1UpprBriPrm 1;
BA_ "SigGroup" SG_ 302 DwnLoadDynLitPrmLedRePosnLampLe1UpprBriPrm "DwnLoadDynLitPrmLedRePosnLampLe1";
// Frame: CemBodyExpoFr17
BA_ "GenMsgSendType" BO_ 303 1;
BA_ "GenMsgDelayTime" BO_ 303 30.000;
BA_ "GenSigSendType" SG_ 303 DwnLoadDynLitPrmLedRePosnLampLe2ContTiPrm 1;
BA_ "SigGroup" SG_ 303 DwnLoadDynLitPrmLedRePosnLampLe2ContTiPrm "DwnLoadDynLitPrmLedRePosnLampLe2";
BA_ "GenSigSendType" SG_ 303 DwnLoadDynLitPrmLedRePosnLampLe2LowBriPrm 1;
BA_ "SigGroup" SG_ 303 DwnLoadDynLitPrmLedRePosnLampLe2LowBriPrm "DwnLoadDynLitPrmLedRePosnLampLe2";
BA_ "GenSigSendType" SG_ 303 DwnLoadDynLitPrmLedRePosnLampLe2ModePrm 1;
BA_ "SigGroup" SG_ 303 DwnLoadDynLitPrmLedRePosnLampLe2ModePrm "DwnLoadDynLitPrmLedRePosnLampLe2";
BA_ "GenSigSendType" SG_ 303 DwnLoadDynLitPrmLedRePosnLampLe2OffsTiPrm 1;
BA_ "SigGroup" SG_ 303 DwnLoadDynLitPrmLedRePosnLampLe2OffsTiPrm "DwnLoadDynLitPrmLedRePosnLampLe2";
BA_ "GenSigSendType" SG_ 303 DwnLoadDynLitPrmLedRePosnLampLe2Tistamp 1;
BA_ "SigGroup" SG_ 303 DwnLoadDynLitPrmLedRePosnLampLe2Tistamp "DwnLoadDynLitPrmLedRePosnLampLe2";
BA_ "GenSigSendType" SG_ 303 DwnLoadDynLitPrmLedRePosnLampLe2UpprBriPrm 1;
BA_ "SigGroup" SG_ 303 DwnLoadDynLitPrmLedRePosnLampLe2UpprBriPrm "DwnLoadDynLitPrmLedRePosnLampLe2";
// Frame: CemBodyExpoFr18
BA_ "GenMsgSendType" BO_ 304 1;
BA_ "GenMsgDelayTime" BO_ 304 30.000;
BA_ "GenSigSendType" SG_ 304 DwnLoadDynLitPrmLedRePosnLampRi1ContTiPrm 1;
BA_ "SigGroup" SG_ 304 DwnLoadDynLitPrmLedRePosnLampRi1ContTiPrm "DwnLoadDynLitPrmLedRePosnLampRi1";
BA_ "GenSigSendType" SG_ 304 DwnLoadDynLitPrmLedRePosnLampRi1LowBriPrm 1;
BA_ "SigGroup" SG_ 304 DwnLoadDynLitPrmLedRePosnLampRi1LowBriPrm "DwnLoadDynLitPrmLedRePosnLampRi1";
BA_ "GenSigSendType" SG_ 304 DwnLoadDynLitPrmLedRePosnLampRi1ModePrm 1;
BA_ "SigGroup" SG_ 304 DwnLoadDynLitPrmLedRePosnLampRi1ModePrm "DwnLoadDynLitPrmLedRePosnLampRi1";
BA_ "GenSigSendType" SG_ 304 DwnLoadDynLitPrmLedRePosnLampRi1OffsTiPrm 1;
BA_ "SigGroup" SG_ 304 DwnLoadDynLitPrmLedRePosnLampRi1OffsTiPrm "DwnLoadDynLitPrmLedRePosnLampRi1";
BA_ "GenSigSendType" SG_ 304 DwnLoadDynLitPrmLedRePosnLampRi1Tistamp 1;
BA_ "SigGroup" SG_ 304 DwnLoadDynLitPrmLedRePosnLampRi1Tistamp "DwnLoadDynLitPrmLedRePosnLampRi1";
BA_ "GenSigSendType" SG_ 304 DwnLoadDynLitPrmLedRePosnLampRi1UpprBriPrm 1;
BA_ "SigGroup" SG_ 304 DwnLoadDynLitPrmLedRePosnLampRi1UpprBriPrm "DwnLoadDynLitPrmLedRePosnLampRi1";
// Frame: CemBodyExpoFr19
BA_ "GenMsgSendType" BO_ 305 1;
BA_ "GenMsgDelayTime" BO_ 305 30.000;
BA_ "GenSigSendType" SG_ 305 DwnLoadDynLitPrmLedReTurnIndcrLe1ContTiPrm 1;
BA_ "SigGroup" SG_ 305 DwnLoadDynLitPrmLedReTurnIndcrLe1ContTiPrm "DwnLoadDynLitPrmLedReTurnIndcrLe1";
BA_ "GenSigSendType" SG_ 305 DwnLoadDynLitPrmLedReTurnIndcrLe1LowBriPrm 1;
BA_ "SigGroup" SG_ 305 DwnLoadDynLitPrmLedReTurnIndcrLe1LowBriPrm "DwnLoadDynLitPrmLedReTurnIndcrLe1";
BA_ "GenSigSendType" SG_ 305 DwnLoadDynLitPrmLedReTurnIndcrLe1ModePrm 1;
BA_ "SigGroup" SG_ 305 DwnLoadDynLitPrmLedReTurnIndcrLe1ModePrm "DwnLoadDynLitPrmLedReTurnIndcrLe1";
BA_ "GenSigSendType" SG_ 305 DwnLoadDynLitPrmLedReTurnIndcrLe1OffsTiPrm 1;
BA_ "SigGroup" SG_ 305 DwnLoadDynLitPrmLedReTurnIndcrLe1OffsTiPrm "DwnLoadDynLitPrmLedReTurnIndcrLe1";
BA_ "GenSigSendType" SG_ 305 DwnLoadDynLitPrmLedReTurnIndcrLe1Tistamp 1;
BA_ "SigGroup" SG_ 305 DwnLoadDynLitPrmLedReTurnIndcrLe1Tistamp "DwnLoadDynLitPrmLedReTurnIndcrLe1";
BA_ "GenSigSendType" SG_ 305 DwnLoadDynLitPrmLedReTurnIndcrLe1UpprBriPrm 1;
BA_ "SigGroup" SG_ 305 DwnLoadDynLitPrmLedReTurnIndcrLe1UpprBriPrm "DwnLoadDynLitPrmLedReTurnIndcrLe1";
// Frame: CemBodyExpoFr20
BA_ "GenMsgSendType" BO_ 306 1;
BA_ "GenMsgDelayTime" BO_ 306 30.000;
BA_ "GenSigSendType" SG_ 306 DwnLoadDynLitPrmLedReTurnIndcrLe2ContTiPrm 1;
BA_ "SigGroup" SG_ 306 DwnLoadDynLitPrmLedReTurnIndcrLe2ContTiPrm "DwnLoadDynLitPrmLedReTurnIndcrLe2";
BA_ "GenSigSendType" SG_ 306 DwnLoadDynLitPrmLedReTurnIndcrLe2LowBriPrm 1;
BA_ "SigGroup" SG_ 306 DwnLoadDynLitPrmLedReTurnIndcrLe2LowBriPrm "DwnLoadDynLitPrmLedReTurnIndcrLe2";
BA_ "GenSigSendType" SG_ 306 DwnLoadDynLitPrmLedReTurnIndcrLe2ModePrm 1;
BA_ "SigGroup" SG_ 306 DwnLoadDynLitPrmLedReTurnIndcrLe2ModePrm "DwnLoadDynLitPrmLedReTurnIndcrLe2";
BA_ "GenSigSendType" SG_ 306 DwnLoadDynLitPrmLedReTurnIndcrLe2OffsTiPrm 1;
BA_ "SigGroup" SG_ 306 DwnLoadDynLitPrmLedReTurnIndcrLe2OffsTiPrm "DwnLoadDynLitPrmLedReTurnIndcrLe2";
BA_ "GenSigSendType" SG_ 306 DwnLoadDynLitPrmLedReTurnIndcrLe2Tistamp 1;
BA_ "SigGroup" SG_ 306 DwnLoadDynLitPrmLedReTurnIndcrLe2Tistamp "DwnLoadDynLitPrmLedReTurnIndcrLe2";
BA_ "GenSigSendType" SG_ 306 DwnLoadDynLitPrmLedReTurnIndcrLe2UpprBriPrm 1;
BA_ "SigGroup" SG_ 306 DwnLoadDynLitPrmLedReTurnIndcrLe2UpprBriPrm "DwnLoadDynLitPrmLedReTurnIndcrLe2";
// Frame: CemBodyExpoFr21
BA_ "GenMsgSendType" BO_ 307 1;
BA_ "GenMsgDelayTime" BO_ 307 30.000;
BA_ "GenSigSendType" SG_ 307 DwnLoadDynLitPrmLedReTurnIndcrRi1ContTiPrm 1;
BA_ "SigGroup" SG_ 307 DwnLoadDynLitPrmLedReTurnIndcrRi1ContTiPrm "DwnLoadDynLitPrmLedReTurnIndcrRi1";
BA_ "GenSigSendType" SG_ 307 DwnLoadDynLitPrmLedReTurnIndcrRi1LowBriPrm 1;
BA_ "SigGroup" SG_ 307 DwnLoadDynLitPrmLedReTurnIndcrRi1LowBriPrm "DwnLoadDynLitPrmLedReTurnIndcrRi1";
BA_ "GenSigSendType" SG_ 307 DwnLoadDynLitPrmLedReTurnIndcrRi1ModePrm 1;
BA_ "SigGroup" SG_ 307 DwnLoadDynLitPrmLedReTurnIndcrRi1ModePrm "DwnLoadDynLitPrmLedReTurnIndcrRi1";
BA_ "GenSigSendType" SG_ 307 DwnLoadDynLitPrmLedReTurnIndcrRi1OffsTiPrm 1;
BA_ "SigGroup" SG_ 307 DwnLoadDynLitPrmLedReTurnIndcrRi1OffsTiPrm "DwnLoadDynLitPrmLedReTurnIndcrRi1";
BA_ "GenSigSendType" SG_ 307 DwnLoadDynLitPrmLedReTurnIndcrRi1Tistamp 1;
BA_ "SigGroup" SG_ 307 DwnLoadDynLitPrmLedReTurnIndcrRi1Tistamp "DwnLoadDynLitPrmLedReTurnIndcrRi1";
BA_ "GenSigSendType" SG_ 307 DwnLoadDynLitPrmLedReTurnIndcrRi1UpprBriPrm 1;
BA_ "SigGroup" SG_ 307 DwnLoadDynLitPrmLedReTurnIndcrRi1UpprBriPrm "DwnLoadDynLitPrmLedReTurnIndcrRi1";
// Frame: CemBodyExpoFr22
BA_ "GenMsgSendType" BO_ 308 1;
BA_ "GenMsgDelayTime" BO_ 308 30.000;
BA_ "GenSigSendType" SG_ 308 DwnLoadDynLitPrmLedRvsgLampLe1ContTiPrm 1;
BA_ "GenSigSendType" SG_ 308 DwnLoadDynLitPrmLedRvsgLampLe1LowBriPrm 1;
BA_ "GenSigSendType" SG_ 308 DwnLoadDynLitPrmLedRvsgLampLe1ModePrm 1;
BA_ "GenSigSendType" SG_ 308 DwnLoadDynLitPrmLedRvsgLampLe1OffsTiPrm 1;
BA_ "GenSigSendType" SG_ 308 DwnLoadDynLitPrmLedRvsgLampLe1Tistamp 1;
BA_ "GenSigSendType" SG_ 308 DwnLoadDynLitPrmLedRvsgLampLe1UpprBriPrm 1;
// Frame: CemBodyExpoFr23
BA_ "GenMsgSendType" BO_ 309 1;
BA_ "GenMsgDelayTime" BO_ 309 30.000;
BA_ "GenSigSendType" SG_ 309 DwnLoadDynLitPrmLedRvsgLampLe2ContTiPrm 1;
BA_ "GenSigSendType" SG_ 309 DwnLoadDynLitPrmLedRvsgLampLe2LowBriPrm 1;
BA_ "GenSigSendType" SG_ 309 DwnLoadDynLitPrmLedRvsgLampLe2ModePrm 1;
BA_ "GenSigSendType" SG_ 309 DwnLoadDynLitPrmLedRvsgLampLe2OffsTiPrm 1;
BA_ "GenSigSendType" SG_ 309 DwnLoadDynLitPrmLedRvsgLampLe2Tistamp 1;
BA_ "GenSigSendType" SG_ 309 DwnLoadDynLitPrmLedRvsgLampLe2UpprBriPrm 1;
// Frame: CemBodyExpoFr24
BA_ "GenMsgSendType" BO_ 310 1;
BA_ "GenMsgDelayTime" BO_ 310 30.000;
BA_ "GenSigSendType" SG_ 310 DwnLoadDynLitPrmLedRvsgLampRi1ContTiPrm 1;
BA_ "GenSigSendType" SG_ 310 DwnLoadDynLitPrmLedRvsgLampRi1LowBriPrm 1;
BA_ "GenSigSendType" SG_ 310 DwnLoadDynLitPrmLedRvsgLampRi1ModePrm 1;
BA_ "GenSigSendType" SG_ 310 DwnLoadDynLitPrmLedRvsgLampRi1OffsTiPrm 1;
BA_ "GenSigSendType" SG_ 310 DwnLoadDynLitPrmLedRvsgLampRi1Tistamp 1;
BA_ "GenSigSendType" SG_ 310 DwnLoadDynLitPrmLedRvsgLampRi1UpprBriPrm 1;
// Frame: CemBodyExpoFr25
BA_ "GenMsgSendType" BO_ 120 0;
BA_ "GenMsgCycleTime" BO_ 120 25.000;
BA_ "GenSigSendType" SG_ 120 CarpetLiModReq 0;
BA_ "GenSigSendType" SG_ 120 CarpetLiSwtReq 0;
BA_ "GenSigSendType" SG_ 120 CarpetLiTiReq 0;
BA_ "GenSigStartValue" SG_ 120 DoorLeRePercSetFromHmi 100;
BA_ "GenSigSendType" SG_ 120 DoorLeRePercSetFromHmi 0;
BA_ "GenSigStartValue" SG_ 120 DrvrPwrDoorManStrengthLvl 2;
BA_ "GenSigSendType" SG_ 120 DrvrPwrDoorManStrengthLvl 0;
BA_ "GenSigSendType" SG_ 120 HvacRecircAct 0;
BA_ "GenSigSendType" SG_ 120 LvlgSwtSetReqADModCtrlInhbn 0;
BA_ "GenSigSendType" SG_ 120 LvlgSwtSetReqChks 0;
BA_ "GenSigSendType" SG_ 120 LvlgSwtSetReqCntr 0;
BA_ "GenSigSendType" SG_ 120 OutdBriChks 0;
BA_ "GenSigFuncType" SG_ 120 OutdBriChks 15;
BA_ "GenSigDataID" SG_ 120 OutdBriChks "0x1F42";
BA_ "GenSigSendType" SG_ 120 OutdBriCntr 0;
BA_ "GenSigFuncType" SG_ 120 OutdBriCntr 16;
BA_ "GenSigSendType" SG_ 120 OutdBriSts 0;
// Frame: CemBodyExpoFr26
BA_ "GenMsgSendType" BO_ 311 1;
BA_ "GenMsgDelayTime" BO_ 311 30.000;
BA_ "GenSigSendType" SG_ 311 DwnLoadDynLitPrmForLedHiBeamLeContTiPrm 1;
BA_ "GenSigSendType" SG_ 311 DwnLoadDynLitPrmForLedHiBeamLeLowBriPrm 1;
BA_ "GenSigSendType" SG_ 311 DwnLoadDynLitPrmForLedHiBeamLeModePrm 1;
BA_ "GenSigSendType" SG_ 311 DwnLoadDynLitPrmForLedHiBeamLeOffsTiPrm 1;
BA_ "GenSigSendType" SG_ 311 DwnLoadDynLitPrmForLedHiBeamLeTistamp 1;
BA_ "GenSigSendType" SG_ 311 DwnLoadDynLitPrmForLedHiBeamLeUpprBriPrm 1;
// Frame: CemBodyExpoFr27
BA_ "GenMsgSendType" BO_ 312 1;
BA_ "GenMsgDelayTime" BO_ 312 30.000;
BA_ "GenSigSendType" SG_ 312 DwnLoadDynLitPrmForLedLoBeamLeContTiPrm 1;
BA_ "GenSigSendType" SG_ 312 DwnLoadDynLitPrmForLedLoBeamLeLowBriPrm 1;
BA_ "GenSigSendType" SG_ 312 DwnLoadDynLitPrmForLedLoBeamLeModePrm 1;
BA_ "GenSigSendType" SG_ 312 DwnLoadDynLitPrmForLedLoBeamLeOffsTiPrm 1;
BA_ "GenSigSendType" SG_ 312 DwnLoadDynLitPrmForLedLoBeamLeTistamp 1;
BA_ "GenSigSendType" SG_ 312 DwnLoadDynLitPrmForLedLoBeamLeUpprBriPrm 1;
// Frame: CemBodyExpoFr28
BA_ "GenMsgSendType" BO_ 313 1;
BA_ "GenMsgDelayTime" BO_ 313 30.000;
BA_ "GenSigSendType" SG_ 313 DwnLoadDynLtgPrmForLedAllWthrLampLeContTiPrm 1;
BA_ "SigGroup" SG_ 313 DwnLoadDynLtgPrmForLedAllWthrLampLeContTiPrm "DwnLoadDynLtgPrmForLedAllWthrLampLe";
BA_ "GenSigSendType" SG_ 313 DwnLoadDynLtgPrmForLedAllWthrLampLeLowBriPrm 1;
BA_ "SigGroup" SG_ 313 DwnLoadDynLtgPrmForLedAllWthrLampLeLowBriPrm "DwnLoadDynLtgPrmForLedAllWthrLampLe";
BA_ "GenSigSendType" SG_ 313 DwnLoadDynLtgPrmForLedAllWthrLampLeModePrm 1;
BA_ "SigGroup" SG_ 313 DwnLoadDynLtgPrmForLedAllWthrLampLeModePrm "DwnLoadDynLtgPrmForLedAllWthrLampLe";
BA_ "GenSigSendType" SG_ 313 DwnLoadDynLtgPrmForLedAllWthrLampLeOffsTiPrm 1;
BA_ "SigGroup" SG_ 313 DwnLoadDynLtgPrmForLedAllWthrLampLeOffsTiPrm "DwnLoadDynLtgPrmForLedAllWthrLampLe";
BA_ "GenSigSendType" SG_ 313 DwnLoadDynLtgPrmForLedAllWthrLampLeTistamp 1;
BA_ "SigGroup" SG_ 313 DwnLoadDynLtgPrmForLedAllWthrLampLeTistamp "DwnLoadDynLtgPrmForLedAllWthrLampLe";
BA_ "GenSigSendType" SG_ 313 DwnLoadDynLtgPrmForLedAllWthrLampLeUpprBriPrm 1;
BA_ "SigGroup" SG_ 313 DwnLoadDynLtgPrmForLedAllWthrLampLeUpprBriPrm "DwnLoadDynLtgPrmForLedAllWthrLampLe";
// Frame: CemBodyExpoFr29
BA_ "GenMsgSendType" BO_ 314 1;
BA_ "GenMsgDelayTime" BO_ 314 30.000;
BA_ "GenSigSendType" SG_ 314 DwnLoadDynLtgPrmForLedAllWthrLampRiContTiPrm 1;
BA_ "SigGroup" SG_ 314 DwnLoadDynLtgPrmForLedAllWthrLampRiContTiPrm "DwnLoadDynLtgPrmForLedAllWthrLampRi";
BA_ "GenSigSendType" SG_ 314 DwnLoadDynLtgPrmForLedAllWthrLampRiLowBriPrm 1;
BA_ "SigGroup" SG_ 314 DwnLoadDynLtgPrmForLedAllWthrLampRiLowBriPrm "DwnLoadDynLtgPrmForLedAllWthrLampRi";
BA_ "GenSigSendType" SG_ 314 DwnLoadDynLtgPrmForLedAllWthrLampRiModePrm 1;
BA_ "SigGroup" SG_ 314 DwnLoadDynLtgPrmForLedAllWthrLampRiModePrm "DwnLoadDynLtgPrmForLedAllWthrLampRi";
BA_ "GenSigSendType" SG_ 314 DwnLoadDynLtgPrmForLedAllWthrLampRiOffsTiPrm 1;
BA_ "SigGroup" SG_ 314 DwnLoadDynLtgPrmForLedAllWthrLampRiOffsTiPrm "DwnLoadDynLtgPrmForLedAllWthrLampRi";
BA_ "GenSigSendType" SG_ 314 DwnLoadDynLtgPrmForLedAllWthrLampRiTistamp 1;
BA_ "SigGroup" SG_ 314 DwnLoadDynLtgPrmForLedAllWthrLampRiTistamp "DwnLoadDynLtgPrmForLedAllWthrLampRi";
BA_ "GenSigSendType" SG_ 314 DwnLoadDynLtgPrmForLedAllWthrLampRiUpprBriPrm 1;
BA_ "SigGroup" SG_ 314 DwnLoadDynLtgPrmForLedAllWthrLampRiUpprBriPrm "DwnLoadDynLtgPrmForLedAllWthrLampRi";
// Frame: CemBodyExpoFr30
BA_ "GenMsgSendType" BO_ 315 1;
BA_ "GenMsgDelayTime" BO_ 315 30.000;
BA_ "GenSigSendType" SG_ 315 DwnLoadDynLtgPrmForLedCornrgLampLeContTiPrm 1;
BA_ "SigGroup" SG_ 315 DwnLoadDynLtgPrmForLedCornrgLampLeContTiPrm "DwnLoadDynLtgPrmForLedCornrgLampLe";
BA_ "GenSigSendType" SG_ 315 DwnLoadDynLtgPrmForLedCornrgLampLeLowBriPrm 1;
BA_ "SigGroup" SG_ 315 DwnLoadDynLtgPrmForLedCornrgLampLeLowBriPrm "DwnLoadDynLtgPrmForLedCornrgLampLe";
BA_ "GenSigSendType" SG_ 315 DwnLoadDynLtgPrmForLedCornrgLampLeModePrm 1;
BA_ "SigGroup" SG_ 315 DwnLoadDynLtgPrmForLedCornrgLampLeModePrm "DwnLoadDynLtgPrmForLedCornrgLampLe";
BA_ "GenSigSendType" SG_ 315 DwnLoadDynLtgPrmForLedCornrgLampLeOffsTiPrm 1;
BA_ "SigGroup" SG_ 315 DwnLoadDynLtgPrmForLedCornrgLampLeOffsTiPrm "DwnLoadDynLtgPrmForLedCornrgLampLe";
BA_ "GenSigSendType" SG_ 315 DwnLoadDynLtgPrmForLedCornrgLampLeTistamp 1;
BA_ "SigGroup" SG_ 315 DwnLoadDynLtgPrmForLedCornrgLampLeTistamp "DwnLoadDynLtgPrmForLedCornrgLampLe";
BA_ "GenSigSendType" SG_ 315 DwnLoadDynLtgPrmForLedCornrgLampLeUpprBriPrm 1;
BA_ "SigGroup" SG_ 315 DwnLoadDynLtgPrmForLedCornrgLampLeUpprBriPrm "DwnLoadDynLtgPrmForLedCornrgLampLe";
// Frame: CemBodyExpoFr31
BA_ "GenMsgSendType" BO_ 316 1;
BA_ "GenMsgDelayTime" BO_ 316 30.000;
BA_ "GenSigSendType" SG_ 316 DwnLoadDynLtgPrmForLedCornrgLampRiContTiPrm 1;
BA_ "SigGroup" SG_ 316 DwnLoadDynLtgPrmForLedCornrgLampRiContTiPrm "DwnLoadDynLtgPrmForLedCornrgLampRi";
BA_ "GenSigSendType" SG_ 316 DwnLoadDynLtgPrmForLedCornrgLampRiLowBriPrm 1;
BA_ "SigGroup" SG_ 316 DwnLoadDynLtgPrmForLedCornrgLampRiLowBriPrm "DwnLoadDynLtgPrmForLedCornrgLampRi";
BA_ "GenSigSendType" SG_ 316 DwnLoadDynLtgPrmForLedCornrgLampRiModePrm 1;
BA_ "SigGroup" SG_ 316 DwnLoadDynLtgPrmForLedCornrgLampRiModePrm "DwnLoadDynLtgPrmForLedCornrgLampRi";
BA_ "GenSigSendType" SG_ 316 DwnLoadDynLtgPrmForLedCornrgLampRiOffsTiPrm 1;
BA_ "SigGroup" SG_ 316 DwnLoadDynLtgPrmForLedCornrgLampRiOffsTiPrm "DwnLoadDynLtgPrmForLedCornrgLampRi";
BA_ "GenSigSendType" SG_ 316 DwnLoadDynLtgPrmForLedCornrgLampRiTistamp 1;
BA_ "SigGroup" SG_ 316 DwnLoadDynLtgPrmForLedCornrgLampRiTistamp "DwnLoadDynLtgPrmForLedCornrgLampRi";
BA_ "GenSigSendType" SG_ 316 DwnLoadDynLtgPrmForLedCornrgLampRiUpprBriPrm 1;
BA_ "SigGroup" SG_ 316 DwnLoadDynLtgPrmForLedCornrgLampRiUpprBriPrm "DwnLoadDynLtgPrmForLedCornrgLampRi";
// Frame: CemBodyExpoFr32
BA_ "GenMsgSendType" BO_ 317 1;
BA_ "GenMsgDelayTime" BO_ 317 30.000;
BA_ "GenSigSendType" SG_ 317 DwnLoadDynLtgPrmForLedDaytiRunngLampLeContTiPrm 1;
BA_ "SigGroup" SG_ 317 DwnLoadDynLtgPrmForLedDaytiRunngLampLeContTiPrm "DwnLoadDynLtgPrmForLedDaytiRunngLampLe";
BA_ "GenSigSendType" SG_ 317 DwnLoadDynLtgPrmForLedDaytiRunngLampLeLowBriPrm 1;
BA_ "SigGroup" SG_ 317 DwnLoadDynLtgPrmForLedDaytiRunngLampLeLowBriPrm "DwnLoadDynLtgPrmForLedDaytiRunngLampLe";
BA_ "GenSigSendType" SG_ 317 DwnLoadDynLtgPrmForLedDaytiRunngLampLeModePrm 1;
BA_ "SigGroup" SG_ 317 DwnLoadDynLtgPrmForLedDaytiRunngLampLeModePrm "DwnLoadDynLtgPrmForLedDaytiRunngLampLe";
BA_ "GenSigSendType" SG_ 317 DwnLoadDynLtgPrmForLedDaytiRunngLampLeOffsTiPrm 1;
BA_ "SigGroup" SG_ 317 DwnLoadDynLtgPrmForLedDaytiRunngLampLeOffsTiPrm "DwnLoadDynLtgPrmForLedDaytiRunngLampLe";
BA_ "GenSigSendType" SG_ 317 DwnLoadDynLtgPrmForLedDaytiRunngLampLeTistamp 1;
BA_ "SigGroup" SG_ 317 DwnLoadDynLtgPrmForLedDaytiRunngLampLeTistamp "DwnLoadDynLtgPrmForLedDaytiRunngLampLe";
BA_ "GenSigSendType" SG_ 317 DwnLoadDynLtgPrmForLedDaytiRunngLampLeUpprBriPrm 1;
BA_ "SigGroup" SG_ 317 DwnLoadDynLtgPrmForLedDaytiRunngLampLeUpprBriPrm "DwnLoadDynLtgPrmForLedDaytiRunngLampLe";
// Frame: CemBodyExpoFr33
BA_ "GenMsgSendType" BO_ 318 1;
BA_ "GenMsgDelayTime" BO_ 318 30.000;
BA_ "GenSigSendType" SG_ 318 DwnLoadDynLtgPrmForLedDaytiRunngLampRiContTiPrm 1;
BA_ "SigGroup" SG_ 318 DwnLoadDynLtgPrmForLedDaytiRunngLampRiContTiPrm "DwnLoadDynLtgPrmForLedDaytiRunngLampRi";
BA_ "GenSigSendType" SG_ 318 DwnLoadDynLtgPrmForLedDaytiRunngLampRiLowBriPrm 1;
BA_ "SigGroup" SG_ 318 DwnLoadDynLtgPrmForLedDaytiRunngLampRiLowBriPrm "DwnLoadDynLtgPrmForLedDaytiRunngLampRi";
BA_ "GenSigSendType" SG_ 318 DwnLoadDynLtgPrmForLedDaytiRunngLampRiModePrm 1;
BA_ "SigGroup" SG_ 318 DwnLoadDynLtgPrmForLedDaytiRunngLampRiModePrm "DwnLoadDynLtgPrmForLedDaytiRunngLampRi";
BA_ "GenSigSendType" SG_ 318 DwnLoadDynLtgPrmForLedDaytiRunngLampRiOffsTiPrm 1;
BA_ "SigGroup" SG_ 318 DwnLoadDynLtgPrmForLedDaytiRunngLampRiOffsTiPrm "DwnLoadDynLtgPrmForLedDaytiRunngLampRi";
BA_ "GenSigSendType" SG_ 318 DwnLoadDynLtgPrmForLedDaytiRunngLampRiTistamp 1;
BA_ "SigGroup" SG_ 318 DwnLoadDynLtgPrmForLedDaytiRunngLampRiTistamp "DwnLoadDynLtgPrmForLedDaytiRunngLampRi";
BA_ "GenSigSendType" SG_ 318 DwnLoadDynLtgPrmForLedDaytiRunngLampRiUpprBriPrm 1;
BA_ "SigGroup" SG_ 318 DwnLoadDynLtgPrmForLedDaytiRunngLampRiUpprBriPrm "DwnLoadDynLtgPrmForLedDaytiRunngLampRi";
// Frame: CemBodyExpoFr34
BA_ "GenMsgSendType" BO_ 319 1;
BA_ "GenMsgDelayTime" BO_ 319 30.000;
BA_ "GenSigSendType" SG_ 319 DwnLoadDynLtgPrmForLedFrntPosnLampLeContTiPrm 1;
BA_ "SigGroup" SG_ 319 DwnLoadDynLtgPrmForLedFrntPosnLampLeContTiPrm "DwnLoadDynLtgPrmForLedFrntPosnLampLe";
BA_ "GenSigSendType" SG_ 319 DwnLoadDynLtgPrmForLedFrntPosnLampLeLowBriPrm 1;
BA_ "SigGroup" SG_ 319 DwnLoadDynLtgPrmForLedFrntPosnLampLeLowBriPrm "DwnLoadDynLtgPrmForLedFrntPosnLampLe";
BA_ "GenSigSendType" SG_ 319 DwnLoadDynLtgPrmForLedFrntPosnLampLeModePrm 1;
BA_ "SigGroup" SG_ 319 DwnLoadDynLtgPrmForLedFrntPosnLampLeModePrm "DwnLoadDynLtgPrmForLedFrntPosnLampLe";
BA_ "GenSigSendType" SG_ 319 DwnLoadDynLtgPrmForLedFrntPosnLampLeOffsTiPrm 1;
BA_ "SigGroup" SG_ 319 DwnLoadDynLtgPrmForLedFrntPosnLampLeOffsTiPrm "DwnLoadDynLtgPrmForLedFrntPosnLampLe";
BA_ "GenSigSendType" SG_ 319 DwnLoadDynLtgPrmForLedFrntPosnLampLeTistamp 1;
BA_ "SigGroup" SG_ 319 DwnLoadDynLtgPrmForLedFrntPosnLampLeTistamp "DwnLoadDynLtgPrmForLedFrntPosnLampLe";
BA_ "GenSigSendType" SG_ 319 DwnLoadDynLtgPrmForLedFrntPosnLampLeUpprBriPrm 1;
BA_ "SigGroup" SG_ 319 DwnLoadDynLtgPrmForLedFrntPosnLampLeUpprBriPrm "DwnLoadDynLtgPrmForLedFrntPosnLampLe";
// Frame: CemBodyExpoFr35
BA_ "GenMsgSendType" BO_ 320 1;
BA_ "GenMsgDelayTime" BO_ 320 30.000;
BA_ "GenSigSendType" SG_ 320 DwnLoadDynLtgPrmForLedFrntPosnLampRiContTiPrm 1;
BA_ "SigGroup" SG_ 320 DwnLoadDynLtgPrmForLedFrntPosnLampRiContTiPrm "DwnLoadDynLtgPrmForLedFrntPosnLampRi";
BA_ "GenSigSendType" SG_ 320 DwnLoadDynLtgPrmForLedFrntPosnLampRiLowBriPrm 1;
BA_ "SigGroup" SG_ 320 DwnLoadDynLtgPrmForLedFrntPosnLampRiLowBriPrm "DwnLoadDynLtgPrmForLedFrntPosnLampRi";
BA_ "GenSigSendType" SG_ 320 DwnLoadDynLtgPrmForLedFrntPosnLampRiModePrm 1;
BA_ "SigGroup" SG_ 320 DwnLoadDynLtgPrmForLedFrntPosnLampRiModePrm "DwnLoadDynLtgPrmForLedFrntPosnLampRi";
BA_ "GenSigSendType" SG_ 320 DwnLoadDynLtgPrmForLedFrntPosnLampRiOffsTiPrm 1;
BA_ "SigGroup" SG_ 320 DwnLoadDynLtgPrmForLedFrntPosnLampRiOffsTiPrm "DwnLoadDynLtgPrmForLedFrntPosnLampRi";
BA_ "GenSigSendType" SG_ 320 DwnLoadDynLtgPrmForLedFrntPosnLampRiTistamp 1;
BA_ "SigGroup" SG_ 320 DwnLoadDynLtgPrmForLedFrntPosnLampRiTistamp "DwnLoadDynLtgPrmForLedFrntPosnLampRi";
BA_ "GenSigSendType" SG_ 320 DwnLoadDynLtgPrmForLedFrntPosnLampRiUpprBriPrm 1;
BA_ "SigGroup" SG_ 320 DwnLoadDynLtgPrmForLedFrntPosnLampRiUpprBriPrm "DwnLoadDynLtgPrmForLedFrntPosnLampRi";
// Frame: CemBodyExpoFr36
BA_ "GenMsgSendType" BO_ 321 1;
BA_ "GenMsgDelayTime" BO_ 321 30.000;
BA_ "GenSigSendType" SG_ 321 DwnLoadDynLtgPrmForLedFrntTurnIndcrLeContTiPrm 1;
BA_ "SigGroup" SG_ 321 DwnLoadDynLtgPrmForLedFrntTurnIndcrLeContTiPrm "DwnLoadDynLtgPrmForLedFrntTurnIndcrLe";
BA_ "GenSigSendType" SG_ 321 DwnLoadDynLtgPrmForLedFrntTurnIndcrLeLowBriPrm 1;
BA_ "SigGroup" SG_ 321 DwnLoadDynLtgPrmForLedFrntTurnIndcrLeLowBriPrm "DwnLoadDynLtgPrmForLedFrntTurnIndcrLe";
BA_ "GenSigSendType" SG_ 321 DwnLoadDynLtgPrmForLedFrntTurnIndcrLeModePrm 1;
BA_ "SigGroup" SG_ 321 DwnLoadDynLtgPrmForLedFrntTurnIndcrLeModePrm "DwnLoadDynLtgPrmForLedFrntTurnIndcrLe";
BA_ "GenSigSendType" SG_ 321 DwnLoadDynLtgPrmForLedFrntTurnIndcrLeOffsTiPrm 1;
BA_ "SigGroup" SG_ 321 DwnLoadDynLtgPrmForLedFrntTurnIndcrLeOffsTiPrm "DwnLoadDynLtgPrmForLedFrntTurnIndcrLe";
BA_ "GenSigSendType" SG_ 321 DwnLoadDynLtgPrmForLedFrntTurnIndcrLeTistamp 1;
BA_ "SigGroup" SG_ 321 DwnLoadDynLtgPrmForLedFrntTurnIndcrLeTistamp "DwnLoadDynLtgPrmForLedFrntTurnIndcrLe";
BA_ "GenSigSendType" SG_ 321 DwnLoadDynLtgPrmForLedFrntTurnIndcrLeUpprBriPrm 1;
BA_ "SigGroup" SG_ 321 DwnLoadDynLtgPrmForLedFrntTurnIndcrLeUpprBriPrm "DwnLoadDynLtgPrmForLedFrntTurnIndcrLe";
// Frame: CemBodyExpoFr37
BA_ "GenMsgSendType" BO_ 322 1;
BA_ "GenMsgDelayTime" BO_ 322 30.000;
BA_ "GenSigSendType" SG_ 322 DwnLoadDynLtgPrmForLedFrntTurnIndcrRiContTiPrm 1;
BA_ "SigGroup" SG_ 322 DwnLoadDynLtgPrmForLedFrntTurnIndcrRiContTiPrm "DwnLoadDynLtgPrmForLedFrntTurnIndcrRi";
BA_ "GenSigSendType" SG_ 322 DwnLoadDynLtgPrmForLedFrntTurnIndcrRiLowBriPrm 1;
BA_ "SigGroup" SG_ 322 DwnLoadDynLtgPrmForLedFrntTurnIndcrRiLowBriPrm "DwnLoadDynLtgPrmForLedFrntTurnIndcrRi";
BA_ "GenSigSendType" SG_ 322 DwnLoadDynLtgPrmForLedFrntTurnIndcrRiModePrm 1;
BA_ "SigGroup" SG_ 322 DwnLoadDynLtgPrmForLedFrntTurnIndcrRiModePrm "DwnLoadDynLtgPrmForLedFrntTurnIndcrRi";
BA_ "GenSigSendType" SG_ 322 DwnLoadDynLtgPrmForLedFrntTurnIndcrRiOffsTiPrm 1;
BA_ "SigGroup" SG_ 322 DwnLoadDynLtgPrmForLedFrntTurnIndcrRiOffsTiPrm "DwnLoadDynLtgPrmForLedFrntTurnIndcrRi";
BA_ "GenSigSendType" SG_ 322 DwnLoadDynLtgPrmForLedFrntTurnIndcrRiTistamp 1;
BA_ "SigGroup" SG_ 322 DwnLoadDynLtgPrmForLedFrntTurnIndcrRiTistamp "DwnLoadDynLtgPrmForLedFrntTurnIndcrRi";
BA_ "GenSigSendType" SG_ 322 DwnLoadDynLtgPrmForLedFrntTurnIndcrRiUpprBriPrm 1;
BA_ "SigGroup" SG_ 322 DwnLoadDynLtgPrmForLedFrntTurnIndcrRiUpprBriPrm "DwnLoadDynLtgPrmForLedFrntTurnIndcrRi";
// Frame: CemBodyExpoFr38
BA_ "GenMsgSendType" BO_ 323 1;
BA_ "GenMsgDelayTime" BO_ 323 30.000;
BA_ "GenSigSendType" SG_ 323 DwnLoadDynLtgPrmForLedHiBeamRiContTiPrm 1;
BA_ "GenSigSendType" SG_ 323 DwnLoadDynLtgPrmForLedHiBeamRiLowBriPrm 1;
BA_ "GenSigSendType" SG_ 323 DwnLoadDynLtgPrmForLedHiBeamRiModePrm 1;
BA_ "GenSigSendType" SG_ 323 DwnLoadDynLtgPrmForLedHiBeamRiOffsTiPrm 1;
BA_ "GenSigSendType" SG_ 323 DwnLoadDynLtgPrmForLedHiBeamRiTistamp 1;
BA_ "GenSigSendType" SG_ 323 DwnLoadDynLtgPrmForLedHiBeamRiUpprBriPrm 1;
// Frame: CemBodyExpoFr42
BA_ "GenMsgSendType" BO_ 381 0;
BA_ "GenMsgCycleTime" BO_ 381 80.000;
BA_ "GenSigSendType" SG_ 381 ActnOfLedFrntCrossLampDyn 0;
BA_ "GenSigSendType" SG_ 381 ActnOfLedGrilleLampDyn 0;
BA_ "GenSigSendType" SG_ 381 ActnOfLedLeLogoLampDyn 0;
BA_ "GenSigSendType" SG_ 381 ActnOfLedPosnLampDyn 0;
BA_ "GenSigSendType" SG_ 381 ActnOfLedRiLogoLampDyn 0;
BA_ "GenSigSendType" SG_ 381 ActvnOfHomeSafe 0;
// Frame: CemBodyExpoFr45
BA_ "GenMsgSendType" BO_ 612 0;
BA_ "GenMsgCycleTime" BO_ 612 65.000;
BA_ "GenSigSendType" SG_ 612 ActvnOfApproach 0;
BA_ "GenSigSendType" SG_ 612 ActvnOfCarLoctr 0;
BA_ "GenSigSendType" SG_ 612 ActvnOfReLogoLamp 0;
BA_ "GenSigSendType" SG_ 612 ActvnOfSayHi 0;
BA_ "GenSigSendType" SG_ 612 ActvnOfWaitMode 0;
BA_ "GenSigSendType" SG_ 612 BrkPedlValBrkPedlVal 0;
BA_ "GenSigStartValue" SG_ 612 BrkPedlValQf 1;
BA_ "GenSigSendType" SG_ 612 BrkPedlValQf 0;
BA_ "GenSigSendType" SG_ 612 CinhDrvrSts 0;
BA_ "GenSigSendType" SG_ 612 CinhDrvrSwt 0;
BA_ "GenSigSendType" SG_ 612 CinhLeReSts 0;
BA_ "GenSigSendType" SG_ 612 CinhLeReSwt 0;
BA_ "GenSigSendType" SG_ 612 CinhPassSts 0;
BA_ "GenSigSendType" SG_ 612 CinhPassSwt 0;
BA_ "GenSigSendType" SG_ 612 CinhRiReSts 0;
BA_ "GenSigSendType" SG_ 612 CinhRiReSwt 0;
BA_ "GenSigSendType" SG_ 612 HmiHvacFanLvlFrnt 0;
BA_ "GenSigSendType" SG_ 612 IndcrNoSeq 0;
BA_ "GenSigSendType" SG_ 612 LitArea 0;
BA_ "GenSigStartValue" SG_ 612 ReLePwrDoorManStrengthLvl 2;
BA_ "GenSigSendType" SG_ 612 ReLePwrDoorManStrengthLvl 0;
BA_ "GenSigSendType" SG_ 612 WipgInfoWipgSpdInfo 0;
BA_ "GenSigSendType" SG_ 612 WipgInfoWiprActv 0;
BA_ "GenSigSendType" SG_ 612 WipgInfoWiprInWipgAr 0;
// Frame: CemBodyExpoFr48
BA_ "GenMsgSendType" BO_ 324 1;
BA_ "GenMsgDelayTime" BO_ 324 30.000;
BA_ "GenSigSendType" SG_ 324 DwnLoadDynLitPrmForLedMkrLampRi2ContTiPrm 1;
BA_ "SigGroup" SG_ 324 DwnLoadDynLitPrmForLedMkrLampRi2ContTiPrm "DwnLoadDynLitPrmForLedMkrLampRi2";
BA_ "GenSigSendType" SG_ 324 DwnLoadDynLitPrmForLedMkrLampRi2LowBriPrm 1;
BA_ "SigGroup" SG_ 324 DwnLoadDynLitPrmForLedMkrLampRi2LowBriPrm "DwnLoadDynLitPrmForLedMkrLampRi2";
BA_ "GenSigSendType" SG_ 324 DwnLoadDynLitPrmForLedMkrLampRi2ModePrm 1;
BA_ "SigGroup" SG_ 324 DwnLoadDynLitPrmForLedMkrLampRi2ModePrm "DwnLoadDynLitPrmForLedMkrLampRi2";
BA_ "GenSigSendType" SG_ 324 DwnLoadDynLitPrmForLedMkrLampRi2OffsTiPrm 1;
BA_ "SigGroup" SG_ 324 DwnLoadDynLitPrmForLedMkrLampRi2OffsTiPrm "DwnLoadDynLitPrmForLedMkrLampRi2";
BA_ "GenSigSendType" SG_ 324 DwnLoadDynLitPrmForLedMkrLampRi2Tistamp 1;
BA_ "SigGroup" SG_ 324 DwnLoadDynLitPrmForLedMkrLampRi2Tistamp "DwnLoadDynLitPrmForLedMkrLampRi2";
BA_ "GenSigSendType" SG_ 324 DwnLoadDynLitPrmForLedMkrLampRi2UpprBriPrm 1;
BA_ "SigGroup" SG_ 324 DwnLoadDynLitPrmForLedMkrLampRi2UpprBriPrm "DwnLoadDynLitPrmForLedMkrLampRi2";
// Frame: CemBodyExpoFr49
BA_ "GenMsgSendType" BO_ 325 1;
BA_ "GenMsgDelayTime" BO_ 325 30.000;
BA_ "GenSigSendType" SG_ 325 DwnLoadDynLitPrmLedRvsgLampRi2ContTiPrm 1;
BA_ "GenSigSendType" SG_ 325 DwnLoadDynLitPrmLedRvsgLampRi2LowBriPrm 1;
BA_ "GenSigSendType" SG_ 325 DwnLoadDynLitPrmLedRvsgLampRi2ModePrm 1;
BA_ "GenSigSendType" SG_ 325 DwnLoadDynLitPrmLedRvsgLampRi2OffsTiPrm 1;
BA_ "GenSigSendType" SG_ 325 DwnLoadDynLitPrmLedRvsgLampRi2Tistamp 1;
BA_ "GenSigSendType" SG_ 325 DwnLoadDynLitPrmLedRvsgLampRi2UpprBriPrm 1;
// Frame: CemBodyExpoFr50
BA_ "GenMsgSendType" BO_ 522 0;
BA_ "GenMsgCycleTime" BO_ 522 50.000;
BA_ "GenSigSendType" SG_ 522 ActnOfLedCornrgLampLe 0;
BA_ "GenSigSendType" SG_ 522 ActnOfLedCornrgLampRi 0;
BA_ "GenSigSendType" SG_ 522 ActnOfLedDaytiRunngLamp 0;
BA_ "GenSigSendType" SG_ 522 ActnOfLedFrntFogLamp 0;
BA_ "GenSigSendType" SG_ 522 ActnOfLedHiBeam 0;
BA_ "GenSigSendType" SG_ 522 ActnOfLedLoBeamActnOfLedLoBeam 0;
BA_ "GenSigSendType" SG_ 522 ActnOfLedLoBeamChks 0;
BA_ "GenSigFuncType" SG_ 522 ActnOfLedLoBeamChks 15;
BA_ "GenSigDataID" SG_ 522 ActnOfLedLoBeamChks "0x441";
BA_ "GenSigSendType" SG_ 522 ActnOfLedLoBeamCntr 0;
BA_ "GenSigFuncType" SG_ 522 ActnOfLedLoBeamCntr 16;
BA_ "GenSigSendType" SG_ 522 ActnOfLedPosnLamp 0;
BA_ "GenSigSendType" SG_ 522 ActnOfLedReFogLamp 0;
BA_ "GenSigSendType" SG_ 522 ActnOfLedRePosnLamp 0;
BA_ "GenSigSendType" SG_ 522 ActnOfLedRvsgLamp 0;
BA_ "GenSigSendType" SG_ 522 ActnOfLedStopLampActnOfLedStopLamp 0;
BA_ "GenSigSendType" SG_ 522 ActnOfLedStopLampChks 0;
BA_ "GenSigFuncType" SG_ 522 ActnOfLedStopLampChks 15;
BA_ "GenSigDataID" SG_ 522 ActnOfLedStopLampChks "0x443";
BA_ "GenSigSendType" SG_ 522 ActnOfLedStopLampCntr 0;
BA_ "GenSigFuncType" SG_ 522 ActnOfLedStopLampCntr 16;
BA_ "GenSigSendType" SG_ 522 ActvnOfAfs 0;
BA_ "GenSigSendType" SG_ 522 ActvnOfAhbc 0;
BA_ "GenSigSendType" SG_ 522 ActvnOfAhl 0;
BA_ "GenSigSendType" SG_ 522 ActvnOfBrkLi 0;
BA_ "GenSigSendType" SG_ 522 ActvnOfDbl 0;
BA_ "GenSigSendType" SG_ 522 ActvnOfGoodByeLi 0;
BA_ "GenSigSendType" SG_ 522 ActvnOfTouristMod 0;
BA_ "GenSigSendType" SG_ 522 ActvnOfWelcomeLi 0;
// Frame: CemBodyExpoFr51
BA_ "GenMsgSendType" BO_ 538 0;
BA_ "GenMsgCycleTime" BO_ 538 20.000;
BA_ "GenSigSendType" SG_ 538 ActvnOfIndcrIndcrOut 0;
BA_ "GenSigSendType" SG_ 538 ActvnOfIndcrIndcrOutChks 0;
BA_ "GenSigFuncType" SG_ 538 ActvnOfIndcrIndcrOutChks 15;
BA_ "GenSigDataID" SG_ 538 ActvnOfIndcrIndcrOutChks "0x9E";
BA_ "GenSigSendType" SG_ 538 ActvnOfIndcrIndcrOutCntr 0;
BA_ "GenSigFuncType" SG_ 538 ActvnOfIndcrIndcrOutCntr 16;
BA_ "GenSigSendType" SG_ 538 DoorLeReAutoManReq 0;
BA_ "GenSigSendType" SG_ 538 DoorPassAutoManReq 0;
BA_ "GenSigSendType" SG_ 538 DoorRiReAutoManReq 0;
BA_ "GenSigStartValue" SG_ 538 EmgyBrkLiIndcrTurn 1;
BA_ "GenSigSendType" SG_ 538 EmgyBrkLiIndcrTurn 0;
BA_ "GenSigSendType" SG_ 538 IndcrPatCmd1WdTiOff 0;
BA_ "GenSigSendType" SG_ 538 IndcrPatCmd1WdTiOn 0;
BA_ "GenSigSendType" SG_ 538 IndcrSts 0;
// Frame: CemBodyExpoFr52
BA_ "GenMsgSendType" BO_ 326 1;
BA_ "GenMsgDelayTime" BO_ 326 30.000;
BA_ "GenSigSendType" SG_ 326 DwnLoadDynLitPrmForLedLogoLampContTiPrm 1;
BA_ "GenSigSendType" SG_ 326 DwnLoadDynLitPrmForLedLogoLampLowBriPrm 1;
BA_ "GenSigSendType" SG_ 326 DwnLoadDynLitPrmForLedLogoLampModePrm 1;
BA_ "GenSigSendType" SG_ 326 DwnLoadDynLitPrmForLedLogoLampOffsTiPrm 1;
BA_ "GenSigSendType" SG_ 326 DwnLoadDynLitPrmForLedLogoLampTistamp 1;
BA_ "GenSigSendType" SG_ 326 DwnLoadDynLitPrmForLedLogoLampUpprBriPrm 1;
// Frame: CemBodyExpoFr53
BA_ "GenMsgSendType" BO_ 327 1;
BA_ "GenMsgDelayTime" BO_ 327 30.000;
BA_ "GenSigSendType" SG_ 327 DwnLoadDynLitPrmLedRePosnLampLe3ContTiPrm 1;
BA_ "SigGroup" SG_ 327 DwnLoadDynLitPrmLedRePosnLampLe3ContTiPrm "DwnLoadDynLitPrmLedRePosnLampLe3";
BA_ "GenSigSendType" SG_ 327 DwnLoadDynLitPrmLedRePosnLampLe3LowBriPrm 1;
BA_ "SigGroup" SG_ 327 DwnLoadDynLitPrmLedRePosnLampLe3LowBriPrm "DwnLoadDynLitPrmLedRePosnLampLe3";
BA_ "GenSigSendType" SG_ 327 DwnLoadDynLitPrmLedRePosnLampLe3ModePrm 1;
BA_ "SigGroup" SG_ 327 DwnLoadDynLitPrmLedRePosnLampLe3ModePrm "DwnLoadDynLitPrmLedRePosnLampLe3";
BA_ "GenSigSendType" SG_ 327 DwnLoadDynLitPrmLedRePosnLampLe3OffsTiPrm 1;
BA_ "SigGroup" SG_ 327 DwnLoadDynLitPrmLedRePosnLampLe3OffsTiPrm "DwnLoadDynLitPrmLedRePosnLampLe3";
BA_ "GenSigSendType" SG_ 327 DwnLoadDynLitPrmLedRePosnLampLe3Tistamp 1;
BA_ "SigGroup" SG_ 327 DwnLoadDynLitPrmLedRePosnLampLe3Tistamp "DwnLoadDynLitPrmLedRePosnLampLe3";
BA_ "GenSigSendType" SG_ 327 DwnLoadDynLitPrmLedRePosnLampLe3UpprBriPrm 1;
BA_ "SigGroup" SG_ 327 DwnLoadDynLitPrmLedRePosnLampLe3UpprBriPrm "DwnLoadDynLitPrmLedRePosnLampLe3";
// Frame: CemBodyExpoFr54
BA_ "GenMsgSendType" BO_ 328 1;
BA_ "GenMsgDelayTime" BO_ 328 30.000;
BA_ "GenSigSendType" SG_ 328 DwnLoadDynLitPrmLedRePosnLampLe4ContTiPrm 1;
BA_ "SigGroup" SG_ 328 DwnLoadDynLitPrmLedRePosnLampLe4ContTiPrm "DwnLoadDynLitPrmLedRePosnLampLe4";
BA_ "GenSigSendType" SG_ 328 DwnLoadDynLitPrmLedRePosnLampLe4LowBriPrm 1;
BA_ "SigGroup" SG_ 328 DwnLoadDynLitPrmLedRePosnLampLe4LowBriPrm "DwnLoadDynLitPrmLedRePosnLampLe4";
BA_ "GenSigSendType" SG_ 328 DwnLoadDynLitPrmLedRePosnLampLe4ModePrm 1;
BA_ "SigGroup" SG_ 328 DwnLoadDynLitPrmLedRePosnLampLe4ModePrm "DwnLoadDynLitPrmLedRePosnLampLe4";
BA_ "GenSigSendType" SG_ 328 DwnLoadDynLitPrmLedRePosnLampLe4OffsTiPrm 1;
BA_ "SigGroup" SG_ 328 DwnLoadDynLitPrmLedRePosnLampLe4OffsTiPrm "DwnLoadDynLitPrmLedRePosnLampLe4";
BA_ "GenSigSendType" SG_ 328 DwnLoadDynLitPrmLedRePosnLampLe4Tistamp 1;
BA_ "SigGroup" SG_ 328 DwnLoadDynLitPrmLedRePosnLampLe4Tistamp "DwnLoadDynLitPrmLedRePosnLampLe4";
BA_ "GenSigSendType" SG_ 328 DwnLoadDynLitPrmLedRePosnLampLe4UpprBriPrm 1;
BA_ "SigGroup" SG_ 328 DwnLoadDynLitPrmLedRePosnLampLe4UpprBriPrm "DwnLoadDynLitPrmLedRePosnLampLe4";
// Frame: CemBodyExpoFr55
BA_ "GenMsgSendType" BO_ 329 1;
BA_ "GenMsgDelayTime" BO_ 329 30.000;
BA_ "GenSigSendType" SG_ 329 DwnLoadDynLitPrmLedRePosnLampLe5ContTiPrm 1;
BA_ "SigGroup" SG_ 329 DwnLoadDynLitPrmLedRePosnLampLe5ContTiPrm "DwnLoadDynLitPrmLedRePosnLampLe5";
BA_ "GenSigSendType" SG_ 329 DwnLoadDynLitPrmLedRePosnLampLe5LowBriPrm 1;
BA_ "SigGroup" SG_ 329 DwnLoadDynLitPrmLedRePosnLampLe5LowBriPrm "DwnLoadDynLitPrmLedRePosnLampLe5";
BA_ "GenSigSendType" SG_ 329 DwnLoadDynLitPrmLedRePosnLampLe5ModePrm 1;
BA_ "SigGroup" SG_ 329 DwnLoadDynLitPrmLedRePosnLampLe5ModePrm "DwnLoadDynLitPrmLedRePosnLampLe5";
BA_ "GenSigSendType" SG_ 329 DwnLoadDynLitPrmLedRePosnLampLe5OffsTiPrm 1;
BA_ "SigGroup" SG_ 329 DwnLoadDynLitPrmLedRePosnLampLe5OffsTiPrm "DwnLoadDynLitPrmLedRePosnLampLe5";
BA_ "GenSigSendType" SG_ 329 DwnLoadDynLitPrmLedRePosnLampLe5Tistamp 1;
BA_ "SigGroup" SG_ 329 DwnLoadDynLitPrmLedRePosnLampLe5Tistamp "DwnLoadDynLitPrmLedRePosnLampLe5";
BA_ "GenSigSendType" SG_ 329 DwnLoadDynLitPrmLedRePosnLampLe5UpprBriPrm 1;
BA_ "SigGroup" SG_ 329 DwnLoadDynLitPrmLedRePosnLampLe5UpprBriPrm "DwnLoadDynLitPrmLedRePosnLampLe5";
// Frame: CemBodyExpoFr56
BA_ "GenMsgSendType" BO_ 330 1;
BA_ "GenMsgDelayTime" BO_ 330 30.000;
BA_ "GenSigSendType" SG_ 330 DwnLoadDynLitPrmLedRePosnLampRi3ContTiPrm 1;
BA_ "SigGroup" SG_ 330 DwnLoadDynLitPrmLedRePosnLampRi3ContTiPrm "DwnLoadDynLitPrmLedRePosnLampRi3";
BA_ "GenSigSendType" SG_ 330 DwnLoadDynLitPrmLedRePosnLampRi3LowBriPrm 1;
BA_ "SigGroup" SG_ 330 DwnLoadDynLitPrmLedRePosnLampRi3LowBriPrm "DwnLoadDynLitPrmLedRePosnLampRi3";
BA_ "GenSigSendType" SG_ 330 DwnLoadDynLitPrmLedRePosnLampRi3ModePrm 1;
BA_ "SigGroup" SG_ 330 DwnLoadDynLitPrmLedRePosnLampRi3ModePrm "DwnLoadDynLitPrmLedRePosnLampRi3";
BA_ "GenSigSendType" SG_ 330 DwnLoadDynLitPrmLedRePosnLampRi3OffsTiPrm 1;
BA_ "SigGroup" SG_ 330 DwnLoadDynLitPrmLedRePosnLampRi3OffsTiPrm "DwnLoadDynLitPrmLedRePosnLampRi3";
BA_ "GenSigSendType" SG_ 330 DwnLoadDynLitPrmLedRePosnLampRi3Tistamp 1;
BA_ "SigGroup" SG_ 330 DwnLoadDynLitPrmLedRePosnLampRi3Tistamp "DwnLoadDynLitPrmLedRePosnLampRi3";
BA_ "GenSigSendType" SG_ 330 DwnLoadDynLitPrmLedRePosnLampRi3UpprBriPrm 1;
BA_ "SigGroup" SG_ 330 DwnLoadDynLitPrmLedRePosnLampRi3UpprBriPrm "DwnLoadDynLitPrmLedRePosnLampRi3";
// Frame: CemBodyExpoFr57
BA_ "GenMsgSendType" BO_ 331 1;
BA_ "GenMsgDelayTime" BO_ 331 30.000;
BA_ "GenSigSendType" SG_ 331 DwnLoadDynLitPrmLedRePosnLampRi4ContTiPrm 1;
BA_ "SigGroup" SG_ 331 DwnLoadDynLitPrmLedRePosnLampRi4ContTiPrm "DwnLoadDynLitPrmLedRePosnLampRi4";
BA_ "GenSigSendType" SG_ 331 DwnLoadDynLitPrmLedRePosnLampRi4LowBriPrm 1;
BA_ "SigGroup" SG_ 331 DwnLoadDynLitPrmLedRePosnLampRi4LowBriPrm "DwnLoadDynLitPrmLedRePosnLampRi4";
BA_ "GenSigSendType" SG_ 331 DwnLoadDynLitPrmLedRePosnLampRi4ModePrm 1;
BA_ "SigGroup" SG_ 331 DwnLoadDynLitPrmLedRePosnLampRi4ModePrm "DwnLoadDynLitPrmLedRePosnLampRi4";
BA_ "GenSigSendType" SG_ 331 DwnLoadDynLitPrmLedRePosnLampRi4OffsTiPrm 1;
BA_ "SigGroup" SG_ 331 DwnLoadDynLitPrmLedRePosnLampRi4OffsTiPrm "DwnLoadDynLitPrmLedRePosnLampRi4";
BA_ "GenSigSendType" SG_ 331 DwnLoadDynLitPrmLedRePosnLampRi4Tistamp 1;
BA_ "SigGroup" SG_ 331 DwnLoadDynLitPrmLedRePosnLampRi4Tistamp "DwnLoadDynLitPrmLedRePosnLampRi4";
BA_ "GenSigSendType" SG_ 331 DwnLoadDynLitPrmLedRePosnLampRi4UpprBriPrm 1;
BA_ "SigGroup" SG_ 331 DwnLoadDynLitPrmLedRePosnLampRi4UpprBriPrm "DwnLoadDynLitPrmLedRePosnLampRi4";
// Frame: CemBodyExpoFr58
BA_ "GenMsgSendType" BO_ 332 1;
BA_ "GenMsgDelayTime" BO_ 332 30.000;
BA_ "GenSigSendType" SG_ 332 DwnLoadDynLitPrmLedRePosnLampRi5ContTiPrm 1;
BA_ "SigGroup" SG_ 332 DwnLoadDynLitPrmLedRePosnLampRi5ContTiPrm "DwnLoadDynLitPrmLedRePosnLampRi5";
BA_ "GenSigSendType" SG_ 332 DwnLoadDynLitPrmLedRePosnLampRi5LowBriPrm 1;
BA_ "SigGroup" SG_ 332 DwnLoadDynLitPrmLedRePosnLampRi5LowBriPrm "DwnLoadDynLitPrmLedRePosnLampRi5";
BA_ "GenSigSendType" SG_ 332 DwnLoadDynLitPrmLedRePosnLampRi5ModePrm 1;
BA_ "SigGroup" SG_ 332 DwnLoadDynLitPrmLedRePosnLampRi5ModePrm "DwnLoadDynLitPrmLedRePosnLampRi5";
BA_ "GenSigSendType" SG_ 332 DwnLoadDynLitPrmLedRePosnLampRi5OffsTiPrm 1;
BA_ "SigGroup" SG_ 332 DwnLoadDynLitPrmLedRePosnLampRi5OffsTiPrm "DwnLoadDynLitPrmLedRePosnLampRi5";
BA_ "GenSigSendType" SG_ 332 DwnLoadDynLitPrmLedRePosnLampRi5Tistamp 1;
BA_ "SigGroup" SG_ 332 DwnLoadDynLitPrmLedRePosnLampRi5Tistamp "DwnLoadDynLitPrmLedRePosnLampRi5";
BA_ "GenSigSendType" SG_ 332 DwnLoadDynLitPrmLedRePosnLampRi5UpprBriPrm 1;
BA_ "SigGroup" SG_ 332 DwnLoadDynLitPrmLedRePosnLampRi5UpprBriPrm "DwnLoadDynLitPrmLedRePosnLampRi5";
// Frame: CemBodyExpoFr59
BA_ "GenMsgSendType" BO_ 24 0;
BA_ "GenMsgCycleTime" BO_ 24 15.000;
BA_ "GenSigStartValue" SG_ 24 DoorDrvrPercSetFromHmi 100;
BA_ "GenSigSendType" SG_ 24 DoorDrvrPercSetFromHmi 0;
BA_ "GenSigSendType" SG_ 24 DoorDrvrSts 0;
BA_ "GenSigSendType" SG_ 24 DoorLeReSts 0;
BA_ "GenSigSendType" SG_ 24 DoorOpenwarnLeIndcn 0;
BA_ "GenSigStartValue" SG_ 24 DoorOpenwarnOn1 1;
BA_ "GenSigSendType" SG_ 24 DoorOpenwarnOn1 0;
BA_ "GenSigSendType" SG_ 24 DoorOpenwarnRiIndcn 0;
BA_ "GenSigStartValue" SG_ 24 DoorPassPercSetFromHmi 100;
BA_ "GenSigSendType" SG_ 24 DoorPassPercSetFromHmi 0;
BA_ "GenSigStartValue" SG_ 24 DoorRiRePercSetFromHmi 100;
BA_ "GenSigSendType" SG_ 24 DoorRiRePercSetFromHmi 0;
BA_ "GenSigStartValue" SG_ 24 GrilleLampColorSelnReq 1;
BA_ "GenSigSendType" SG_ 24 GrilleLampColorSelnReq 0;
BA_ "GenSigSendType" SG_ 24 HvBattSoc 0;
BA_ "GenSigStartValue" SG_ 24 PassPwrDoorManStrengthLvl 2;
BA_ "GenSigSendType" SG_ 24 PassPwrDoorManStrengthLvl 0;
BA_ "GenSigSendType" SG_ 24 WelcomeGoodbyeModeReq 0;
// Frame: CemBodyExpoFr60
BA_ "GenMsgSendType" BO_ 333 1;
BA_ "GenMsgDelayTime" BO_ 333 30.000;
BA_ "GenSigSendType" SG_ 333 DwnLoadDynLitPrmLedLeGrilleLampContTiPrm 1;
BA_ "GenSigSendType" SG_ 333 DwnLoadDynLitPrmLedLeGrilleLampLowBriPrm 1;
BA_ "GenSigSendType" SG_ 333 DwnLoadDynLitPrmLedLeGrilleLampModePrm 1;
BA_ "GenSigSendType" SG_ 333 DwnLoadDynLitPrmLedLeGrilleLampOffsTiPrm 1;
BA_ "GenSigSendType" SG_ 333 DwnLoadDynLitPrmLedLeGrilleLampTistamp 1;
BA_ "GenSigSendType" SG_ 333 DwnLoadDynLitPrmLedLeGrilleLampUpprBriPrm 1;
// Frame: CemBodyExpoFr61
BA_ "GenMsgSendType" BO_ 334 1;
BA_ "GenMsgDelayTime" BO_ 334 30.000;
BA_ "GenSigSendType" SG_ 334 DwnLoadDynLitPrmLedRiGrilleLampContTiPrm 1;
BA_ "GenSigSendType" SG_ 334 DwnLoadDynLitPrmLedRiGrilleLampLowBriPrm 1;
BA_ "GenSigSendType" SG_ 334 DwnLoadDynLitPrmLedRiGrilleLampModePrm 1;
BA_ "GenSigSendType" SG_ 334 DwnLoadDynLitPrmLedRiGrilleLampOffsTiPrm 1;
BA_ "GenSigSendType" SG_ 334 DwnLoadDynLitPrmLedRiGrilleLampTistamp 1;
BA_ "GenSigSendType" SG_ 334 DwnLoadDynLitPrmLedRiGrilleLampUpprBriPrm 1;
// Frame: CemBodyExpoFr62
BA_ "GenMsgSendType" BO_ 788 1;
BA_ "GenMsgDelayTime" BO_ 788 150.000;
BA_ "GenSigSendType" SG_ 788 DHUcontrolLedMkrLampLe1 1;
BA_ "GenSigSendType" SG_ 788 DHUcontrolLedMkrLampLe2 1;
BA_ "GenSigSendType" SG_ 788 DHUcontrolLedMkrLampRi1 1;
BA_ "GenSigSendType" SG_ 788 DHUcontrolLedMkrLampRi2 1;
BA_ "GenSigSendType" SG_ 788 DHUcontrolLedStopLampLe1 1;
BA_ "GenSigSendType" SG_ 788 DHUcontrolLedStopLampLe2 1;
BA_ "GenSigSendType" SG_ 788 DHUcontrolLedStopLampRi1 1;
BA_ "GenSigSendType" SG_ 788 DHUcontrolLedStopLampRi2 1;
BA_ "GenSigSendType" SG_ 788 DHUcontrolmiddlebrakelight 1;
BA_ "GenSigSendType" SG_ 788 DHUcontrolmiddlecorneringlamp 1;
BA_ "GenSigSendType" SG_ 788 DHUcontrolmiddlepositionlight 1;
VAL_ 360 DoorOpenerPassReqDoorOpenerReq 0 "DoorOpenerIdle" 1 "DoorOpenerOpen" 2 "DoorOpenerCls" 3 "DoorOpenerStop";
VAL_ 360 DoorOpenerPassReqTrigSrc 0 "NoTrigSrc" 1 "KeyRem" 2 "HMI" 3 "Telm" 4 "OutdSwt" 5 "InsdSwt";
VAL_ 360 DoorOpenerRiReReqDoorOpenerReq 0 "DoorOpenerIdle" 1 "DoorOpenerOpen" 2 "DoorOpenerCls" 3 "DoorOpenerStop";
VAL_ 360 DoorOpenerRiReReqTrigSrc 0 "NoTrigSrc" 1 "KeyRem" 2 "HMI" 3 "Telm" 4 "OutdSwt" 5 "InsdSwt";
VAL_ 360 ReRiPwrDoorManStrengthLvl 0 "SelectLvl_Idle" 1 "SelectLvl_Level1" 2 "SelectLvl_Level2" 3 "SelectLvl_Level3";
VAL_ 86 DHUcontrolleftcorneringlamp 0 "OnOffNoReq_NoReq" 1 "OnOffNoReq_On" 2 "OnOffNoReq_Off";
VAL_ 86 DHUcontrolleftdaytimerunninglamp 0 "OnOffNoReq_NoReq" 1 "OnOffNoReq_On" 2 "OnOffNoReq_Off";
VAL_ 86 DHUcontrolleftfroglight 0 "OnOffNoReq_NoReq" 1 "OnOffNoReq_On" 2 "OnOffNoReq_Off";
VAL_ 86 DHUcontrollefthighbeamlamp 0 "OnOffNoReq_NoReq" 1 "OnOffNoReq_On" 2 "OnOffNoReq_Off";
VAL_ 86 DHUcontrolleftlowbeamlamp 0 "OnOffNoReq_NoReq" 1 "OnOffNoReq_On" 2 "OnOffNoReq_Off";
VAL_ 86 DHUcontrolleftpositionlamp 0 "OnOffNoReq_NoReq" 1 "OnOffNoReq_On" 2 "OnOffNoReq_Off";
VAL_ 86 DHUcontrolrightcorneringlamp 0 "OnOffNoReq_NoReq" 1 "OnOffNoReq_On" 2 "OnOffNoReq_Off";
VAL_ 86 DHUcontrolrightdaytimerunninglamp 0 "OnOffNoReq_NoReq" 1 "OnOffNoReq_On" 2 "OnOffNoReq_Off";
VAL_ 86 DHUcontrolrightfroglight 0 "OnOffNoReq_NoReq" 1 "OnOffNoReq_On" 2 "OnOffNoReq_Off";
VAL_ 86 DHUcontrolrighthighbeamlamp 0 "OnOffNoReq_NoReq" 1 "OnOffNoReq_On" 2 "OnOffNoReq_Off";
VAL_ 86 DHUcontrolrightlowbeamlamp 0 "OnOffNoReq_NoReq" 1 "OnOffNoReq_On" 2 "OnOffNoReq_Off";
VAL_ 86 DHUcontrolrightpositionLamp 0 "OnOffNoReq_NoReq" 1 "OnOffNoReq_On" 2 "OnOffNoReq_Off";
VAL_ 298 DwnLoadDynLitPrmForLedStopLampRi1ModePrm 0 "Mode1_Off" 1 "Mode1_On" 2 "Mode1_GradualOn" 3 "Mode1_GradualOff" 4 "Mode1_ForwardWipingOn" 5 "Mode1_BackwardWipingOn" 6 "Mode1_OutwardWipingOn" 7 "Mode1_InwardWipingOn" 8 "Mode1_ForwardWipingOff" 9 "Mode1_BackwardWipingOff" 10 "Mode1_OutwardWipingOff" 11 "Mode1_InwardWipingOff" 12 "Mode1_ForwardScanning" 13 "Mode1_BackwardScanning" 14 "Mode1_BreathOn" 15 "Mode1_BreathOff" 16 "Mode1_Spare1" 17 "Mode1_Spare2";
VAL_ 523 ActvOfGdbyeForGndLampLe 0 "OnOff1_Off" 1 "OnOff1_On";
VAL_ 523 ActvOfWelcomeForGndLampLe 0 "OnOff1_Off" 1 "OnOff1_On";
VAL_ 523 RoadInclnQly 0 "Qly2_Flt" 1 "Qly2_NoInfo" 2 "Qly2_Vld";
VAL_ 523 RollAgGlbQf 0 "Qly2_Flt" 1 "Qly2_NoInfo" 2 "Qly2_Vld";
VAL_ 640 SunCurtPosnSts 0 "WinAndRoofAndCurtPosnTyp_PosnUkwn" 1 "WinAndRoofAndCurtPosnTyp_ClsFull" 2 "WinAndRoofAndCurtPosnTyp_PercOpen4" 3 "WinAndRoofAndCurtPosnTyp_PercOpen8" 4 "WinAndRoofAndCurtPosnTyp_PercOpen12" 5 "WinAndRoofAndCurtPosnTyp_PercOpen16" 6 "WinAndRoofAndCurtPosnTyp_PercOpen20" 7 "WinAndRoofAndCurtPosnTyp_PercOpen24" 8 "WinAndRoofAndCurtPosnTyp_PercOpen28" 9 "WinAndRoofAndCurtPosnTyp_PercOpen32" 10 "WinAndRoofAndCurtPosnTyp_PercOpen36" 11 "WinAndRoofAndCurtPosnTyp_PercOpen40" 12 "WinAndRoofAndCurtPosnTyp_PercOpen44" 13 "WinAndRoofAndCurtPosnTyp_PercOpen48" 14 "WinAndRoofAndCurtPosnTyp_PercOpen52" 15 "WinAndRoofAndCurtPosnTyp_PercOpen56" 16 "WinAndRoofAndCurtPosnTyp_PercOpen60" 17 "WinAndRoofAndCurtPosnTyp_PercOpen64" 18 "WinAndRoofAndCurtPosnTyp_PercOpen68" 19 "WinAndRoofAndCurtPosnTyp_PercOpen72" 20 "WinAndRoofAndCurtPosnTyp_PercOpen76" 21 "WinAndRoofAndCurtPosnTyp_PercOpen80" 22 "WinAndRoofAndCurtPosnTyp_PercOpen84" 23 "WinAndRoofAndCurtPosnTyp_PercOpen88" 24 "WinAndRoofAndCurtPosnTyp_PercOpen92" 25 "WinAndRoofAndCurtPosnTyp_PercOpen96" 26 "WinAndRoofAndCurtPosnTyp_OpenFull" 27 "WinAndRoofAndCurtPosnTyp_Resd1" 28 "WinAndRoofAndCurtPosnTyp_Resd2" 29 "WinAndRoofAndCurtPosnTyp_Resd3" 30 "WinAndRoofAndCurtPosnTyp_Resd4" 31 "WinAndRoofAndCurtPosnTyp_Movg";
VAL_ 640 SunRoofPosnSts 0 "WinAndRoofAndCurtPosnTyp_PosnUkwn" 1 "WinAndRoofAndCurtPosnTyp_ClsFull" 2 "WinAndRoofAndCurtPosnTyp_PercOpen4" 3 "WinAndRoofAndCurtPosnTyp_PercOpen8" 4 "WinAndRoofAndCurtPosnTyp_PercOpen12" 5 "WinAndRoofAndCurtPosnTyp_PercOpen16" 6 "WinAndRoofAndCurtPosnTyp_PercOpen20" 7 "WinAndRoofAndCurtPosnTyp_PercOpen24" 8 "WinAndRoofAndCurtPosnTyp_PercOpen28" 9 "WinAndRoofAndCurtPosnTyp_PercOpen32" 10 "WinAndRoofAndCurtPosnTyp_PercOpen36" 11 "WinAndRoofAndCurtPosnTyp_PercOpen40" 12 "WinAndRoofAndCurtPosnTyp_PercOpen44" 13 "WinAndRoofAndCurtPosnTyp_PercOpen48" 14 "WinAndRoofAndCurtPosnTyp_PercOpen52" 15 "WinAndRoofAndCurtPosnTyp_PercOpen56" 16 "WinAndRoofAndCurtPosnTyp_PercOpen60" 17 "WinAndRoofAndCurtPosnTyp_PercOpen64" 18 "WinAndRoofAndCurtPosnTyp_PercOpen68" 19 "WinAndRoofAndCurtPosnTyp_PercOpen72" 20 "WinAndRoofAndCurtPosnTyp_PercOpen76" 21 "WinAndRoofAndCurtPosnTyp_PercOpen80" 22 "WinAndRoofAndCurtPosnTyp_PercOpen84" 23 "WinAndRoofAndCurtPosnTyp_PercOpen88" 24 "WinAndRoofAndCurtPosnTyp_PercOpen92" 25 "WinAndRoofAndCurtPosnTyp_PercOpen96" 26 "WinAndRoofAndCurtPosnTyp_OpenFull" 27 "WinAndRoofAndCurtPosnTyp_Resd1" 28 "WinAndRoofAndCurtPosnTyp_Resd2" 29 "WinAndRoofAndCurtPosnTyp_Resd3" 30 "WinAndRoofAndCurtPosnTyp_Resd4" 31 "WinAndRoofAndCurtPosnTyp_Movg";
VAL_ 640 WinPosnStsAtDrvr 0 "WinAndRoofAndCurtPosnTyp_PosnUkwn" 1 "WinAndRoofAndCurtPosnTyp_ClsFull" 2 "WinAndRoofAndCurtPosnTyp_PercOpen4" 3 "WinAndRoofAndCurtPosnTyp_PercOpen8" 4 "WinAndRoofAndCurtPosnTyp_PercOpen12" 5 "WinAndRoofAndCurtPosnTyp_PercOpen16" 6 "WinAndRoofAndCurtPosnTyp_PercOpen20" 7 "WinAndRoofAndCurtPosnTyp_PercOpen24" 8 "WinAndRoofAndCurtPosnTyp_PercOpen28" 9 "WinAndRoofAndCurtPosnTyp_PercOpen32" 10 "WinAndRoofAndCurtPosnTyp_PercOpen36" 11 "WinAndRoofAndCurtPosnTyp_PercOpen40" 12 "WinAndRoofAndCurtPosnTyp_PercOpen44" 13 "WinAndRoofAndCurtPosnTyp_PercOpen48" 14 "WinAndRoofAndCurtPosnTyp_PercOpen52" 15 "WinAndRoofAndCurtPosnTyp_PercOpen56" 16 "WinAndRoofAndCurtPosnTyp_PercOpen60" 17 "WinAndRoofAndCurtPosnTyp_PercOpen64" 18 "WinAndRoofAndCurtPosnTyp_PercOpen68" 19 "WinAndRoofAndCurtPosnTyp_PercOpen72" 20 "WinAndRoofAndCurtPosnTyp_PercOpen76" 21 "WinAndRoofAndCurtPosnTyp_PercOpen80" 22 "WinAndRoofAndCurtPosnTyp_PercOpen84" 23 "WinAndRoofAndCurtPosnTyp_PercOpen88" 24 "WinAndRoofAndCurtPosnTyp_PercOpen92" 25 "WinAndRoofAndCurtPosnTyp_PercOpen96" 26 "WinAndRoofAndCurtPosnTyp_OpenFull" 27 "WinAndRoofAndCurtPosnTyp_Resd1" 28 "WinAndRoofAndCurtPosnTyp_Resd2" 29 "WinAndRoofAndCurtPosnTyp_Resd3" 30 "WinAndRoofAndCurtPosnTyp_Resd4" 31 "WinAndRoofAndCurtPosnTyp_Movg";
VAL_ 640 WinPosnStsAtPass 0 "WinAndRoofAndCurtPosnTyp_PosnUkwn" 1 "WinAndRoofAndCurtPosnTyp_ClsFull" 2 "WinAndRoofAndCurtPosnTyp_PercOpen4" 3 "WinAndRoofAndCurtPosnTyp_PercOpen8" 4 "WinAndRoofAndCurtPosnTyp_PercOpen12" 5 "WinAndRoofAndCurtPosnTyp_PercOpen16" 6 "WinAndRoofAndCurtPosnTyp_PercOpen20" 7 "WinAndRoofAndCurtPosnTyp_PercOpen24" 8 "WinAndRoofAndCurtPosnTyp_PercOpen28" 9 "WinAndRoofAndCurtPosnTyp_PercOpen32" 10 "WinAndRoofAndCurtPosnTyp_PercOpen36" 11 "WinAndRoofAndCurtPosnTyp_PercOpen40" 12 "WinAndRoofAndCurtPosnTyp_PercOpen44" 13 "WinAndRoofAndCurtPosnTyp_PercOpen48" 14 "WinAndRoofAndCurtPosnTyp_PercOpen52" 15 "WinAndRoofAndCurtPosnTyp_PercOpen56" 16 "WinAndRoofAndCurtPosnTyp_PercOpen60" 17 "WinAndRoofAndCurtPosnTyp_PercOpen64" 18 "WinAndRoofAndCurtPosnTyp_PercOpen68" 19 "WinAndRoofAndCurtPosnTyp_PercOpen72" 20 "WinAndRoofAndCurtPosnTyp_PercOpen76" 21 "WinAndRoofAndCurtPosnTyp_PercOpen80" 22 "WinAndRoofAndCurtPosnTyp_PercOpen84" 23 "WinAndRoofAndCurtPosnTyp_PercOpen88" 24 "WinAndRoofAndCurtPosnTyp_PercOpen92" 25 "WinAndRoofAndCurtPosnTyp_PercOpen96" 26 "WinAndRoofAndCurtPosnTyp_OpenFull" 27 "WinAndRoofAndCurtPosnTyp_Resd1" 28 "WinAndRoofAndCurtPosnTyp_Resd2" 29 "WinAndRoofAndCurtPosnTyp_Resd3" 30 "WinAndRoofAndCurtPosnTyp_Resd4" 31 "WinAndRoofAndCurtPosnTyp_Movg";
VAL_ 640 WinPosnStsAtReLe 0 "WinAndRoofAndCurtPosnTyp_PosnUkwn" 1 "WinAndRoofAndCurtPosnTyp_ClsFull" 2 "WinAndRoofAndCurtPosnTyp_PercOpen4" 3 "WinAndRoofAndCurtPosnTyp_PercOpen8" 4 "WinAndRoofAndCurtPosnTyp_PercOpen12" 5 "WinAndRoofAndCurtPosnTyp_PercOpen16" 6 "WinAndRoofAndCurtPosnTyp_PercOpen20" 7 "WinAndRoofAndCurtPosnTyp_PercOpen24" 8 "WinAndRoofAndCurtPosnTyp_PercOpen28" 9 "WinAndRoofAndCurtPosnTyp_PercOpen32" 10 "WinAndRoofAndCurtPosnTyp_PercOpen36" 11 "WinAndRoofAndCurtPosnTyp_PercOpen40" 12 "WinAndRoofAndCurtPosnTyp_PercOpen44" 13 "WinAndRoofAndCurtPosnTyp_PercOpen48" 14 "WinAndRoofAndCurtPosnTyp_PercOpen52" 15 "WinAndRoofAndCurtPosnTyp_PercOpen56" 16 "WinAndRoofAndCurtPosnTyp_PercOpen60" 17 "WinAndRoofAndCurtPosnTyp_PercOpen64" 18 "WinAndRoofAndCurtPosnTyp_PercOpen68" 19 "WinAndRoofAndCurtPosnTyp_PercOpen72" 20 "WinAndRoofAndCurtPosnTyp_PercOpen76" 21 "WinAndRoofAndCurtPosnTyp_PercOpen80" 22 "WinAndRoofAndCurtPosnTyp_PercOpen84" 23 "WinAndRoofAndCurtPosnTyp_PercOpen88" 24 "WinAndRoofAndCurtPosnTyp_PercOpen92" 25 "WinAndRoofAndCurtPosnTyp_PercOpen96" 26 "WinAndRoofAndCurtPosnTyp_OpenFull" 27 "WinAndRoofAndCurtPosnTyp_Resd1" 28 "WinAndRoofAndCurtPosnTyp_Resd2" 29 "WinAndRoofAndCurtPosnTyp_Resd3" 30 "WinAndRoofAndCurtPosnTyp_Resd4" 31 "WinAndRoofAndCurtPosnTyp_Movg";
VAL_ 640 WinPosnStsAtReRi 0 "WinAndRoofAndCurtPosnTyp_PosnUkwn" 1 "WinAndRoofAndCurtPosnTyp_ClsFull" 2 "WinAndRoofAndCurtPosnTyp_PercOpen4" 3 "WinAndRoofAndCurtPosnTyp_PercOpen8" 4 "WinAndRoofAndCurtPosnTyp_PercOpen12" 5 "WinAndRoofAndCurtPosnTyp_PercOpen16" 6 "WinAndRoofAndCurtPosnTyp_PercOpen20" 7 "WinAndRoofAndCurtPosnTyp_PercOpen24" 8 "WinAndRoofAndCurtPosnTyp_PercOpen28" 9 "WinAndRoofAndCurtPosnTyp_PercOpen32" 10 "WinAndRoofAndCurtPosnTyp_PercOpen36" 11 "WinAndRoofAndCurtPosnTyp_PercOpen40" 12 "WinAndRoofAndCurtPosnTyp_PercOpen44" 13 "WinAndRoofAndCurtPosnTyp_PercOpen48" 14 "WinAndRoofAndCurtPosnTyp_PercOpen52" 15 "WinAndRoofAndCurtPosnTyp_PercOpen56" 16 "WinAndRoofAndCurtPosnTyp_PercOpen60" 17 "WinAndRoofAndCurtPosnTyp_PercOpen64" 18 "WinAndRoofAndCurtPosnTyp_PercOpen68" 19 "WinAndRoofAndCurtPosnTyp_PercOpen72" 20 "WinAndRoofAndCurtPosnTyp_PercOpen76" 21 "WinAndRoofAndCurtPosnTyp_PercOpen80" 22 "WinAndRoofAndCurtPosnTyp_PercOpen84" 23 "WinAndRoofAndCurtPosnTyp_PercOpen88" 24 "WinAndRoofAndCurtPosnTyp_PercOpen92" 25 "WinAndRoofAndCurtPosnTyp_PercOpen96" 26 "WinAndRoofAndCurtPosnTyp_OpenFull" 27 "WinAndRoofAndCurtPosnTyp_Resd1" 28 "WinAndRoofAndCurtPosnTyp_Resd2" 29 "WinAndRoofAndCurtPosnTyp_Resd3" 30 "WinAndRoofAndCurtPosnTyp_Resd4" 31 "WinAndRoofAndCurtPosnTyp_Movg";
VAL_ 1110 VFCInfoEna 0 "EnableDisableCoding_Disabled" 1 "EnableDisableCoding_Enabled";
VAL_ 359 CarpetLiSetCarpetLiSet 0 "CarpetLiSet_Welcome" 1 "CarpetLiSet_Goodbye" 2 "CarpetLiSet_Dow";
VAL_ 359 CarpetLiTrialSetTrialSet 0 "TrialSet_Play" 1 "TrialSet_Suspend" 2 "TrialSet_Termination";
VAL_ 299 DwnLoadDynLitPrmLedReFogLampLe1ModePrm 0 "Mode1_Off" 1 "Mode1_On" 2 "Mode1_GradualOn" 3 "Mode1_GradualOff" 4 "Mode1_ForwardWipingOn" 5 "Mode1_BackwardWipingOn" 6 "Mode1_OutwardWipingOn" 7 "Mode1_InwardWipingOn" 8 "Mode1_ForwardWipingOff" 9 "Mode1_BackwardWipingOff" 10 "Mode1_OutwardWipingOff" 11 "Mode1_InwardWipingOff" 12 "Mode1_ForwardScanning" 13 "Mode1_BackwardScanning" 14 "Mode1_BreathOn" 15 "Mode1_BreathOff" 16 "Mode1_Spare1" 17 "Mode1_Spare2";
VAL_ 300 DwnLoadDynLitPrmLedReFogLampLe2ModePrm 0 "Mode1_Off" 1 "Mode1_On" 2 "Mode1_GradualOn" 3 "Mode1_GradualOff" 4 "Mode1_ForwardWipingOn" 5 "Mode1_BackwardWipingOn" 6 "Mode1_OutwardWipingOn" 7 "Mode1_InwardWipingOn" 8 "Mode1_ForwardWipingOff" 9 "Mode1_BackwardWipingOff" 10 "Mode1_OutwardWipingOff" 11 "Mode1_InwardWipingOff" 12 "Mode1_ForwardScanning" 13 "Mode1_BackwardScanning" 14 "Mode1_BreathOn" 15 "Mode1_BreathOff" 16 "Mode1_Spare1" 17 "Mode1_Spare2";
VAL_ 301 DwnLoadDynLitPrmLedReFogLampRi1ModePrm 0 "Mode1_Off" 1 "Mode1_On" 2 "Mode1_GradualOn" 3 "Mode1_GradualOff" 4 "Mode1_ForwardWipingOn" 5 "Mode1_BackwardWipingOn" 6 "Mode1_OutwardWipingOn" 7 "Mode1_InwardWipingOn" 8 "Mode1_ForwardWipingOff" 9 "Mode1_BackwardWipingOff" 10 "Mode1_OutwardWipingOff" 11 "Mode1_InwardWipingOff" 12 "Mode1_ForwardScanning" 13 "Mode1_BackwardScanning" 14 "Mode1_BreathOn" 15 "Mode1_BreathOff" 16 "Mode1_Spare1" 17 "Mode1_Spare2";
VAL_ 302 DwnLoadDynLitPrmLedRePosnLampLe1ModePrm 0 "Mode1_Off" 1 "Mode1_On" 2 "Mode1_GradualOn" 3 "Mode1_GradualOff" 4 "Mode1_ForwardWipingOn" 5 "Mode1_BackwardWipingOn" 6 "Mode1_OutwardWipingOn" 7 "Mode1_InwardWipingOn" 8 "Mode1_ForwardWipingOff" 9 "Mode1_BackwardWipingOff" 10 "Mode1_OutwardWipingOff" 11 "Mode1_InwardWipingOff" 12 "Mode1_ForwardScanning" 13 "Mode1_BackwardScanning" 14 "Mode1_BreathOn" 15 "Mode1_BreathOff" 16 "Mode1_Spare1" 17 "Mode1_Spare2";
VAL_ 303 DwnLoadDynLitPrmLedRePosnLampLe2ModePrm 0 "Mode1_Off" 1 "Mode1_On" 2 "Mode1_GradualOn" 3 "Mode1_GradualOff" 4 "Mode1_ForwardWipingOn" 5 "Mode1_BackwardWipingOn" 6 "Mode1_OutwardWipingOn" 7 "Mode1_InwardWipingOn" 8 "Mode1_ForwardWipingOff" 9 "Mode1_BackwardWipingOff" 10 "Mode1_OutwardWipingOff" 11 "Mode1_InwardWipingOff" 12 "Mode1_ForwardScanning" 13 "Mode1_BackwardScanning" 14 "Mode1_BreathOn" 15 "Mode1_BreathOff" 16 "Mode1_Spare1" 17 "Mode1_Spare2";
VAL_ 304 DwnLoadDynLitPrmLedRePosnLampRi1ModePrm 0 "Mode1_Off" 1 "Mode1_On" 2 "Mode1_GradualOn" 3 "Mode1_GradualOff" 4 "Mode1_ForwardWipingOn" 5 "Mode1_BackwardWipingOn" 6 "Mode1_OutwardWipingOn" 7 "Mode1_InwardWipingOn" 8 "Mode1_ForwardWipingOff" 9 "Mode1_BackwardWipingOff" 10 "Mode1_OutwardWipingOff" 11 "Mode1_InwardWipingOff" 12 "Mode1_ForwardScanning" 13 "Mode1_BackwardScanning" 14 "Mode1_BreathOn" 15 "Mode1_BreathOff" 16 "Mode1_Spare1" 17 "Mode1_Spare2";
VAL_ 305 DwnLoadDynLitPrmLedReTurnIndcrLe1ModePrm 0 "Mode1_Off" 1 "Mode1_On" 2 "Mode1_GradualOn" 3 "Mode1_GradualOff" 4 "Mode1_ForwardWipingOn" 5 "Mode1_BackwardWipingOn" 6 "Mode1_OutwardWipingOn" 7 "Mode1_InwardWipingOn" 8 "Mode1_ForwardWipingOff" 9 "Mode1_BackwardWipingOff" 10 "Mode1_OutwardWipingOff" 11 "Mode1_InwardWipingOff" 12 "Mode1_ForwardScanning" 13 "Mode1_BackwardScanning" 14 "Mode1_BreathOn" 15 "Mode1_BreathOff" 16 "Mode1_Spare1" 17 "Mode1_Spare2";
VAL_ 306 DwnLoadDynLitPrmLedReTurnIndcrLe2ModePrm 0 "Mode1_Off" 1 "Mode1_On" 2 "Mode1_GradualOn" 3 "Mode1_GradualOff" 4 "Mode1_ForwardWipingOn" 5 "Mode1_BackwardWipingOn" 6 "Mode1_OutwardWipingOn" 7 "Mode1_InwardWipingOn" 8 "Mode1_ForwardWipingOff" 9 "Mode1_BackwardWipingOff" 10 "Mode1_OutwardWipingOff" 11 "Mode1_InwardWipingOff" 12 "Mode1_ForwardScanning" 13 "Mode1_BackwardScanning" 14 "Mode1_BreathOn" 15 "Mode1_BreathOff" 16 "Mode1_Spare1" 17 "Mode1_Spare2";
VAL_ 307 DwnLoadDynLitPrmLedReTurnIndcrRi1ModePrm 0 "Mode1_Off" 1 "Mode1_On" 2 "Mode1_GradualOn" 3 "Mode1_GradualOff" 4 "Mode1_ForwardWipingOn" 5 "Mode1_BackwardWipingOn" 6 "Mode1_OutwardWipingOn" 7 "Mode1_InwardWipingOn" 8 "Mode1_ForwardWipingOff" 9 "Mode1_BackwardWipingOff" 10 "Mode1_OutwardWipingOff" 11 "Mode1_InwardWipingOff" 12 "Mode1_ForwardScanning" 13 "Mode1_BackwardScanning" 14 "Mode1_BreathOn" 15 "Mode1_BreathOff" 16 "Mode1_Spare1" 17 "Mode1_Spare2";
VAL_ 308 DwnLoadDynLitPrmLedRvsgLampLe1ModePrm 0 "Mode1_Off" 1 "Mode1_On" 2 "Mode1_GradualOn" 3 "Mode1_GradualOff" 4 "Mode1_ForwardWipingOn" 5 "Mode1_BackwardWipingOn" 6 "Mode1_OutwardWipingOn" 7 "Mode1_InwardWipingOn" 8 "Mode1_ForwardWipingOff" 9 "Mode1_BackwardWipingOff" 10 "Mode1_OutwardWipingOff" 11 "Mode1_InwardWipingOff" 12 "Mode1_ForwardScanning" 13 "Mode1_BackwardScanning" 14 "Mode1_BreathOn" 15 "Mode1_BreathOff" 16 "Mode1_Spare1" 17 "Mode1_Spare2";
VAL_ 309 DwnLoadDynLitPrmLedRvsgLampLe2ModePrm 0 "Mode1_Off" 1 "Mode1_On" 2 "Mode1_GradualOn" 3 "Mode1_GradualOff" 4 "Mode1_ForwardWipingOn" 5 "Mode1_BackwardWipingOn" 6 "Mode1_OutwardWipingOn" 7 "Mode1_InwardWipingOn" 8 "Mode1_ForwardWipingOff" 9 "Mode1_BackwardWipingOff" 10 "Mode1_OutwardWipingOff" 11 "Mode1_InwardWipingOff" 12 "Mode1_ForwardScanning" 13 "Mode1_BackwardScanning" 14 "Mode1_BreathOn" 15 "Mode1_BreathOff" 16 "Mode1_Spare1" 17 "Mode1_Spare2";
VAL_ 310 DwnLoadDynLitPrmLedRvsgLampRi1ModePrm 0 "Mode1_Off" 1 "Mode1_On" 2 "Mode1_GradualOn" 3 "Mode1_GradualOff" 4 "Mode1_ForwardWipingOn" 5 "Mode1_BackwardWipingOn" 6 "Mode1_OutwardWipingOn" 7 "Mode1_InwardWipingOn" 8 "Mode1_ForwardWipingOff" 9 "Mode1_BackwardWipingOff" 10 "Mode1_OutwardWipingOff" 11 "Mode1_InwardWipingOff" 12 "Mode1_ForwardScanning" 13 "Mode1_BackwardScanning" 14 "Mode1_BreathOn" 15 "Mode1_BreathOff" 16 "Mode1_Spare1" 17 "Mode1_Spare2";
VAL_ 120 CarpetLiModReq 0 "ModeReq_Mode1" 1 "ModeReq_Mode2" 2 "ModeReq_Mode3" 3 "ModeReq_Mode4" 4 "ModeReq_Mode5" 5 "ModeReq_Mode6";
VAL_ 120 CarpetLiSwtReq 0 "OnOff1_Off" 1 "OnOff1_On";
VAL_ 120 CarpetLiTiReq 0 "ModeReq_Mode1" 1 "ModeReq_Mode2" 2 "ModeReq_Mode3" 3 "ModeReq_Mode4" 4 "ModeReq_Mode5" 5 "ModeReq_Mode6";
VAL_ 120 DrvrPwrDoorManStrengthLvl 0 "SelectLvl_Idle" 1 "SelectLvl_Level1" 2 "SelectLvl_Level2" 3 "SelectLvl_Level3";
VAL_ 120 LvlgSwtSetReqADModCtrlInhbn 0 "NoInhb" 1 "L12LgtCtrlModInhb" 2 "AutoParkingModInhb" 3 "L12AndAutoParkingModInhb" 4 "L3ADModInhb" 5 "L3ADAndL12LgtCtrlModInhb" 6 "L3ADAndAutoParkingModInhb" 7 "L3ADAndAutoParkingAndL12LgtCtrlModInhb";
VAL_ 120 OutdBriSts 0 "OutdBriSts_Ukwn" 1 "OutdBriSts_Night" 2 "OutdBriSts_Day" 3 "OutdBriSts_Invld";
VAL_ 311 DwnLoadDynLitPrmForLedHiBeamLeModePrm 0 "Mode1_Off" 1 "Mode1_On" 2 "Mode1_GradualOn" 3 "Mode1_GradualOff" 4 "Mode1_ForwardWipingOn" 5 "Mode1_BackwardWipingOn" 6 "Mode1_OutwardWipingOn" 7 "Mode1_InwardWipingOn" 8 "Mode1_ForwardWipingOff" 9 "Mode1_BackwardWipingOff" 10 "Mode1_OutwardWipingOff" 11 "Mode1_InwardWipingOff" 12 "Mode1_ForwardScanning" 13 "Mode1_BackwardScanning" 14 "Mode1_BreathOn" 15 "Mode1_BreathOff" 16 "Mode1_Spare1" 17 "Mode1_Spare2";
VAL_ 312 DwnLoadDynLitPrmForLedLoBeamLeModePrm 0 "Mode1_Off" 1 "Mode1_On" 2 "Mode1_GradualOn" 3 "Mode1_GradualOff" 4 "Mode1_ForwardWipingOn" 5 "Mode1_BackwardWipingOn" 6 "Mode1_OutwardWipingOn" 7 "Mode1_InwardWipingOn" 8 "Mode1_ForwardWipingOff" 9 "Mode1_BackwardWipingOff" 10 "Mode1_OutwardWipingOff" 11 "Mode1_InwardWipingOff" 12 "Mode1_ForwardScanning" 13 "Mode1_BackwardScanning" 14 "Mode1_BreathOn" 15 "Mode1_BreathOff" 16 "Mode1_Spare1" 17 "Mode1_Spare2";
VAL_ 313 DwnLoadDynLtgPrmForLedAllWthrLampLeModePrm 0 "Mode1_Off" 1 "Mode1_On" 2 "Mode1_GradualOn" 3 "Mode1_GradualOff" 4 "Mode1_ForwardWipingOn" 5 "Mode1_BackwardWipingOn" 6 "Mode1_OutwardWipingOn" 7 "Mode1_InwardWipingOn" 8 "Mode1_ForwardWipingOff" 9 "Mode1_BackwardWipingOff" 10 "Mode1_OutwardWipingOff" 11 "Mode1_InwardWipingOff" 12 "Mode1_ForwardScanning" 13 "Mode1_BackwardScanning" 14 "Mode1_BreathOn" 15 "Mode1_BreathOff" 16 "Mode1_Spare1" 17 "Mode1_Spare2";
VAL_ 314 DwnLoadDynLtgPrmForLedAllWthrLampRiModePrm 0 "Mode1_Off" 1 "Mode1_On" 2 "Mode1_GradualOn" 3 "Mode1_GradualOff" 4 "Mode1_ForwardWipingOn" 5 "Mode1_BackwardWipingOn" 6 "Mode1_OutwardWipingOn" 7 "Mode1_InwardWipingOn" 8 "Mode1_ForwardWipingOff" 9 "Mode1_BackwardWipingOff" 10 "Mode1_OutwardWipingOff" 11 "Mode1_InwardWipingOff" 12 "Mode1_ForwardScanning" 13 "Mode1_BackwardScanning" 14 "Mode1_BreathOn" 15 "Mode1_BreathOff" 16 "Mode1_Spare1" 17 "Mode1_Spare2";
VAL_ 315 DwnLoadDynLtgPrmForLedCornrgLampLeModePrm 0 "Mode1_Off" 1 "Mode1_On" 2 "Mode1_GradualOn" 3 "Mode1_GradualOff" 4 "Mode1_ForwardWipingOn" 5 "Mode1_BackwardWipingOn" 6 "Mode1_OutwardWipingOn" 7 "Mode1_InwardWipingOn" 8 "Mode1_ForwardWipingOff" 9 "Mode1_BackwardWipingOff" 10 "Mode1_OutwardWipingOff" 11 "Mode1_InwardWipingOff" 12 "Mode1_ForwardScanning" 13 "Mode1_BackwardScanning" 14 "Mode1_BreathOn" 15 "Mode1_BreathOff" 16 "Mode1_Spare1" 17 "Mode1_Spare2";
VAL_ 316 DwnLoadDynLtgPrmForLedCornrgLampRiModePrm 0 "Mode1_Off" 1 "Mode1_On" 2 "Mode1_GradualOn" 3 "Mode1_GradualOff" 4 "Mode1_ForwardWipingOn" 5 "Mode1_BackwardWipingOn" 6 "Mode1_OutwardWipingOn" 7 "Mode1_InwardWipingOn" 8 "Mode1_ForwardWipingOff" 9 "Mode1_BackwardWipingOff" 10 "Mode1_OutwardWipingOff" 11 "Mode1_InwardWipingOff" 12 "Mode1_ForwardScanning" 13 "Mode1_BackwardScanning" 14 "Mode1_BreathOn" 15 "Mode1_BreathOff" 16 "Mode1_Spare1" 17 "Mode1_Spare2";
VAL_ 317 DwnLoadDynLtgPrmForLedDaytiRunngLampLeModePrm 0 "Mode1_Off" 1 "Mode1_On" 2 "Mode1_GradualOn" 3 "Mode1_GradualOff" 4 "Mode1_ForwardWipingOn" 5 "Mode1_BackwardWipingOn" 6 "Mode1_OutwardWipingOn" 7 "Mode1_InwardWipingOn" 8 "Mode1_ForwardWipingOff" 9 "Mode1_BackwardWipingOff" 10 "Mode1_OutwardWipingOff" 11 "Mode1_InwardWipingOff" 12 "Mode1_ForwardScanning" 13 "Mode1_BackwardScanning" 14 "Mode1_BreathOn" 15 "Mode1_BreathOff" 16 "Mode1_Spare1" 17 "Mode1_Spare2";
VAL_ 318 DwnLoadDynLtgPrmForLedDaytiRunngLampRiModePrm 0 "Mode1_Off" 1 "Mode1_On" 2 "Mode1_GradualOn" 3 "Mode1_GradualOff" 4 "Mode1_ForwardWipingOn" 5 "Mode1_BackwardWipingOn" 6 "Mode1_OutwardWipingOn" 7 "Mode1_InwardWipingOn" 8 "Mode1_ForwardWipingOff" 9 "Mode1_BackwardWipingOff" 10 "Mode1_OutwardWipingOff" 11 "Mode1_InwardWipingOff" 12 "Mode1_ForwardScanning" 13 "Mode1_BackwardScanning" 14 "Mode1_BreathOn" 15 "Mode1_BreathOff" 16 "Mode1_Spare1" 17 "Mode1_Spare2";
VAL_ 319 DwnLoadDynLtgPrmForLedFrntPosnLampLeModePrm 0 "Mode1_Off" 1 "Mode1_On" 2 "Mode1_GradualOn" 3 "Mode1_GradualOff" 4 "Mode1_ForwardWipingOn" 5 "Mode1_BackwardWipingOn" 6 "Mode1_OutwardWipingOn" 7 "Mode1_InwardWipingOn" 8 "Mode1_ForwardWipingOff" 9 "Mode1_BackwardWipingOff" 10 "Mode1_OutwardWipingOff" 11 "Mode1_InwardWipingOff" 12 "Mode1_ForwardScanning" 13 "Mode1_BackwardScanning" 14 "Mode1_BreathOn" 15 "Mode1_BreathOff" 16 "Mode1_Spare1" 17 "Mode1_Spare2";
VAL_ 320 DwnLoadDynLtgPrmForLedFrntPosnLampRiModePrm 0 "Mode1_Off" 1 "Mode1_On" 2 "Mode1_GradualOn" 3 "Mode1_GradualOff" 4 "Mode1_ForwardWipingOn" 5 "Mode1_BackwardWipingOn" 6 "Mode1_OutwardWipingOn" 7 "Mode1_InwardWipingOn" 8 "Mode1_ForwardWipingOff" 9 "Mode1_BackwardWipingOff" 10 "Mode1_OutwardWipingOff" 11 "Mode1_InwardWipingOff" 12 "Mode1_ForwardScanning" 13 "Mode1_BackwardScanning" 14 "Mode1_BreathOn" 15 "Mode1_BreathOff" 16 "Mode1_Spare1" 17 "Mode1_Spare2";
VAL_ 321 DwnLoadDynLtgPrmForLedFrntTurnIndcrLeModePrm 0 "Mode1_Off" 1 "Mode1_On" 2 "Mode1_GradualOn" 3 "Mode1_GradualOff" 4 "Mode1_ForwardWipingOn" 5 "Mode1_BackwardWipingOn" 6 "Mode1_OutwardWipingOn" 7 "Mode1_InwardWipingOn" 8 "Mode1_ForwardWipingOff" 9 "Mode1_BackwardWipingOff" 10 "Mode1_OutwardWipingOff" 11 "Mode1_InwardWipingOff" 12 "Mode1_ForwardScanning" 13 "Mode1_BackwardScanning" 14 "Mode1_BreathOn" 15 "Mode1_BreathOff" 16 "Mode1_Spare1" 17 "Mode1_Spare2";
VAL_ 322 DwnLoadDynLtgPrmForLedFrntTurnIndcrRiModePrm 0 "Mode1_Off" 1 "Mode1_On" 2 "Mode1_GradualOn" 3 "Mode1_GradualOff" 4 "Mode1_ForwardWipingOn" 5 "Mode1_BackwardWipingOn" 6 "Mode1_OutwardWipingOn" 7 "Mode1_InwardWipingOn" 8 "Mode1_ForwardWipingOff" 9 "Mode1_BackwardWipingOff" 10 "Mode1_OutwardWipingOff" 11 "Mode1_InwardWipingOff" 12 "Mode1_ForwardScanning" 13 "Mode1_BackwardScanning" 14 "Mode1_BreathOn" 15 "Mode1_BreathOff" 16 "Mode1_Spare1" 17 "Mode1_Spare2";
VAL_ 323 DwnLoadDynLtgPrmForLedHiBeamRiModePrm 0 "Mode1_Off" 1 "Mode1_On" 2 "Mode1_GradualOn" 3 "Mode1_GradualOff" 4 "Mode1_ForwardWipingOn" 5 "Mode1_BackwardWipingOn" 6 "Mode1_OutwardWipingOn" 7 "Mode1_InwardWipingOn" 8 "Mode1_ForwardWipingOff" 9 "Mode1_BackwardWipingOff" 10 "Mode1_OutwardWipingOff" 11 "Mode1_InwardWipingOff" 12 "Mode1_ForwardScanning" 13 "Mode1_BackwardScanning" 14 "Mode1_BreathOn" 15 "Mode1_BreathOff" 16 "Mode1_Spare1" 17 "Mode1_Spare2";
VAL_ 381 ActnOfLedFrntCrossLampDyn 0 "OnOff1_Off" 1 "OnOff1_On";
VAL_ 381 ActnOfLedGrilleLampDyn 0 "OnOff1_Off" 1 "OnOff1_On";
VAL_ 381 ActnOfLedLeLogoLampDyn 0 "OnOff1_Off" 1 "OnOff1_On";
VAL_ 381 ActnOfLedPosnLampDyn 0 "OnOff1_Off" 1 "OnOff1_On";
VAL_ 381 ActnOfLedRiLogoLampDyn 0 "OnOff1_Off" 1 "OnOff1_On";
VAL_ 381 ActvnOfHomeSafe 0 "OnOff1_Off" 1 "OnOff1_On";
VAL_ 612 ActvnOfApproach 0 "OnOff1_Off" 1 "OnOff1_On";
VAL_ 612 ActvnOfCarLoctr 0 "OnOff1_Off" 1 "OnOff1_On";
VAL_ 612 ActvnOfReLogoLamp 0 "OnOff1_Off" 1 "OnOff1_On";
VAL_ 612 ActvnOfSayHi 0 "OnOff1_Off" 1 "OnOff1_On";
VAL_ 612 ActvnOfWaitMode 0 "OnOff1_Off" 1 "OnOff1_On";
VAL_ 612 BrkPedlValQf 0 "GenQf1_UndefindDataAccur" 1 "GenQf1_TmpUndefdData" 2 "GenQf1_DataAccurNotWithinSpcn" 3 "GenQf1_AccurData";
VAL_ 612 CinhDrvrSts 0 "Boolean_FALSE" 1 "Boolean_TRUE";
VAL_ 612 CinhDrvrSwt 0 "PsdNotPsd1_NotPsd" 1 "PsdNotPsd1_Psd";
VAL_ 612 CinhLeReSts 0 "PsdNotPsd1_NotPsd" 1 "PsdNotPsd1_Psd";
VAL_ 612 CinhLeReSwt 0 "PsdNotPsd1_NotPsd" 1 "PsdNotPsd1_Psd";
VAL_ 612 CinhPassSts 0 "Boolean_FALSE" 1 "Boolean_TRUE";
VAL_ 612 CinhPassSwt 0 "PsdNotPsd1_NotPsd" 1 "PsdNotPsd1_Psd";
VAL_ 612 CinhRiReSts 0 "PsdNotPsd1_NotPsd" 1 "PsdNotPsd1_Psd";
VAL_ 612 CinhRiReSwt 0 "PsdNotPsd1_NotPsd" 1 "PsdNotPsd1_Psd";
VAL_ 612 HmiHvacFanLvlFrnt 0 "HmiHvacFanLvl_Off" 1 "HmiHvacFanLvl_LvlMan1" 2 "HmiHvacFanLvl_LvlMan2" 3 "HmiHvacFanLvl_LvlMan3" 4 "HmiHvacFanLvl_LvlMan4" 5 "HmiHvacFanLvl_LvlMan5" 6 "HmiHvacFanLvl_LvlMan6" 7 "HmiHvacFanLvl_LvlMan7" 8 "HmiHvacFanLvl_LvlMan8" 9 "HmiHvacFanLvl_LvlMan9" 10 "HmiHvacFanLvl_LvlAutMinusMinus" 11 "HmiHvacFanLvl_LvlAutMinus" 12 "HmiHvacFanLvl_LvlAutNorm" 13 "HmiHvacFanLvl_LvlAutPlus" 14 "HmiHvacFanLvl_LvlAutPlusPlus" 15 "HmiHvacFanLvl_Reserved";
VAL_ 612 IndcrNoSeq 0 "OnOff1_Off" 1 "OnOff1_On";
VAL_ 612 LitArea 0 "NoYes1_No" 1 "NoYes1_Yes";
VAL_ 612 ReLePwrDoorManStrengthLvl 0 "SelectLvl_Idle" 1 "SelectLvl_Level1" 2 "SelectLvl_Level2" 3 "SelectLvl_Level3";
VAL_ 612 WipgInfoWipgSpdInfo 0 "WipgSpdInfo_Off" 1 "WipgSpdInfo_IntlLo" 2 "WipgSpdInfo_IntlHi" 3 "WipgSpdInfo_WipgSpd4045" 4 "WipgSpdInfo_WipgSpd4650" 5 "WipgSpdInfo_WipgSpd5155" 6 "WipgSpdInfo_WipgSpd5660" 7 "WipgSpdInfo_WiprErr";
VAL_ 612 WipgInfoWiprActv 0 "OnOff1_Off" 1 "OnOff1_On";
VAL_ 612 WipgInfoWiprInWipgAr 0 "OnOff1_Off" 1 "OnOff1_On";
VAL_ 324 DwnLoadDynLitPrmForLedMkrLampRi2ModePrm 0 "Mode1_Off" 1 "Mode1_On" 2 "Mode1_GradualOn" 3 "Mode1_GradualOff" 4 "Mode1_ForwardWipingOn" 5 "Mode1_BackwardWipingOn" 6 "Mode1_OutwardWipingOn" 7 "Mode1_InwardWipingOn" 8 "Mode1_ForwardWipingOff" 9 "Mode1_BackwardWipingOff" 10 "Mode1_OutwardWipingOff" 11 "Mode1_InwardWipingOff" 12 "Mode1_ForwardScanning" 13 "Mode1_BackwardScanning" 14 "Mode1_BreathOn" 15 "Mode1_BreathOff" 16 "Mode1_Spare1" 17 "Mode1_Spare2";
VAL_ 325 DwnLoadDynLitPrmLedRvsgLampRi2ModePrm 0 "Mode1_Off" 1 "Mode1_On" 2 "Mode1_GradualOn" 3 "Mode1_GradualOff" 4 "Mode1_ForwardWipingOn" 5 "Mode1_BackwardWipingOn" 6 "Mode1_OutwardWipingOn" 7 "Mode1_InwardWipingOn" 8 "Mode1_ForwardWipingOff" 9 "Mode1_BackwardWipingOff" 10 "Mode1_OutwardWipingOff" 11 "Mode1_InwardWipingOff" 12 "Mode1_ForwardScanning" 13 "Mode1_BackwardScanning" 14 "Mode1_BreathOn" 15 "Mode1_BreathOff" 16 "Mode1_Spare1" 17 "Mode1_Spare2";
VAL_ 522 ActnOfLedCornrgLampLe 0 "OnOff1_Off" 1 "OnOff1_On";
VAL_ 522 ActnOfLedCornrgLampRi 0 "OnOff1_Off" 1 "OnOff1_On";
VAL_ 522 ActnOfLedDaytiRunngLamp 0 "OnOff1_Off" 1 "OnOff1_On";
VAL_ 522 ActnOfLedFrntFogLamp 0 "OnOff1_Off" 1 "OnOff1_On";
VAL_ 522 ActnOfLedHiBeam 0 "OnOff1_Off" 1 "OnOff1_On";
VAL_ 522 ActnOfLedLoBeamActnOfLedLoBeam 0 "OnOff1_Off" 1 "OnOff1_On";
VAL_ 522 ActnOfLedPosnLamp 0 "OnOff1_Off" 1 "OnOff1_On";
VAL_ 522 ActnOfLedReFogLamp 0 "OnOff1_Off" 1 "OnOff1_On";
VAL_ 522 ActnOfLedRePosnLamp 0 "OnOff1_Off" 1 "OnOff1_On";
VAL_ 522 ActnOfLedRvsgLamp 0 "OnOff1_Off" 1 "OnOff1_On";
VAL_ 522 ActnOfLedStopLampActnOfLedStopLamp 0 "OnOff1_Off" 1 "OnOff1_On";
VAL_ 522 ActvnOfAfs 0 "OnOff1_Off" 1 "OnOff1_On";
VAL_ 522 ActvnOfAhbc 0 "OnOff1_Off" 1 "OnOff1_On";
VAL_ 522 ActvnOfAhl 0 "OnOff1_Off" 1 "OnOff1_On";
VAL_ 522 ActvnOfBrkLi 0 "OnOff1_Off" 1 "OnOff1_On";
VAL_ 522 ActvnOfDbl 0 "OnOff1_Off" 1 "OnOff1_On";
VAL_ 522 ActvnOfGoodByeLi 0 "OnOff1_Off" 1 "OnOff1_On";
VAL_ 522 ActvnOfTouristMod 0 "OnOff1_Off" 1 "OnOff1_On";
VAL_ 522 ActvnOfWelcomeLi 0 "OnOff1_Off" 1 "OnOff1_On";
VAL_ 538 ActvnOfIndcrIndcrOut 0 "IndcrSts1_Off" 1 "IndcrSts1_LeOn" 2 "IndcrSts1_RiOn" 3 "IndcrSts1_LeAndRiOn";
VAL_ 538 DoorLeReAutoManReq 0 "OnOffNoReq_NoReq" 1 "OnOffNoReq_On" 2 "OnOffNoReq_Off";
VAL_ 538 DoorPassAutoManReq 0 "OnOffNoReq_NoReq" 1 "OnOffNoReq_On" 2 "OnOffNoReq_Off";
VAL_ 538 DoorRiReAutoManReq 0 "OnOffNoReq_NoReq" 1 "OnOffNoReq_On" 2 "OnOffNoReq_Off";
VAL_ 538 EmgyBrkLiIndcrTurn 0 "OnOffCrit1_NotVld1" 1 "OnOffCrit1_Off" 2 "OnOffCrit1_On" 3 "OnOffCrit1_NotVld2";
VAL_ 538 IndcrSts 0 "IndcrSts1_Off" 1 "IndcrSts1_LeOn" 2 "IndcrSts1_RiOn" 3 "IndcrSts1_LeAndRiOn";
VAL_ 326 DwnLoadDynLitPrmForLedLogoLampModePrm 0 "Mode1_Off" 1 "Mode1_On" 2 "Mode1_GradualOn" 3 "Mode1_GradualOff" 4 "Mode1_ForwardWipingOn" 5 "Mode1_BackwardWipingOn" 6 "Mode1_OutwardWipingOn" 7 "Mode1_InwardWipingOn" 8 "Mode1_ForwardWipingOff" 9 "Mode1_BackwardWipingOff" 10 "Mode1_OutwardWipingOff" 11 "Mode1_InwardWipingOff" 12 "Mode1_ForwardScanning" 13 "Mode1_BackwardScanning" 14 "Mode1_BreathOn" 15 "Mode1_BreathOff" 16 "Mode1_Spare1" 17 "Mode1_Spare2";
VAL_ 327 DwnLoadDynLitPrmLedRePosnLampLe3ModePrm 0 "Mode1_Off" 1 "Mode1_On" 2 "Mode1_GradualOn" 3 "Mode1_GradualOff" 4 "Mode1_ForwardWipingOn" 5 "Mode1_BackwardWipingOn" 6 "Mode1_OutwardWipingOn" 7 "Mode1_InwardWipingOn" 8 "Mode1_ForwardWipingOff" 9 "Mode1_BackwardWipingOff" 10 "Mode1_OutwardWipingOff" 11 "Mode1_InwardWipingOff" 12 "Mode1_ForwardScanning" 13 "Mode1_BackwardScanning" 14 "Mode1_BreathOn" 15 "Mode1_BreathOff" 16 "Mode1_Spare1" 17 "Mode1_Spare2";
VAL_ 328 DwnLoadDynLitPrmLedRePosnLampLe4ModePrm 0 "Mode1_Off" 1 "Mode1_On" 2 "Mode1_GradualOn" 3 "Mode1_GradualOff" 4 "Mode1_ForwardWipingOn" 5 "Mode1_BackwardWipingOn" 6 "Mode1_OutwardWipingOn" 7 "Mode1_InwardWipingOn" 8 "Mode1_ForwardWipingOff" 9 "Mode1_BackwardWipingOff" 10 "Mode1_OutwardWipingOff" 11 "Mode1_InwardWipingOff" 12 "Mode1_ForwardScanning" 13 "Mode1_BackwardScanning" 14 "Mode1_BreathOn" 15 "Mode1_BreathOff" 16 "Mode1_Spare1" 17 "Mode1_Spare2";
VAL_ 329 DwnLoadDynLitPrmLedRePosnLampLe5ModePrm 0 "Mode1_Off" 1 "Mode1_On" 2 "Mode1_GradualOn" 3 "Mode1_GradualOff" 4 "Mode1_ForwardWipingOn" 5 "Mode1_BackwardWipingOn" 6 "Mode1_OutwardWipingOn" 7 "Mode1_InwardWipingOn" 8 "Mode1_ForwardWipingOff" 9 "Mode1_BackwardWipingOff" 10 "Mode1_OutwardWipingOff" 11 "Mode1_InwardWipingOff" 12 "Mode1_ForwardScanning" 13 "Mode1_BackwardScanning" 14 "Mode1_BreathOn" 15 "Mode1_BreathOff" 16 "Mode1_Spare1" 17 "Mode1_Spare2";
VAL_ 330 DwnLoadDynLitPrmLedRePosnLampRi3ModePrm 0 "Mode1_Off" 1 "Mode1_On" 2 "Mode1_GradualOn" 3 "Mode1_GradualOff" 4 "Mode1_ForwardWipingOn" 5 "Mode1_BackwardWipingOn" 6 "Mode1_OutwardWipingOn" 7 "Mode1_InwardWipingOn" 8 "Mode1_ForwardWipingOff" 9 "Mode1_BackwardWipingOff" 10 "Mode1_OutwardWipingOff" 11 "Mode1_InwardWipingOff" 12 "Mode1_ForwardScanning" 13 "Mode1_BackwardScanning" 14 "Mode1_BreathOn" 15 "Mode1_BreathOff" 16 "Mode1_Spare1" 17 "Mode1_Spare2";
VAL_ 331 DwnLoadDynLitPrmLedRePosnLampRi4ModePrm 0 "Mode1_Off" 1 "Mode1_On" 2 "Mode1_GradualOn" 3 "Mode1_GradualOff" 4 "Mode1_ForwardWipingOn" 5 "Mode1_BackwardWipingOn" 6 "Mode1_OutwardWipingOn" 7 "Mode1_InwardWipingOn" 8 "Mode1_ForwardWipingOff" 9 "Mode1_BackwardWipingOff" 10 "Mode1_OutwardWipingOff" 11 "Mode1_InwardWipingOff" 12 "Mode1_ForwardScanning" 13 "Mode1_BackwardScanning" 14 "Mode1_BreathOn" 15 "Mode1_BreathOff" 16 "Mode1_Spare1" 17 "Mode1_Spare2";
VAL_ 332 DwnLoadDynLitPrmLedRePosnLampRi5ModePrm 0 "Mode1_Off" 1 "Mode1_On" 2 "Mode1_GradualOn" 3 "Mode1_GradualOff" 4 "Mode1_ForwardWipingOn" 5 "Mode1_BackwardWipingOn" 6 "Mode1_OutwardWipingOn" 7 "Mode1_InwardWipingOn" 8 "Mode1_ForwardWipingOff" 9 "Mode1_BackwardWipingOff" 10 "Mode1_OutwardWipingOff" 11 "Mode1_InwardWipingOff" 12 "Mode1_ForwardScanning" 13 "Mode1_BackwardScanning" 14 "Mode1_BreathOn" 15 "Mode1_BreathOff" 16 "Mode1_Spare1" 17 "Mode1_Spare2";
VAL_ 24 DoorDrvrSts 0 "DoorSts2_Ukwn" 1 "DoorSts2_Opend" 2 "DoorSts2_Clsd";
VAL_ 24 DoorLeReSts 0 "DoorSts2_Ukwn" 1 "DoorSts2_Opend" 2 "DoorSts2_Clsd";
VAL_ 24 DoorOpenwarnLeIndcn 0 "LcmaIndcn_NoLcmaWarn" 1 "LcmaIndcn_LcmaWarnLvl1" 2 "LcmaIndcn_NotUsed" 3 "LcmaIndcn_LcmaWarnLvl2";
VAL_ 24 DoorOpenwarnOn1 0 "LcmaCtraOn_Off" 1 "LcmaCtraOn_Passive" 2 "LcmaCtraOn_Active" 3 "LcmaCtraOn_TrlrOff";
VAL_ 24 DoorOpenwarnRiIndcn 0 "LcmaIndcn_NoLcmaWarn" 1 "LcmaIndcn_LcmaWarnLvl1" 2 "LcmaIndcn_NotUsed" 3 "LcmaIndcn_LcmaWarnLvl2";
VAL_ 24 GrilleLampColorSelnReq 0 "SteerMod_Ukwn" 1 "SteerMod_Mod1" 2 "SteerMod_Mod2" 3 "SteerMod_Mod3" 4 "SteerMod_Mod4" 5 "SteerMod_Resd5" 6 "SteerMod_Resd6" 7 "SteerMod_Resd7";
VAL_ 24 PassPwrDoorManStrengthLvl 0 "SelectLvl_Idle" 1 "SelectLvl_Level1" 2 "SelectLvl_Level2" 3 "SelectLvl_Level3";
VAL_ 24 WelcomeGoodbyeModeReq 0 "ModeReq_Mode1" 1 "ModeReq_Mode2" 2 "ModeReq_Mode3" 3 "ModeReq_Mode4" 4 "ModeReq_Mode5" 5 "ModeReq_Mode6";
VAL_ 333 DwnLoadDynLitPrmLedLeGrilleLampModePrm 0 "Mode1_Off" 1 "Mode1_On" 2 "Mode1_GradualOn" 3 "Mode1_GradualOff" 4 "Mode1_ForwardWipingOn" 5 "Mode1_BackwardWipingOn" 6 "Mode1_OutwardWipingOn" 7 "Mode1_InwardWipingOn" 8 "Mode1_ForwardWipingOff" 9 "Mode1_BackwardWipingOff" 10 "Mode1_OutwardWipingOff" 11 "Mode1_InwardWipingOff" 12 "Mode1_ForwardScanning" 13 "Mode1_BackwardScanning" 14 "Mode1_BreathOn" 15 "Mode1_BreathOff" 16 "Mode1_Spare1" 17 "Mode1_Spare2";
VAL_ 334 DwnLoadDynLitPrmLedRiGrilleLampModePrm 0 "Mode1_Off" 1 "Mode1_On" 2 "Mode1_GradualOn" 3 "Mode1_GradualOff" 4 "Mode1_ForwardWipingOn" 5 "Mode1_BackwardWipingOn" 6 "Mode1_OutwardWipingOn" 7 "Mode1_InwardWipingOn" 8 "Mode1_ForwardWipingOff" 9 "Mode1_BackwardWipingOff" 10 "Mode1_OutwardWipingOff" 11 "Mode1_InwardWipingOff" 12 "Mode1_ForwardScanning" 13 "Mode1_BackwardScanning" 14 "Mode1_BreathOn" 15 "Mode1_BreathOff" 16 "Mode1_Spare1" 17 "Mode1_Spare2";
VAL_ 788 DHUcontrolLedMkrLampLe1 0 "OnOffNoReq_NoReq" 1 "OnOffNoReq_On" 2 "OnOffNoReq_Off";
VAL_ 788 DHUcontrolLedMkrLampLe2 0 "OnOffNoReq_NoReq" 1 "OnOffNoReq_On" 2 "OnOffNoReq_Off";
VAL_ 788 DHUcontrolLedMkrLampRi1 0 "OnOffNoReq_NoReq" 1 "OnOffNoReq_On" 2 "OnOffNoReq_Off";
VAL_ 788 DHUcontrolLedMkrLampRi2 0 "OnOffNoReq_NoReq" 1 "OnOffNoReq_On" 2 "OnOffNoReq_Off";
VAL_ 788 DHUcontrolLedStopLampLe1 0 "OnOffNoReq_NoReq" 1 "OnOffNoReq_On" 2 "OnOffNoReq_Off";
VAL_ 788 DHUcontrolLedStopLampLe2 0 "OnOffNoReq_NoReq" 1 "OnOffNoReq_On" 2 "OnOffNoReq_Off";
VAL_ 788 DHUcontrolLedStopLampRi1 0 "OnOffNoReq_NoReq" 1 "OnOffNoReq_On" 2 "OnOffNoReq_Off";
VAL_ 788 DHUcontrolLedStopLampRi2 0 "OnOffNoReq_NoReq" 1 "OnOffNoReq_On" 2 "OnOffNoReq_Off";
VAL_ 788 DHUcontrolmiddlebrakelight 0 "OnOffNoReq_NoReq" 1 "OnOffNoReq_On" 2 "OnOffNoReq_Off";
VAL_ 788 DHUcontrolmiddlecorneringlamp 0 "OnOffNoReq_NoReq" 1 "OnOffNoReq_On" 2 "OnOffNoReq_Off";
VAL_ 788 DHUcontrolmiddlepositionlight 0 "OnOffNoReq_NoReq" 1 "OnOffNoReq_On" 2 "OnOffNoReq_Off";
SIG_GROUP_ 522 ActnOfLedLoBeam 1 : ActnOfLedLoBeamActnOfLedLoBeam ActnOfLedLoBeamChks ActnOfLedLoBeamCntr;
SIG_GROUP_ 522 ActnOfLedStopLamp 1 : ActnOfLedStopLampActnOfLedStopLamp ActnOfLedStopLampChks ActnOfLedStopLampCntr;
SIG_GROUP_ 538 ActvnOfIndcr 1 : ActvnOfIndcrIndcrOut ActvnOfIndcrIndcrOutChks ActvnOfIndcrIndcrOutCntr;
SIG_GROUP_ 612 BrkPedlVal 1 : BrkPedlValBrkPedlVal BrkPedlValQf;
SIG_GROUP_ 359 CarpetLiSet 1 : CarpetLiSetCarpetLiSet CarpetLiSetPerc12;
SIG_GROUP_ 359 CarpetLiTrialSet 1 : CarpetLiTrialSetPerc12 CarpetLiTrialSetTrialSet;
SIG_GROUP_ 360 DoorOpenerPassReq 1 : DoorOpenerPassReqChks DoorOpenerPassReqCntr DoorOpenerPassReqDoorOpenerReq DoorOpenerPassReqTrigSrc;
SIG_GROUP_ 360 DoorOpenerRiReReq 1 : DoorOpenerRiReReqChks DoorOpenerRiReReqCntr DoorOpenerRiReReqDoorOpenerReq DoorOpenerRiReReqTrigSrc;
SIG_GROUP_ 311 DwnLoadDynLitPrmForLedHiBeamLe 1 : DwnLoadDynLitPrmForLedHiBeamLeContTiPrm DwnLoadDynLitPrmForLedHiBeamLeLowBriPrm DwnLoadDynLitPrmForLedHiBeamLeModePrm DwnLoadDynLitPrmForLedHiBeamLeOffsTiPrm DwnLoadDynLitPrmForLedHiBeamLeTistamp DwnLoadDynLitPrmForLedHiBeamLeUpprBriPrm;
SIG_GROUP_ 312 DwnLoadDynLitPrmForLedLoBeamLe 1 : DwnLoadDynLitPrmForLedLoBeamLeContTiPrm DwnLoadDynLitPrmForLedLoBeamLeLowBriPrm DwnLoadDynLitPrmForLedLoBeamLeModePrm DwnLoadDynLitPrmForLedLoBeamLeOffsTiPrm DwnLoadDynLitPrmForLedLoBeamLeTistamp DwnLoadDynLitPrmForLedLoBeamLeUpprBriPrm;
SIG_GROUP_ 326 DwnLoadDynLitPrmForLedLogoLamp 1 : DwnLoadDynLitPrmForLedLogoLampContTiPrm DwnLoadDynLitPrmForLedLogoLampLowBriPrm DwnLoadDynLitPrmForLedLogoLampModePrm DwnLoadDynLitPrmForLedLogoLampOffsTiPrm DwnLoadDynLitPrmForLedLogoLampTistamp DwnLoadDynLitPrmForLedLogoLampUpprBriPrm;
SIG_GROUP_ 324 DwnLoadDynLitPrmForLedMkrLampRi2 1 : DwnLoadDynLitPrmForLedMkrLampRi2ContTiPrm DwnLoadDynLitPrmForLedMkrLampRi2LowBriPrm DwnLoadDynLitPrmForLedMkrLampRi2ModePrm DwnLoadDynLitPrmForLedMkrLampRi2OffsTiPrm DwnLoadDynLitPrmForLedMkrLampRi2Tistamp DwnLoadDynLitPrmForLedMkrLampRi2UpprBriPrm;
SIG_GROUP_ 298 DwnLoadDynLitPrmForLedStopLampRi1 1 : DwnLoadDynLitPrmForLedStopLampRi1ContTiPrm DwnLoadDynLitPrmForLedStopLampRi1LowBriPrm DwnLoadDynLitPrmForLedStopLampRi1ModePrm DwnLoadDynLitPrmForLedStopLampRi1OffsTiPrm DwnLoadDynLitPrmForLedStopLampRi1Tistamp DwnLoadDynLitPrmForLedStopLampRi1UpprBriPrm;
SIG_GROUP_ 333 DwnLoadDynLitPrmLedLeGrilleLamp 1 : DwnLoadDynLitPrmLedLeGrilleLampContTiPrm DwnLoadDynLitPrmLedLeGrilleLampLowBriPrm DwnLoadDynLitPrmLedLeGrilleLampModePrm DwnLoadDynLitPrmLedLeGrilleLampOffsTiPrm DwnLoadDynLitPrmLedLeGrilleLampTistamp DwnLoadDynLitPrmLedLeGrilleLampUpprBriPrm;
SIG_GROUP_ 299 DwnLoadDynLitPrmLedReFogLampLe1 1 : DwnLoadDynLitPrmLedReFogLampLe1ContTiPrm DwnLoadDynLitPrmLedReFogLampLe1LowBriPrm DwnLoadDynLitPrmLedReFogLampLe1ModePrm DwnLoadDynLitPrmLedReFogLampLe1OffsTiPrm DwnLoadDynLitPrmLedReFogLampLe1Tistamp DwnLoadDynLitPrmLedReFogLampLe1UpprBriPrm;
SIG_GROUP_ 300 DwnLoadDynLitPrmLedReFogLampLe2 1 : DwnLoadDynLitPrmLedReFogLampLe2ContTiPrm DwnLoadDynLitPrmLedReFogLampLe2LowBriPrm DwnLoadDynLitPrmLedReFogLampLe2ModePrm DwnLoadDynLitPrmLedReFogLampLe2OffsTiPrm DwnLoadDynLitPrmLedReFogLampLe2Tistamp DwnLoadDynLitPrmLedReFogLampLe2UpprBriPrm;
SIG_GROUP_ 301 DwnLoadDynLitPrmLedReFogLampRi1 1 : DwnLoadDynLitPrmLedReFogLampRi1ContTiPrm DwnLoadDynLitPrmLedReFogLampRi1LowBriPrm DwnLoadDynLitPrmLedReFogLampRi1ModePrm DwnLoadDynLitPrmLedReFogLampRi1OffsTiPrm DwnLoadDynLitPrmLedReFogLampRi1Tistamp DwnLoadDynLitPrmLedReFogLampRi1UpprBriPrm;
SIG_GROUP_ 302 DwnLoadDynLitPrmLedRePosnLampLe1 1 : DwnLoadDynLitPrmLedRePosnLampLe1ContTiPrm DwnLoadDynLitPrmLedRePosnLampLe1LowBriPrm DwnLoadDynLitPrmLedRePosnLampLe1ModePrm DwnLoadDynLitPrmLedRePosnLampLe1OffsTiPrm DwnLoadDynLitPrmLedRePosnLampLe1Tistamp DwnLoadDynLitPrmLedRePosnLampLe1UpprBriPrm;
SIG_GROUP_ 303 DwnLoadDynLitPrmLedRePosnLampLe2 1 : DwnLoadDynLitPrmLedRePosnLampLe2ContTiPrm DwnLoadDynLitPrmLedRePosnLampLe2LowBriPrm DwnLoadDynLitPrmLedRePosnLampLe2ModePrm DwnLoadDynLitPrmLedRePosnLampLe2OffsTiPrm DwnLoadDynLitPrmLedRePosnLampLe2Tistamp DwnLoadDynLitPrmLedRePosnLampLe2UpprBriPrm;
SIG_GROUP_ 327 DwnLoadDynLitPrmLedRePosnLampLe3 1 : DwnLoadDynLitPrmLedRePosnLampLe3ContTiPrm DwnLoadDynLitPrmLedRePosnLampLe3LowBriPrm DwnLoadDynLitPrmLedRePosnLampLe3ModePrm DwnLoadDynLitPrmLedRePosnLampLe3OffsTiPrm DwnLoadDynLitPrmLedRePosnLampLe3Tistamp DwnLoadDynLitPrmLedRePosnLampLe3UpprBriPrm;
SIG_GROUP_ 328 DwnLoadDynLitPrmLedRePosnLampLe4 1 : DwnLoadDynLitPrmLedRePosnLampLe4ContTiPrm DwnLoadDynLitPrmLedRePosnLampLe4LowBriPrm DwnLoadDynLitPrmLedRePosnLampLe4ModePrm DwnLoadDynLitPrmLedRePosnLampLe4OffsTiPrm DwnLoadDynLitPrmLedRePosnLampLe4Tistamp DwnLoadDynLitPrmLedRePosnLampLe4UpprBriPrm;
SIG_GROUP_ 329 DwnLoadDynLitPrmLedRePosnLampLe5 1 : DwnLoadDynLitPrmLedRePosnLampLe5ContTiPrm DwnLoadDynLitPrmLedRePosnLampLe5LowBriPrm DwnLoadDynLitPrmLedRePosnLampLe5ModePrm DwnLoadDynLitPrmLedRePosnLampLe5OffsTiPrm DwnLoadDynLitPrmLedRePosnLampLe5Tistamp DwnLoadDynLitPrmLedRePosnLampLe5UpprBriPrm;
SIG_GROUP_ 304 DwnLoadDynLitPrmLedRePosnLampRi1 1 : DwnLoadDynLitPrmLedRePosnLampRi1ContTiPrm DwnLoadDynLitPrmLedRePosnLampRi1LowBriPrm DwnLoadDynLitPrmLedRePosnLampRi1ModePrm DwnLoadDynLitPrmLedRePosnLampRi1OffsTiPrm DwnLoadDynLitPrmLedRePosnLampRi1Tistamp DwnLoadDynLitPrmLedRePosnLampRi1UpprBriPrm;
SIG_GROUP_ 330 DwnLoadDynLitPrmLedRePosnLampRi3 1 : DwnLoadDynLitPrmLedRePosnLampRi3ContTiPrm DwnLoadDynLitPrmLedRePosnLampRi3LowBriPrm DwnLoadDynLitPrmLedRePosnLampRi3ModePrm DwnLoadDynLitPrmLedRePosnLampRi3OffsTiPrm DwnLoadDynLitPrmLedRePosnLampRi3Tistamp DwnLoadDynLitPrmLedRePosnLampRi3UpprBriPrm;
SIG_GROUP_ 331 DwnLoadDynLitPrmLedRePosnLampRi4 1 : DwnLoadDynLitPrmLedRePosnLampRi4ContTiPrm DwnLoadDynLitPrmLedRePosnLampRi4LowBriPrm DwnLoadDynLitPrmLedRePosnLampRi4ModePrm DwnLoadDynLitPrmLedRePosnLampRi4OffsTiPrm DwnLoadDynLitPrmLedRePosnLampRi4Tistamp DwnLoadDynLitPrmLedRePosnLampRi4UpprBriPrm;
SIG_GROUP_ 332 DwnLoadDynLitPrmLedRePosnLampRi5 1 : DwnLoadDynLitPrmLedRePosnLampRi5ContTiPrm DwnLoadDynLitPrmLedRePosnLampRi5LowBriPrm DwnLoadDynLitPrmLedRePosnLampRi5ModePrm DwnLoadDynLitPrmLedRePosnLampRi5OffsTiPrm DwnLoadDynLitPrmLedRePosnLampRi5Tistamp DwnLoadDynLitPrmLedRePosnLampRi5UpprBriPrm;
SIG_GROUP_ 305 DwnLoadDynLitPrmLedReTurnIndcrLe1 1 : DwnLoadDynLitPrmLedReTurnIndcrLe1ContTiPrm DwnLoadDynLitPrmLedReTurnIndcrLe1LowBriPrm DwnLoadDynLitPrmLedReTurnIndcrLe1ModePrm DwnLoadDynLitPrmLedReTurnIndcrLe1OffsTiPrm DwnLoadDynLitPrmLedReTurnIndcrLe1Tistamp DwnLoadDynLitPrmLedReTurnIndcrLe1UpprBriPrm;
SIG_GROUP_ 306 DwnLoadDynLitPrmLedReTurnIndcrLe2 1 : DwnLoadDynLitPrmLedReTurnIndcrLe2ContTiPrm DwnLoadDynLitPrmLedReTurnIndcrLe2LowBriPrm DwnLoadDynLitPrmLedReTurnIndcrLe2ModePrm DwnLoadDynLitPrmLedReTurnIndcrLe2OffsTiPrm DwnLoadDynLitPrmLedReTurnIndcrLe2Tistamp DwnLoadDynLitPrmLedReTurnIndcrLe2UpprBriPrm;
SIG_GROUP_ 307 DwnLoadDynLitPrmLedReTurnIndcrRi1 1 : DwnLoadDynLitPrmLedReTurnIndcrRi1ContTiPrm DwnLoadDynLitPrmLedReTurnIndcrRi1LowBriPrm DwnLoadDynLitPrmLedReTurnIndcrRi1ModePrm DwnLoadDynLitPrmLedReTurnIndcrRi1OffsTiPrm DwnLoadDynLitPrmLedReTurnIndcrRi1Tistamp DwnLoadDynLitPrmLedReTurnIndcrRi1UpprBriPrm;
SIG_GROUP_ 334 DwnLoadDynLitPrmLedRiGrilleLamp 1 : DwnLoadDynLitPrmLedRiGrilleLampContTiPrm DwnLoadDynLitPrmLedRiGrilleLampLowBriPrm DwnLoadDynLitPrmLedRiGrilleLampModePrm DwnLoadDynLitPrmLedRiGrilleLampOffsTiPrm DwnLoadDynLitPrmLedRiGrilleLampTistamp DwnLoadDynLitPrmLedRiGrilleLampUpprBriPrm;
SIG_GROUP_ 308 DwnLoadDynLitPrmLedRvsgLampLe1 1 : DwnLoadDynLitPrmLedRvsgLampLe1ContTiPrm DwnLoadDynLitPrmLedRvsgLampLe1LowBriPrm DwnLoadDynLitPrmLedRvsgLampLe1ModePrm DwnLoadDynLitPrmLedRvsgLampLe1OffsTiPrm DwnLoadDynLitPrmLedRvsgLampLe1Tistamp DwnLoadDynLitPrmLedRvsgLampLe1UpprBriPrm;
SIG_GROUP_ 309 DwnLoadDynLitPrmLedRvsgLampLe2 1 : DwnLoadDynLitPrmLedRvsgLampLe2ContTiPrm DwnLoadDynLitPrmLedRvsgLampLe2LowBriPrm DwnLoadDynLitPrmLedRvsgLampLe2ModePrm DwnLoadDynLitPrmLedRvsgLampLe2OffsTiPrm DwnLoadDynLitPrmLedRvsgLampLe2Tistamp DwnLoadDynLitPrmLedRvsgLampLe2UpprBriPrm;
SIG_GROUP_ 310 DwnLoadDynLitPrmLedRvsgLampRi1 1 : DwnLoadDynLitPrmLedRvsgLampRi1ContTiPrm DwnLoadDynLitPrmLedRvsgLampRi1LowBriPrm DwnLoadDynLitPrmLedRvsgLampRi1ModePrm DwnLoadDynLitPrmLedRvsgLampRi1OffsTiPrm DwnLoadDynLitPrmLedRvsgLampRi1Tistamp DwnLoadDynLitPrmLedRvsgLampRi1UpprBriPrm;
SIG_GROUP_ 325 DwnLoadDynLitPrmLedRvsgLampRi2 1 : DwnLoadDynLitPrmLedRvsgLampRi2ContTiPrm DwnLoadDynLitPrmLedRvsgLampRi2LowBriPrm DwnLoadDynLitPrmLedRvsgLampRi2ModePrm DwnLoadDynLitPrmLedRvsgLampRi2OffsTiPrm DwnLoadDynLitPrmLedRvsgLampRi2Tistamp DwnLoadDynLitPrmLedRvsgLampRi2UpprBriPrm;
SIG_GROUP_ 313 DwnLoadDynLtgPrmForLedAllWthrLampLe 1 : DwnLoadDynLtgPrmForLedAllWthrLampLeContTiPrm DwnLoadDynLtgPrmForLedAllWthrLampLeLowBriPrm DwnLoadDynLtgPrmForLedAllWthrLampLeModePrm DwnLoadDynLtgPrmForLedAllWthrLampLeOffsTiPrm DwnLoadDynLtgPrmForLedAllWthrLampLeTistamp DwnLoadDynLtgPrmForLedAllWthrLampLeUpprBriPrm;
SIG_GROUP_ 314 DwnLoadDynLtgPrmForLedAllWthrLampRi 1 : DwnLoadDynLtgPrmForLedAllWthrLampRiContTiPrm DwnLoadDynLtgPrmForLedAllWthrLampRiLowBriPrm DwnLoadDynLtgPrmForLedAllWthrLampRiModePrm DwnLoadDynLtgPrmForLedAllWthrLampRiOffsTiPrm DwnLoadDynLtgPrmForLedAllWthrLampRiTistamp DwnLoadDynLtgPrmForLedAllWthrLampRiUpprBriPrm;
SIG_GROUP_ 315 DwnLoadDynLtgPrmForLedCornrgLampLe 1 : DwnLoadDynLtgPrmForLedCornrgLampLeContTiPrm DwnLoadDynLtgPrmForLedCornrgLampLeLowBriPrm DwnLoadDynLtgPrmForLedCornrgLampLeModePrm DwnLoadDynLtgPrmForLedCornrgLampLeOffsTiPrm DwnLoadDynLtgPrmForLedCornrgLampLeTistamp DwnLoadDynLtgPrmForLedCornrgLampLeUpprBriPrm;
SIG_GROUP_ 316 DwnLoadDynLtgPrmForLedCornrgLampRi 1 : DwnLoadDynLtgPrmForLedCornrgLampRiContTiPrm DwnLoadDynLtgPrmForLedCornrgLampRiLowBriPrm DwnLoadDynLtgPrmForLedCornrgLampRiModePrm DwnLoadDynLtgPrmForLedCornrgLampRiOffsTiPrm DwnLoadDynLtgPrmForLedCornrgLampRiTistamp DwnLoadDynLtgPrmForLedCornrgLampRiUpprBriPrm;
SIG_GROUP_ 317 DwnLoadDynLtgPrmForLedDaytiRunngLampLe 1 : DwnLoadDynLtgPrmForLedDaytiRunngLampLeContTiPrm DwnLoadDynLtgPrmForLedDaytiRunngLampLeLowBriPrm DwnLoadDynLtgPrmForLedDaytiRunngLampLeModePrm DwnLoadDynLtgPrmForLedDaytiRunngLampLeOffsTiPrm DwnLoadDynLtgPrmForLedDaytiRunngLampLeTistamp DwnLoadDynLtgPrmForLedDaytiRunngLampLeUpprBriPrm;
SIG_GROUP_ 318 DwnLoadDynLtgPrmForLedDaytiRunngLampRi 1 : DwnLoadDynLtgPrmForLedDaytiRunngLampRiContTiPrm DwnLoadDynLtgPrmForLedDaytiRunngLampRiLowBriPrm DwnLoadDynLtgPrmForLedDaytiRunngLampRiModePrm DwnLoadDynLtgPrmForLedDaytiRunngLampRiOffsTiPrm DwnLoadDynLtgPrmForLedDaytiRunngLampRiTistamp DwnLoadDynLtgPrmForLedDaytiRunngLampRiUpprBriPrm;
SIG_GROUP_ 319 DwnLoadDynLtgPrmForLedFrntPosnLampLe 1 : DwnLoadDynLtgPrmForLedFrntPosnLampLeContTiPrm DwnLoadDynLtgPrmForLedFrntPosnLampLeLowBriPrm DwnLoadDynLtgPrmForLedFrntPosnLampLeModePrm DwnLoadDynLtgPrmForLedFrntPosnLampLeOffsTiPrm DwnLoadDynLtgPrmForLedFrntPosnLampLeTistamp DwnLoadDynLtgPrmForLedFrntPosnLampLeUpprBriPrm;
SIG_GROUP_ 320 DwnLoadDynLtgPrmForLedFrntPosnLampRi 1 : DwnLoadDynLtgPrmForLedFrntPosnLampRiContTiPrm DwnLoadDynLtgPrmForLedFrntPosnLampRiLowBriPrm DwnLoadDynLtgPrmForLedFrntPosnLampRiModePrm DwnLoadDynLtgPrmForLedFrntPosnLampRiOffsTiPrm DwnLoadDynLtgPrmForLedFrntPosnLampRiTistamp DwnLoadDynLtgPrmForLedFrntPosnLampRiUpprBriPrm;
SIG_GROUP_ 321 DwnLoadDynLtgPrmForLedFrntTurnIndcrLe 1 : DwnLoadDynLtgPrmForLedFrntTurnIndcrLeContTiPrm DwnLoadDynLtgPrmForLedFrntTurnIndcrLeLowBriPrm DwnLoadDynLtgPrmForLedFrntTurnIndcrLeModePrm DwnLoadDynLtgPrmForLedFrntTurnIndcrLeOffsTiPrm DwnLoadDynLtgPrmForLedFrntTurnIndcrLeTistamp DwnLoadDynLtgPrmForLedFrntTurnIndcrLeUpprBriPrm;
SIG_GROUP_ 322 DwnLoadDynLtgPrmForLedFrntTurnIndcrRi 1 : DwnLoadDynLtgPrmForLedFrntTurnIndcrRiContTiPrm DwnLoadDynLtgPrmForLedFrntTurnIndcrRiLowBriPrm DwnLoadDynLtgPrmForLedFrntTurnIndcrRiModePrm DwnLoadDynLtgPrmForLedFrntTurnIndcrRiOffsTiPrm DwnLoadDynLtgPrmForLedFrntTurnIndcrRiTistamp DwnLoadDynLtgPrmForLedFrntTurnIndcrRiUpprBriPrm;
SIG_GROUP_ 323 DwnLoadDynLtgPrmForLedHiBeamRi 1 : DwnLoadDynLtgPrmForLedHiBeamRiContTiPrm DwnLoadDynLtgPrmForLedHiBeamRiLowBriPrm DwnLoadDynLtgPrmForLedHiBeamRiModePrm DwnLoadDynLtgPrmForLedHiBeamRiOffsTiPrm DwnLoadDynLtgPrmForLedHiBeamRiTistamp DwnLoadDynLtgPrmForLedHiBeamRiUpprBriPrm;
SIG_GROUP_ 538 IndcrPat 1 : IndcrPatCmd1WdTiOff IndcrPatCmd1WdTiOn;
SIG_GROUP_ 120 LvlgSwtSetReq 1 : LvlgSwtSetReqADModCtrlInhbn LvlgSwtSetReqChks LvlgSwtSetReqCntr;
SIG_GROUP_ 120 OutdBri 1 : OutdBriChks OutdBriCntr OutdBriSts;
SIG_GROUP_ 523 RoadIncln 1 : RoadInclnQly RoadInclnRoadIncln;
SIG_GROUP_ 523 RollAgGlb 1 : RollAgGlbQf RollAgGlbVal;
SIG_GROUP_ 612 WipgInfo 1 : WipgInfoWipgSpdInfo WipgInfoWiprActv WipgInfoWiprInWipgAr;
